VERSION "HNNBNNNYNNNNNNNNNNNNNNNNNNNNNNNNNNNNNNNNNN/4/%%%/4/'%**4NNN///"

NS_ :

BS_:

BU_: AEM BAP_Tester E_Sound FBK FLA Gateway Gateway_PAG ISE MRR_HL MRR_HR NightVision RDK SAK SAK2 SCR STH_MLBevo TopView

BO_ 1646 Klima_03: 8 Gateway
 SG_ KL_STL_aktiv : 0|1@1+ (1.0,0.0) [0.0|1] ""  STH_MLBevo
 SG_ KL_STH_aktiv : 1|1@1+ (1.0,0.0) [0.0|1] ""  STH_MLBevo
 SG_ KL_Solarluefter_aktiv : 2|1@1+ (1.0,0.0) [0.0|1] ""  Vector__XXX
 SG_ KL_Umluft_Taste : 3|1@1+ (1.0,0.0) [0.0|1] ""  Vector__XXX
 SG_ KL_Geblaese_Fond_Status : 4|4@1+ (1.0,0.0) [0.0|15] ""  Vector__XXX
 SG_ KL_STH_Ansteuerung : 8|2@1+ (1.0,0.0) [0.0|3] ""  STH_MLBevo
 SG_ KL_STH_Betriebsdauer : 10|6@1+ (1,0) [0|60] "Unit_Minut"  STH_MLBevo
 SG_ KL_Magnetventil : 16|1@1+ (1.0,0.0) [0.0|1] ""  Vector__XXX
 SG_ KL_WaPu : 17|1@1+ (1.0,0.0) [0.0|1] ""  Vector__XXX
 SG_ KL_Geblaese_Status : 18|4@1+ (1.0,0.0) [0.0|15] ""  Vector__XXX
 SG_ KL_Restwaerme_aktiv : 22|1@1+ (1.0,0.0) [0.0|1] ""  STH_MLBevo
 SG_ KL_Kompressorkupplung : 23|1@1+ (1.0,0.0) [0.0|1] ""  Vector__XXX
 SG_ KL_BCmE_Livetip_Freigabe : 24|1@1+ (1.0,0.0) [0.0|1] ""  Vector__XXX
 SG_ KL_HYB_ASV_hinten_schliessen_Anf : 25|1@1+ (1.0,0.0) [0.0|1] ""  Vector__XXX
 SG_ KL_HYB_ASV_vorne_schliessen_Anf : 26|1@1+ (1.0,0.0) [0.0|1] ""  Vector__XXX
 SG_ KL_ErwVK_Zusatzrelais : 27|1@1+ (1.0,0.0) [0.0|1] ""  Vector__XXX
 SG_ KL_Status_Beduftung : 28|1@1+ (1.0,0.0) [0.0|1] ""  Vector__XXX
 SG_ KL_Status_Ionisator_Front : 29|1@1+ (1.0,0.0) [0.0|1] ""  Vector__XXX
 SG_ KL_STH_Timer_Status : 30|1@1+ (1.0,0.0) [0.0|1] ""  Vector__XXX
 SG_ KL_ErwVK_Anf : 31|1@1+ (1.0,0.0) [0.0|1] ""  Vector__XXX
 SG_ KL_Innen_Temp : 32|8@1+ (0.5,-50) [-50.0|76.0] "Unit_DegreCelsi"  Vector__XXX
 SG_ KL_I_Geblaese_Fond : 40|8@1+ (0.25,0) [0.00|63.50] "Unit_Amper"  Vector__XXX
 SG_ KL_Anf_AussenspiegelHzg : 48|1@1+ (1.0,0.0) [0.0|1] ""  Vector__XXX
 SG_ KL_Heizkreisventilstellung : 49|2@1+ (1.0,0.0) [0.0|3] ""  Vector__XXX
 SG_ KL_FSH_Automatikbetrieb : 51|1@1+ (1.0,0.0) [0.0|1] ""  Vector__XXX
 SG_ KL_SIH_LEH_Verteilung_VL : 52|3@1+ (1.0,0.0) [0.0|7] ""  Vector__XXX
 SG_ KL_SIH_LEL_Verteilung_VL : 55|3@1+ (1.0,0.0) [0.0|7] ""  Vector__XXX
 SG_ KL_SIH_LEH_Verteilung_VR : 58|3@1+ (1.0,0.0) [0.0|7] ""  Vector__XXX
 SG_ KL_SIH_LEL_Verteilung_VR : 61|3@1+ (1.0,0.0) [0.0|7] ""  Vector__XXX

BO_ 1649 Klima_06: 8 Gateway
 SG_ KL_ZZ_Minute : 0|6@1+ (1,0) [0|59] "Unit_Minut"  STH_MLBevo
 SG_ KL_ZZ_Status_Timer : 6|2@1+ (1.0,0.0) [0.0|3] ""  STH_MLBevo
 SG_ KL_ZZ_Monat : 8|4@1+ (1,0) [1|12] "Unit_Month"  STH_MLBevo
 SG_ KL_ZZ_Stunde : 16|5@1+ (1,0) [0|23] "Unit_Hours"  STH_MLBevo
 SG_ KL_ZZ_Betriebsmodus : 21|3@1+ (1.0,0.0) [0.0|7] ""  STH_MLBevo
 SG_ KL_ZZ_Tag : 24|5@1+ (1,0) [1|31] "Unit_Day"  STH_MLBevo
 SG_ KL_Betriebsmodus_FH : 29|3@1+ (1.0,0.0) [0.0|7] ""  Vector__XXX
 SG_ KL_Stopp_Wiederstart_Anz_01 : 32|1@1+ (1.0,0.0) [0.0|1] ""  Vector__XXX
 SG_ KL_Stopp_Wiederstart_Anz_02 : 33|1@1+ (1.0,0.0) [0.0|1] ""  Vector__XXX
 SG_ KL_Stopp_Wiederstart_Anz_03 : 34|1@1+ (1.0,0.0) [0.0|1] ""  Vector__XXX
 SG_ KL_Stopp_Wiederstart_Anz_04 : 35|1@1+ (1.0,0.0) [0.0|1] ""  Vector__XXX
 SG_ KL_Stopp_Wiederstart_Anz_05 : 36|1@1+ (1.0,0.0) [0.0|1] ""  Vector__XXX
 SG_ KL_Stopp_Wiederstart_Anz_06 : 37|1@1+ (1.0,0.0) [0.0|1] ""  Vector__XXX
 SG_ KL_Stopp_Wiederstart_Anz_07 : 38|1@1+ (1.0,0.0) [0.0|1] ""  Vector__XXX
 SG_ KL_Stopp_Wiederstart_Anz_08 : 39|1@1+ (1.0,0.0) [0.0|1] ""  Vector__XXX
 SG_ KL_Stopp_Wiederstart_Anz_09 : 40|1@1+ (1.0,0.0) [0.0|1] ""  Vector__XXX
 SG_ KL_Stopp_Wiederstart_Anz_Std1 : 41|1@1+ (1.0,0.0) [0.0|1] ""  Vector__XXX
 SG_ KL_Stopp_Wiederstart_Anz_Std2 : 42|1@1+ (1.0,0.0) [0.0|1] ""  Vector__XXX

BO_ 949 Klima_11: 8 Gateway
 SG_ KL_Drehz_Anh : 0|1@1+ (1.0,0.0) [0.0|1] ""  Vector__XXX
 SG_ KL_Vorwarn_Komp_ein : 1|1@1+ (1.0,0.0) [0.0|1] ""  Vector__XXX
 SG_ KL_AC_Schalter : 2|1@1+ (1.0,0.0) [0.0|1] ""  Vector__XXX
 SG_ KL_Komp_Moment_alt : 3|1@1+ (1.0,0.0) [0.0|1] ""  Vector__XXX
 SG_ KL_Vorwarn_Zuheizer_ein : 6|1@1+ (1.0,0.0) [0.0|1] ""  Vector__XXX
 SG_ KL_Zustand : 7|1@1+ (1.0,0.0) [0.0|1] ""  Vector__XXX
 SG_ KL_Kompressorkupplung_linear : 8|8@1+ (20,0) [0|4000] "Unit_MilliAmper"  Vector__XXX
 SG_ KL_Charisma_FahrPr : 16|4@1+ (1.0,0.0) [0.0|15] ""  Vector__XXX
 SG_ KL_Charisma_Status : 20|2@1+ (1.0,0.0) [0.0|3] ""  Vector__XXX
 SG_ KL_nachtr_Stopp_Anf : 22|1@1+ (1.0,0.0) [0.0|1] ""  Vector__XXX
 SG_ KL_T_Charge : 23|1@1+ (1.0,0.0) [0.0|1] ""  Vector__XXX
 SG_ KL_Last_Kompr : 24|8@1+ (0.25,0) [0.00|63.50] "Unit_NewtoMeter"  Vector__XXX
 SG_ KL_Spannungs_Anf : 32|2@1+ (1.0,0.0) [0.0|3] ""  Vector__XXX
 SG_ KL_Thermomanagement : 34|2@1+ (1.0,0.0) [0.0|3] ""  STH_MLBevo
 SG_ KL_StartStopp_Info : 36|2@1+ (1.0,0.0) [0.0|3] ""  Vector__XXX
 SG_ KL_Freilauf_Info : 38|2@1+ (1.0,0.0) [0.0|3] ""  Vector__XXX
 SG_ KL_Anf_KL : 40|8@1+ (0.4,0) [0.0|101.6] "Unit_PerCent"  Vector__XXX
 SG_ KL_el_Zuheizer_Stufe : 48|3@1+ (1.0,0.0) [0.0|7] ""  Vector__XXX
 SG_ KL_Ausstattung_Klima : 51|3@1+ (1.0,0.0) [0.0|7] ""  Vector__XXX
 SG_ KL_Variante_Standheizung : 54|2@1+ (1.0,0.0) [0.0|3] ""  Vector__XXX

BO_ 1640 Klima_12: 8 Gateway
 SG_ KL_LRH_Taster : 0|1@1+ (1.0,0.0) [0.0|1] ""  Vector__XXX
 SG_ KL_LRH_Stufe : 1|2@1+ (1.0,0.0) [0.0|3] ""  Vector__XXX
 SG_ HSH_Taster : 3|2@1+ (1.0,0.0) [0.0|3] ""  Vector__XXX
 SG_ FSH_Taster : 5|1@1+ (1.0,0.0) [0.0|1] ""  Vector__XXX
 SG_ KL_Zuheizer_Freigabe : 6|1@1+ (1.0,0.0) [0.0|1] ""  STH_MLBevo
 SG_ KL_Beschlagsgefahr : 7|1@1+ (1.0,0.0) [0.0|1] ""  Vector__XXX
 SG_ KL_SIH_Soll_li : 8|3@1+ (1,0) [0|6] ""  Vector__XXX
 SG_ KL_SIH_Soll_re : 11|3@1+ (1,0) [0|6] ""  Vector__XXX
 SG_ KRH_Soll_li : 14|2@1+ (1.0,0.0) [0.0|3] ""  Vector__XXX
 SG_ KL_SIL_Soll_li : 16|3@1+ (1,0) [0|6] ""  Vector__XXX
 SG_ KL_SIL_Soll_re : 19|3@1+ (1,0) [0|6] ""  Vector__XXX
 SG_ KRH_Soll_re : 22|2@1+ (1.0,0.0) [0.0|3] ""  Vector__XXX
 SG_ KL_Geblspng_Soll : 24|8@1+ (0.05,1.45) [1.50|14.00] "Unit_Volt"  Vector__XXX
 SG_ KL_Geblspng_Fond_Soll : 32|8@1+ (0.05,1.45) [1.50|14.00] "Unit_Volt"  Vector__XXX
 SG_ KL_I_Geblaese : 40|8@1+ (0.25,0) [0.00|63.50] "Unit_Amper"  Vector__XXX
 SG_ KL_Kompressorstrom_soll : 48|10@1+ (1,0) [0|1021] ""  Vector__XXX
 SG_ KL_Umluftklappe_Status : 58|4@1+ (1.0,0.0) [0.0|15] ""  Vector__XXX
 SG_ KL_PTC_Verbauinfo : 62|2@1+ (1.0,0.0) [0.0|3] ""  Vector__XXX

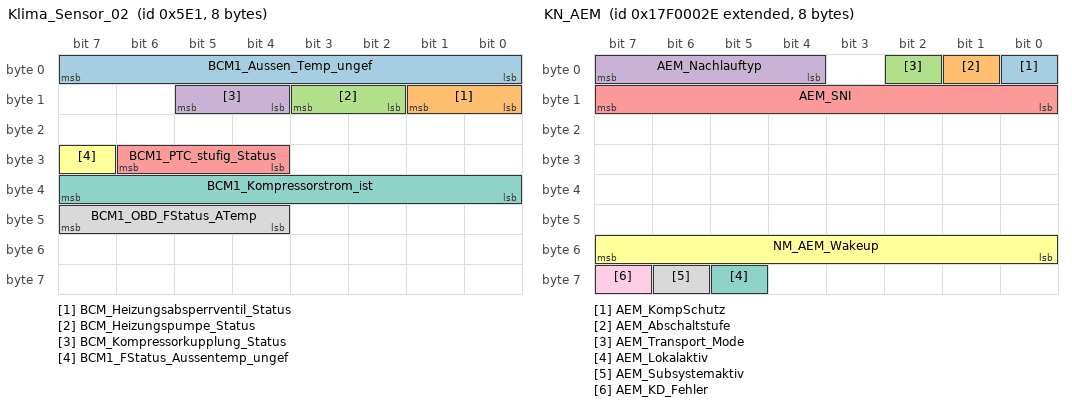
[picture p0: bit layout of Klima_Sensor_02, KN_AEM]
BO_ 1505 Klima_Sensor_02: 8 Gateway
 SG_ BCM1_Aussen_Temp_ungef : 0|8@1+ (0.5,-50) [-50.0|76.0] "Unit_DegreCelsi"  MRR_HL,STH_MLBevo,TopView
 SG_ BCM_Heizungsabsperrventil_Status : 8|2@1+ (1.0,0.0) [0.0|3] ""  Vector__XXX
 SG_ BCM_Heizungspumpe_Status : 10|2@1+ (1.0,0.0) [0.0|3] ""  Vector__XXX
 SG_ BCM_Kompressorkupplung_Status : 12|2@1+ (1.0,0.0) [0.0|3] ""  Vector__XXX
 SG_ BCM1_PTC_stufig_Status : 28|3@1+ (1.0,0.0) [0.0|7] ""  Vector__XXX
 SG_ BCM1_FStatus_Aussentemp_ungef : 31|1@1+ (1.0,0.0) [0.0|1] ""  Vector__XXX
 SG_ BCM1_Kompressorstrom_ist : 32|8@1+ (4,0) [0|1000] "Unit_MilliAmper"  Vector__XXX
 SG_ BCM1_OBD_FStatus_ATemp : 44|4@1+ (1.0,0.0) [0.0|15] ""  Vector__XXX

BO_ 2549088302 KN_AEM: 8 AEM
 SG_ AEM_KompSchutz : 0|1@1+ (1.0,0.0) [0.0|1] ""  Vector__XXX
 SG_ AEM_Abschaltstufe : 1|1@1+ (1.0,0.0) [0.0|1] ""  Vector__XXX
 SG_ AEM_Transport_Mode : 2|1@1+ (1.0,0.0) [0.0|1] ""  Vector__XXX
 SG_ AEM_Nachlauftyp : 4|4@1+ (1.0,0.0) [0.0|15] ""  Gateway,Gateway_PAG
 SG_ AEM_SNI : 8|8@1+ (1.0,0.0) [0.0|255] ""  Gateway,Gateway_PAG
 SG_ NM_AEM_Wakeup : 48|8@1+ (1.0,0.0) [0.0|255] ""  Vector__XXX
 SG_ AEM_Lokalaktiv : 61|1@1+ (1.0,0.0) [0.0|1] ""  Gateway,Gateway_PAG
 SG_ AEM_Subsystemaktiv : 62|1@1+ (1.0,0.0) [0.0|1] ""  Vector__XXX
 SG_ AEM_KD_Fehler : 63|1@1+ (1.0,0.0) [0.0|1] ""  Gateway,Gateway_PAG

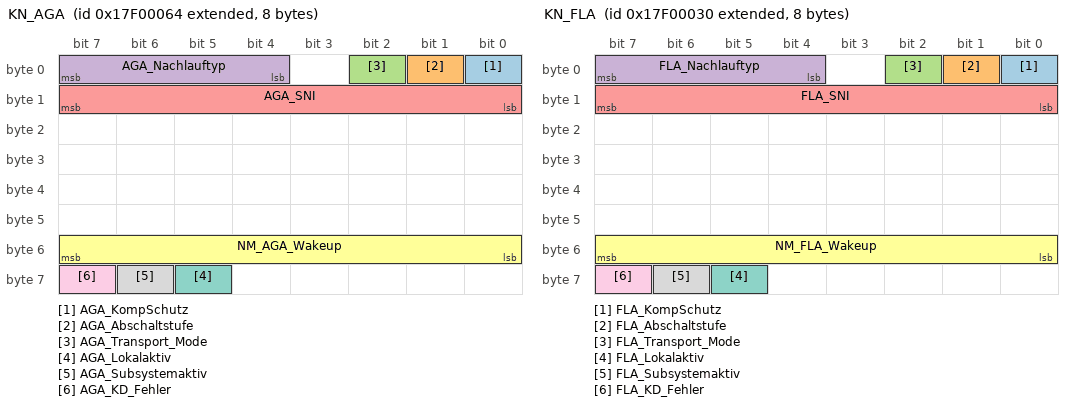
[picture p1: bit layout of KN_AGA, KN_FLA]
BO_ 2549088356 KN_AGA: 8 E_Sound
 SG_ AGA_KompSchutz : 0|1@1+ (1.0,0.0) [0.0|1] ""  Vector__XXX
 SG_ AGA_Abschaltstufe : 1|1@1+ (1.0,0.0) [0.0|1] ""  Vector__XXX
 SG_ AGA_Transport_Mode : 2|1@1+ (1.0,0.0) [0.0|1] ""  Vector__XXX
 SG_ AGA_Nachlauftyp : 4|4@1+ (1.0,0.0) [0.0|15] ""  Gateway,Gateway_PAG
 SG_ AGA_SNI : 8|8@1+ (1.0,0.0) [0.0|255] ""  Gateway,Gateway_PAG
 SG_ NM_AGA_Wakeup : 48|8@1+ (1.0,0.0) [0.0|255] ""  Vector__XXX
 SG_ AGA_Lokalaktiv : 61|1@1+ (1.0,0.0) [0.0|1] ""  Vector__XXX
 SG_ AGA_Subsystemaktiv : 62|1@1+ (1.0,0.0) [0.0|1] ""  Vector__XXX
 SG_ AGA_KD_Fehler : 63|1@1+ (1.0,0.0) [0.0|1] ""  Gateway,Gateway_PAG

BO_ 2549088304 KN_FLA: 8 FLA
 SG_ FLA_KompSchutz : 0|1@1+ (1.0,0.0) [0.0|1] ""  Vector__XXX
 SG_ FLA_Abschaltstufe : 1|1@1+ (1.0,0.0) [0.0|1] ""  Vector__XXX
 SG_ FLA_Transport_Mode : 2|1@1+ (1.0,0.0) [0.0|1] ""  Vector__XXX
 SG_ FLA_Nachlauftyp : 4|4@1+ (1.0,0.0) [0.0|15] ""  Gateway,Gateway_PAG
 SG_ FLA_SNI : 8|8@1+ (1.0,0.0) [0.0|255] ""  Gateway,Gateway_PAG
 SG_ NM_FLA_Wakeup : 48|8@1+ (1.0,0.0) [0.0|255] ""  Vector__XXX
 SG_ FLA_Lokalaktiv : 61|1@1+ (1.0,0.0) [0.0|1] ""  Vector__XXX
 SG_ FLA_Subsystemaktiv : 62|1@1+ (1.0,0.0) [0.0|1] ""  Vector__XXX
 SG_ FLA_KD_Fehler : 63|1@1+ (1.0,0.0) [0.0|1] ""  Gateway,Gateway_PAG

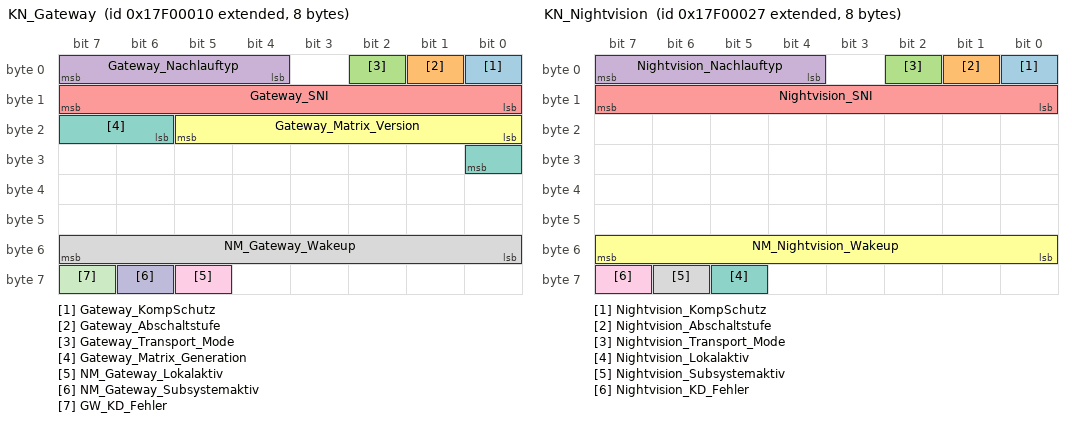
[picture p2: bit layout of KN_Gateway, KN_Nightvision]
BO_ 2549088272 KN_Gateway: 8 Gateway
 SG_ Gateway_KompSchutz : 0|1@1+ (1.0,0.0) [0.0|1] ""  Vector__XXX
 SG_ Gateway_Abschaltstufe : 1|1@1+ (1.0,0.0) [0.0|1] ""  Vector__XXX
 SG_ Gateway_Transport_Mode : 2|1@1+ (1.0,0.0) [0.0|1] ""  Vector__XXX
 SG_ Gateway_Nachlauftyp : 4|4@1+ (1.0,0.0) [0.0|15] ""  Vector__XXX
 SG_ Gateway_SNI : 8|8@1+ (1.0,0.0) [0.0|255] ""  Vector__XXX
 SG_ Gateway_Matrix_Version : 16|6@1+ (1,0) [0|63] "Unit_None"  Vector__XXX
 SG_ Gateway_Matrix_Generation : 22|3@1+ (1,0) [0|7] "Unit_None"  Vector__XXX
 SG_ NM_Gateway_Wakeup : 48|8@1+ (1.0,0.0) [0.0|255] ""  Vector__XXX
 SG_ NM_Gateway_Lokalaktiv : 61|1@1+ (1.0,0.0) [0.0|1] ""  Vector__XXX
 SG_ NM_Gateway_Subsystemaktiv : 62|1@1+ (1.0,0.0) [0.0|1] ""  Vector__XXX
 SG_ GW_KD_Fehler : 63|1@1+ (1.0,0.0) [0.0|1] ""  Vector__XXX

BO_ 2549088295 KN_Nightvision: 8 NightVision
 SG_ Nightvision_KompSchutz : 0|1@1+ (1.0,0.0) [0.0|1] ""  Vector__XXX
 SG_ Nightvision_Abschaltstufe : 1|1@1+ (1.0,0.0) [0.0|1] ""  Vector__XXX
 SG_ Nightvision_Transport_Mode : 2|1@1+ (1.0,0.0) [0.0|1] ""  Vector__XXX
 SG_ Nightvision_Nachlauftyp : 4|4@1+ (1.0,0.0) [0.0|15] ""  Gateway,Gateway_PAG
 SG_ Nightvision_SNI : 8|8@1+ (1.0,0.0) [0.0|255] ""  Gateway,Gateway_PAG
 SG_ NM_Nightvision_Wakeup : 48|8@1+ (1.0,0.0) [0.0|255] ""  Vector__XXX
 SG_ Nightvision_Lokalaktiv : 61|1@1+ (1.0,0.0) [0.0|1] ""  Vector__XXX
 SG_ Nightvision_Subsystemaktiv : 62|1@1+ (1.0,0.0) [0.0|1] ""  Vector__XXX
 SG_ Nightvision_KD_Fehler : 63|1@1+ (1.0,0.0) [0.0|1] ""  Gateway,Gateway_PAG

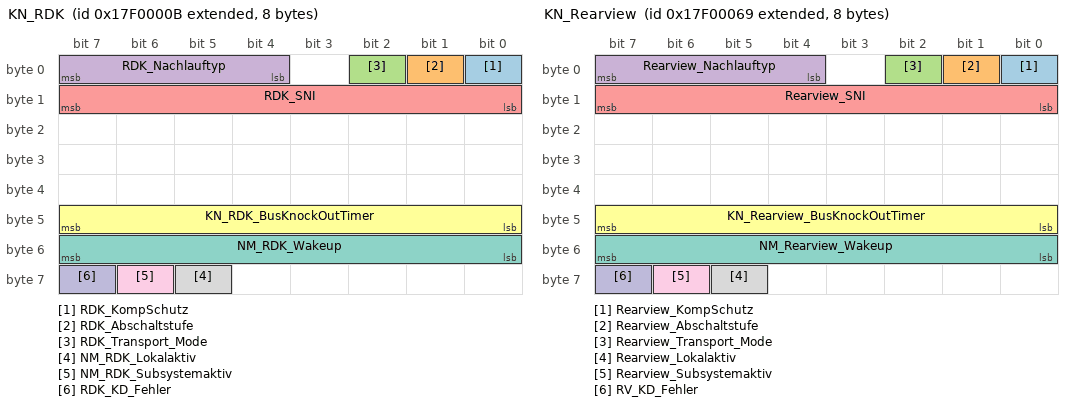
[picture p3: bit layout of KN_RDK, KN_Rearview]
BO_ 2549088267 KN_RDK: 8 RDK
 SG_ RDK_KompSchutz : 0|1@1+ (1.0,0.0) [0.0|1] ""  Vector__XXX
 SG_ RDK_Abschaltstufe : 1|1@1+ (1.0,0.0) [0.0|1] ""  Vector__XXX
 SG_ RDK_Transport_Mode : 2|1@1+ (1.0,0.0) [0.0|1] ""  Vector__XXX
 SG_ RDK_Nachlauftyp : 4|4@1+ (1.0,0.0) [0.0|15] ""  Gateway,Gateway_PAG
 SG_ RDK_SNI : 8|8@1+ (1.0,0.0) [0.0|255] ""  Gateway,Gateway_PAG
 SG_ KN_RDK_BusKnockOutTimer : 40|8@1+ (1,0) [0|254] ""  Gateway,Gateway_PAG
 SG_ NM_RDK_Wakeup : 48|8@1+ (1.0,0.0) [0.0|255] ""  Vector__XXX
 SG_ NM_RDK_Lokalaktiv : 61|1@1+ (1.0,0.0) [0.0|1] ""  Gateway,Gateway_PAG
 SG_ NM_RDK_Subsystemaktiv : 62|1@1+ (1.0,0.0) [0.0|1] ""  Vector__XXX
 SG_ RDK_KD_Fehler : 63|1@1+ (1.0,0.0) [0.0|1] ""  Gateway,Gateway_PAG

BO_ 2549088361 KN_Rearview: 8 TopView
 SG_ Rearview_KompSchutz : 0|1@1+ (1.0,0.0) [0.0|1] ""  Vector__XXX
 SG_ Rearview_Abschaltstufe : 1|1@1+ (1.0,0.0) [0.0|1] ""  Vector__XXX
 SG_ Rearview_Transport_Mode : 2|1@1+ (1.0,0.0) [0.0|1] ""  Vector__XXX
 SG_ Rearview_Nachlauftyp : 4|4@1+ (1.0,0.0) [0.0|15] ""  Gateway,Gateway_PAG
 SG_ Rearview_SNI : 8|8@1+ (1.0,0.0) [0.0|255] ""  Gateway,Gateway_PAG
 SG_ KN_Rearview_BusKnockOutTimer : 40|8@1+ (1,0) [0|254] ""  Gateway,Gateway_PAG
 SG_ NM_Rearview_Wakeup : 48|8@1+ (1.0,0.0) [0.0|255] ""  Vector__XXX
 SG_ Rearview_Lokalaktiv : 61|1@1+ (1.0,0.0) [0.0|1] ""  Gateway,Gateway_PAG
 SG_ Rearview_Subsystemaktiv : 62|1@1+ (1.0,0.0) [0.0|1] ""  Vector__XXX
 SG_ RV_KD_Fehler : 63|1@1+ (1.0,0.0) [0.0|1] ""  Gateway,Gateway_PAG

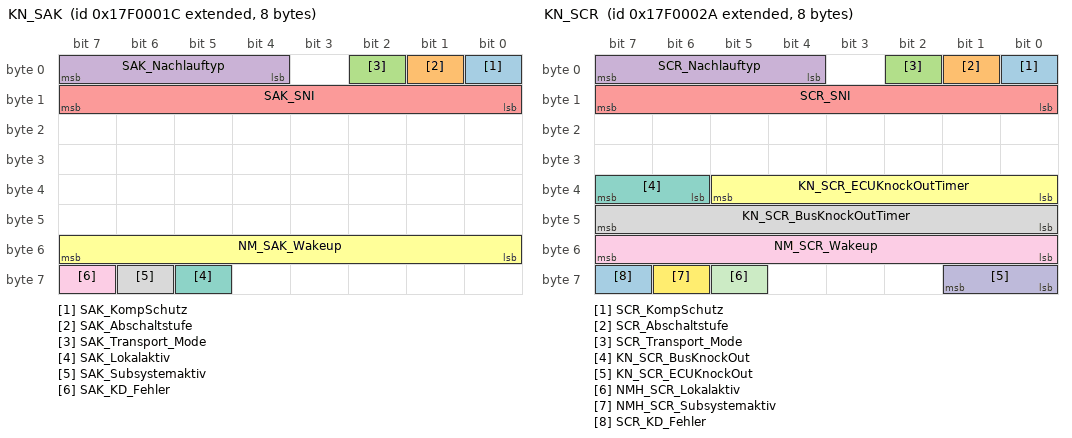
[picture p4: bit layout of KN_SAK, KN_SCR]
BO_ 2549088284 KN_SAK: 8 ISE
 SG_ SAK_KompSchutz : 0|1@1+ (1.0,0.0) [0.0|1] ""  Vector__XXX
 SG_ SAK_Abschaltstufe : 1|1@1+ (1.0,0.0) [0.0|1] ""  Vector__XXX
 SG_ SAK_Transport_Mode : 2|1@1+ (1.0,0.0) [0.0|1] ""  Vector__XXX
 SG_ SAK_Nachlauftyp : 4|4@1+ (1.0,0.0) [0.0|15] ""  Gateway,Gateway_PAG
 SG_ SAK_SNI : 8|8@1+ (1.0,0.0) [0.0|255] ""  Gateway,Gateway_PAG
 SG_ NM_SAK_Wakeup : 48|8@1+ (1.0,0.0) [0.0|255] ""  Vector__XXX
 SG_ SAK_Lokalaktiv : 61|1@1+ (1.0,0.0) [0.0|1] ""  Vector__XXX
 SG_ SAK_Subsystemaktiv : 62|1@1+ (1.0,0.0) [0.0|1] ""  Vector__XXX
 SG_ SAK_KD_Fehler : 63|1@1+ (1.0,0.0) [0.0|1] ""  Gateway,Gateway_PAG

BO_ 2549088298 KN_SCR: 8 SCR
 SG_ SCR_KompSchutz : 0|1@1+ (1.0,0.0) [0.0|1] ""  Vector__XXX
 SG_ SCR_Abschaltstufe : 1|1@1+ (1.0,0.0) [0.0|1] ""  Vector__XXX
 SG_ SCR_Transport_Mode : 2|1@1+ (1.0,0.0) [0.0|1] ""  Vector__XXX
 SG_ SCR_Nachlauftyp : 4|4@1+ (1.0,0.0) [0.0|15] ""  Gateway,Gateway_PAG
 SG_ SCR_SNI : 8|8@1+ (1.0,0.0) [0.0|255] ""  Gateway,Gateway_PAG
 SG_ KN_SCR_ECUKnockOutTimer : 32|6@1+ (1,0) [0|62] ""  Vector__XXX
 SG_ KN_SCR_BusKnockOut : 38|2@1+ (1.0,0.0) [0.0|3] ""  Vector__XXX
 SG_ KN_SCR_BusKnockOutTimer : 40|8@1+ (1,0) [0|254] ""  Gateway,Gateway_PAG
 SG_ NM_SCR_Wakeup : 48|8@1+ (1.0,0.0) [0.0|255] ""  Vector__XXX
 SG_ KN_SCR_ECUKnockOut : 56|2@1+ (1.0,0.0) [0.0|3] ""  Vector__XXX
 SG_ NMH_SCR_Lokalaktiv : 61|1@1+ (1.0,0.0) [0.0|1] ""  Gateway,Gateway_PAG
 SG_ NMH_SCR_Subsystemaktiv : 62|1@1+ (1.0,0.0) [0.0|1] ""  Vector__XXX
 SG_ SCR_KD_Fehler : 63|1@1+ (1.0,0.0) [0.0|1] ""  Gateway,Gateway_PAG

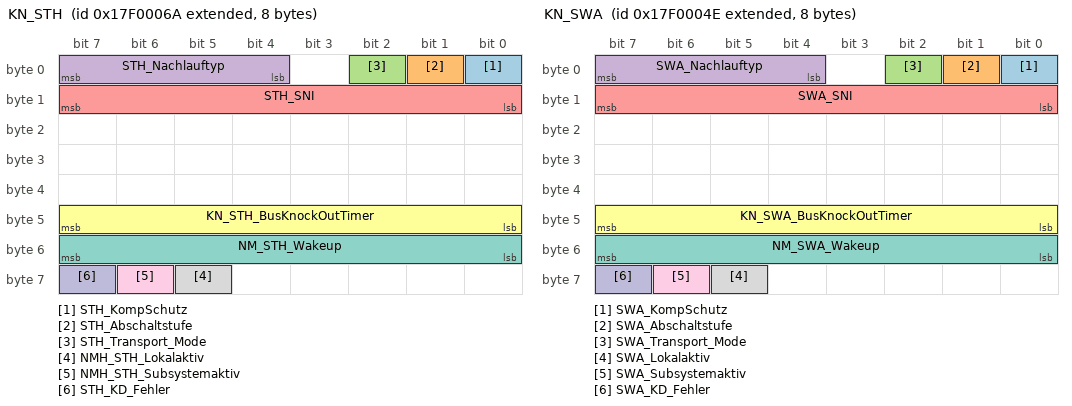
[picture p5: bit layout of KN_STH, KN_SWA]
BO_ 2549088362 KN_STH: 8 STH_MLBevo
 SG_ STH_KompSchutz : 0|1@1+ (1.0,0.0) [0.0|1] ""  Vector__XXX
 SG_ STH_Abschaltstufe : 1|1@1+ (1.0,0.0) [0.0|1] ""  Vector__XXX
 SG_ STH_Transport_Mode : 2|1@1+ (1.0,0.0) [0.0|1] ""  Vector__XXX
 SG_ STH_Nachlauftyp : 4|4@1+ (1.0,0.0) [0.0|15] ""  Gateway,Gateway_PAG
 SG_ STH_SNI : 8|8@1+ (1.0,0.0) [0.0|255] ""  Gateway,Gateway_PAG
 SG_ KN_STH_BusKnockOutTimer : 40|8@1+ (1,0) [0|254] ""  Gateway,Gateway_PAG
 SG_ NM_STH_Wakeup : 48|8@1+ (1.0,0.0) [0.0|255] ""  Vector__XXX
 SG_ NMH_STH_Lokalaktiv : 61|1@1+ (1.0,0.0) [0.0|1] ""  Gateway,Gateway_PAG
 SG_ NMH_STH_Subsystemaktiv : 62|1@1+ (1.0,0.0) [0.0|1] ""  Gateway,Gateway_PAG
 SG_ STH_KD_Fehler : 63|1@1+ (1.0,0.0) [0.0|1] ""  Gateway,Gateway_PAG

BO_ 2549088334 KN_SWA: 8 MRR_HR
 SG_ SWA_KompSchutz : 0|1@1+ (1.0,0.0) [0.0|1] ""  Vector__XXX
 SG_ SWA_Abschaltstufe : 1|1@1+ (1.0,0.0) [0.0|1] ""  Vector__XXX
 SG_ SWA_Transport_Mode : 2|1@1+ (1.0,0.0) [0.0|1] ""  Vector__XXX
 SG_ SWA_Nachlauftyp : 4|4@1+ (1.0,0.0) [0.0|15] ""  Gateway,Gateway_PAG
 SG_ SWA_SNI : 8|8@1+ (1.0,0.0) [0.0|255] ""  Gateway,Gateway_PAG
 SG_ KN_SWA_BusKnockOutTimer : 40|8@1+ (1,0) [0|254] ""  Gateway,Gateway_PAG
 SG_ NM_SWA_Wakeup : 48|8@1+ (1.0,0.0) [0.0|255] ""  Vector__XXX
 SG_ SWA_Lokalaktiv : 61|1@1+ (1.0,0.0) [0.0|1] ""  Gateway,Gateway_PAG
 SG_ SWA_Subsystemaktiv : 62|1@1+ (1.0,0.0) [0.0|1] ""  Vector__XXX
 SG_ SWA_KD_Fehler : 63|1@1+ (1.0,0.0) [0.0|1] ""  Gateway,Gateway_PAG

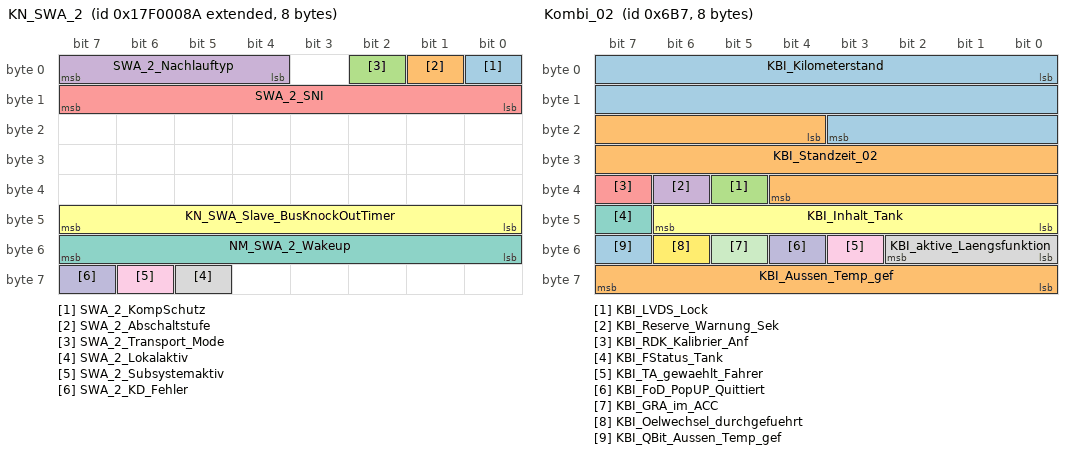
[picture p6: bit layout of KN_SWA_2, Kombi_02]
BO_ 2549088394 KN_SWA_2: 8 MRR_HL
 SG_ SWA_2_KompSchutz : 0|1@1+ (1.0,0.0) [0.0|1] ""  Vector__XXX
 SG_ SWA_2_Abschaltstufe : 1|1@1+ (1.0,0.0) [0.0|1] ""  Vector__XXX
 SG_ SWA_2_Transport_Mode : 2|1@1+ (1.0,0.0) [0.0|1] ""  Vector__XXX
 SG_ SWA_2_Nachlauftyp : 4|4@1+ (1.0,0.0) [0.0|15] ""  Gateway,Gateway_PAG
 SG_ SWA_2_SNI : 8|8@1+ (1.0,0.0) [0.0|255] ""  Gateway,Gateway_PAG
 SG_ KN_SWA_Slave_BusKnockOutTimer : 40|8@1+ (1,0) [0|254] ""  Gateway,Gateway_PAG
 SG_ NM_SWA_2_Wakeup : 48|8@1+ (1.0,0.0) [0.0|255] ""  Vector__XXX
 SG_ SWA_2_Lokalaktiv : 61|1@1+ (1.0,0.0) [0.0|1] ""  Gateway,Gateway_PAG
 SG_ SWA_2_Subsystemaktiv : 62|1@1+ (1.0,0.0) [0.0|1] ""  Vector__XXX
 SG_ SWA_2_KD_Fehler : 63|1@1+ (1.0,0.0) [0.0|1] ""  Gateway,Gateway_PAG

BO_ 779 Kombi_01: 8 Gateway
 SG_ KBI_ABS_Lampe : 0|1@1+ (1.0,0.0) [0.0|1] ""  Vector__XXX
 SG_ KBI_ESP_Lampe : 1|1@1+ (1.0,0.0) [0.0|1] ""  TopView
 SG_ KBI_BKL_Lampe : 2|1@1+ (1.0,0.0) [0.0|1] ""  Vector__XXX
 SG_ KBI_Airbag_Lampe : 3|1@1+ (1.0,0.0) [0.0|1] ""  Vector__XXX
 SG_ KBI_SILA_gueltig : 4|1@1+ (1.0,0.0) [0.0|1] ""  Vector__XXX
 SG_ KBI_Lenkung_Lampe : 5|1@1+ (1,0) [0|1] ""  Vector__XXX
 SG_ KBI_Vorglueh_System_Lampe : 6|1@1+ (1.0,0.0) [0.0|1] ""  Vector__XXX
 SG_ KBI_NV_in_Anzeige : 7|1@1+ (1.0,0.0) [0.0|1] ""  NightVision
 SG_ Kombi_01_BZ : 8|4@1+ (1,0) [0|15] ""  Vector__XXX
 SG_ KBI_Anzeigestatus_ACC : 12|1@1+ (1.0,0.0) [0.0|1] ""  Vector__XXX
 SG_ KBI_Anzeigestatus_GRA : 13|2@1+ (1.0,0.0) [0.0|3] ""  Vector__XXX
 SG_ KBI_Tankwarnung : 16|1@1+ (1.0,0.0) [0.0|1] ""  STH_MLBevo
 SG_ KBI_MFA_v_Einheit_01 : 17|1@1+ (1.0,0.0) [0.0|1] ""  RDK
 SG_ KBI_im_Stellgliedtest : 18|1@1+ (1.0,0.0) [0.0|1] ""  Vector__XXX
 SG_ KBI_Anzeigefehler_LDW : 19|2@1+ (1.0,0.0) [0.0|3] ""  Vector__XXX
 SG_ KBI_Tankwarnung_ungueltig : 21|1@1+ (1.0,0.0) [0.0|1] ""  Vector__XXX
 SG_ KBI_Handbremse : 23|1@1+ (1.0,0.0) [0.0|1] ""  Vector__XXX
 SG_ KBI_V_Digital : 24|9@1+ (1,0) [0|511] ""  MRR_HL,MRR_HR,RDK
 SG_ KBI_PLA_in_Anzeige : 33|1@1+ (1.0,0.0) [0.0|1] ""  Vector__XXX
 SG_ KBI_Anzeigefehler_NV : 34|1@1+ (1.0,0.0) [0.0|1] ""  NightVision
 SG_ KBI_Anzeigestatus_LIM : 35|2@1+ (1.0,0.0) [0.0|3] ""  Vector__XXX
 SG_ KBI_ARA_in_Anzeige : 37|1@1+ (1.0,0.0) [0.0|1] ""  Vector__XXX
 SG_ KBI_Taster_Lift : 38|1@1+ (1.0,0.0) [0.0|1] ""  Vector__XXX
 SG_ KBI_Taster_Fahrwerk : 39|1@1+ (1.0,0.0) [0.0|1] ""  Vector__XXX
 SG_ KBI_GRA_Hauptschalter : 40|2@1+ (1.0,0.0) [0.0|3] ""  Vector__XXX
 SG_ KBI_Bestaetigung_ESP_Off : 42|2@1+ (1.0,0.0) [0.0|3] ""  Vector__XXX
 SG_ KBI_angez_Geschw : 48|10@1+ (0.32,0) [0.00|325.12] "Unit_KiloMeterPerHour"  MRR_HL,MRR_HR
 SG_ KBI_Einheit_Tacho : 58|1@1+ (1.0,0.0) [0.0|1] ""  Vector__XXX
 SG_ KBI_Konsistenz_ACC : 59|1@1+ (1.0,0.0) [0.0|1] ""  Vector__XXX
 SG_ KBI_Fehler_Anzeige_ACC : 60|1@1+ (1.0,0.0) [0.0|1] ""  Vector__XXX
 SG_ KBI_Anzeigefehler_SWA : 61|2@1+ (1.0,0.0) [0.0|3] ""  MRR_HR
 SG_ KBI_Systemstatus : 63|1@1+ (1.0,0.0) [0.0|1] ""  Vector__XXX

BO_ 1719 Kombi_02: 8 Gateway
 SG_ KBI_Kilometerstand : 0|20@1+ (1,0) [0|1048573] "Unit_KiloMeter"  Vector__XXX
 SG_ KBI_Standzeit_02 : 20|17@1+ (1,0) [0|131068] "Unit_Secon"  STH_MLBevo
 SG_ KBI_LVDS_Lock : 37|1@1+ (1.0,0.0) [0.0|1] ""  Vector__XXX
 SG_ KBI_Reserve_Warnung_Sek : 38|1@1+ (1.0,0.0) [0.0|1] ""  Vector__XXX
 SG_ KBI_RDK_Kalibrier_Anf : 39|1@1+ (1.0,0.0) [0.0|1] ""  RDK
 SG_ KBI_Inhalt_Tank : 40|7@1+ (1,0) [0|125] "Unit_Liter"  STH_MLBevo
 SG_ KBI_FStatus_Tank : 47|1@1+ (1.0,0.0) [0.0|1] ""  STH_MLBevo
 SG_ KBI_aktive_Laengsfunktion : 48|3@1+ (1.0,0.0) [0.0|7] ""  Vector__XXX
 SG_ KBI_TA_gewaehlt_Fahrer : 51|1@1+ (1.0,0.0) [0.0|1] ""  Vector__XXX
 SG_ KBI_FoD_PopUP_Quittiert : 52|1@1+ (1.0,0.0) [0.0|1] ""  Vector__XXX
 SG_ KBI_GRA_im_ACC : 53|1@1+ (1.0,0.0) [0.0|1] ""  Vector__XXX
 SG_ KBI_Oelwechsel_durchgefuehrt : 54|1@1+ (1.0,0.0) [0.0|1] ""  Vector__XXX
 SG_ KBI_QBit_Aussen_Temp_gef : 55|1@1+ (1.0,0.0) [0.0|1] ""  NightVision,RDK,STH_MLBevo
 SG_ KBI_Aussen_Temp_gef : 56|8@1+ (0.5,-50) [-50.0|75.0] "Unit_DegreCelsi"  AEM,NightVision,RDK,SAK2,SCR,STH_MLBevo

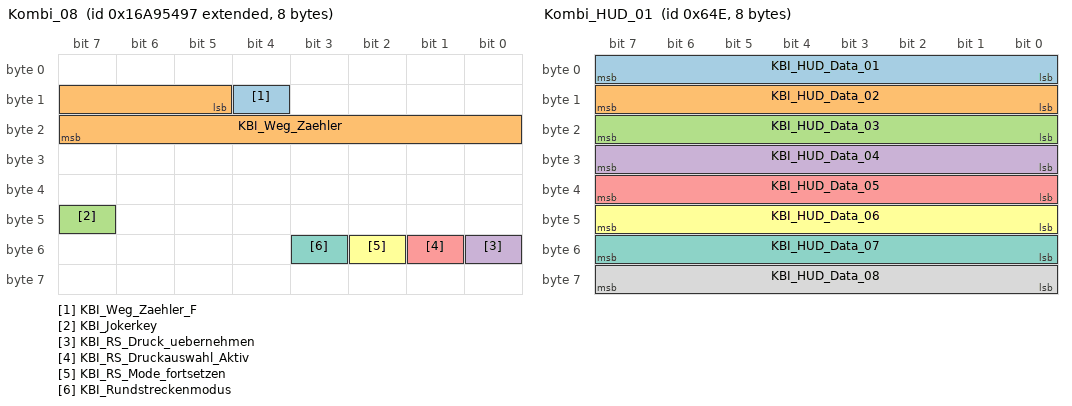
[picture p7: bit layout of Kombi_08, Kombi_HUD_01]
BO_ 2527679639 Kombi_08: 8 Gateway
 SG_ KBI_Weg_Zaehler_F : 12|1@1+ (1.0,0.0) [0.0|1] ""  Vector__XXX
 SG_ KBI_Weg_Zaehler : 13|11@1+ (1,0) [0|2047] "Unit_Meter"  Vector__XXX
 SG_ KBI_Jokerkey : 47|1@1+ (1.0,0.0) [0.0|1] ""  Vector__XXX
 SG_ KBI_RS_Druck_uebernehmen : 48|1@1+ (1.0,0.0) [0.0|1] ""  RDK
 SG_ KBI_RS_Druckauswahl_Aktiv : 49|1@1+ (1.0,0.0) [0.0|1] ""  RDK
 SG_ KBI_RS_Mode_fortsetzen : 50|1@1+ (1.0,0.0) [0.0|1] ""  RDK
 SG_ KBI_Rundstreckenmodus : 51|1@1+ (1.0,0.0) [0.0|1] ""  RDK

BO_ 1614 Kombi_HUD_01: 8 Gateway
 SG_ KBI_HUD_Data_01 : 0|8@1+ (1.0,0.0) [0.0|255] ""  NightVision
 SG_ KBI_HUD_Data_02 : 8|8@1+ (1.0,0.0) [0.0|255] ""  NightVision
 SG_ KBI_HUD_Data_03 : 16|8@1+ (1.0,0.0) [0.0|255] ""  NightVision
 SG_ KBI_HUD_Data_04 : 24|8@1+ (1.0,0.0) [0.0|255] ""  NightVision
 SG_ KBI_HUD_Data_05 : 32|8@1+ (1.0,0.0) [0.0|255] ""  NightVision
 SG_ KBI_HUD_Data_06 : 40|8@1+ (1.0,0.0) [0.0|255] ""  NightVision
 SG_ KBI_HUD_Data_07 : 48|8@1+ (1.0,0.0) [0.0|255] ""  NightVision
 SG_ KBI_HUD_Data_08 : 56|8@1+ (1.0,0.0) [0.0|255] ""  NightVision

BO_ 2549874983 KS_Nightvision_Req: 8 Gateway
 SG_ KS_Nightvision_Req_Data : 0|64@1+ (1.0,0.0) [0.0|18446744073709551615] ""  NightVision

BO_ 2550006055 KS_Nightvision_Resp: 8 NightVision
 SG_ KS_Nightvision_Resp_Data : 0|64@1+ (1.0,0.0) [0.0|18446744073709551615] ""  Gateway,Gateway_PAG

BO_ 2549875082 KS_SWA_2_Req: 8 Gateway
 SG_ KS_SWA_2_Req_Data : 0|64@1+ (1.0,0.0) [0.0|18446744073709551615] ""  MRR_HL

BO_ 2550006154 KS_SWA_2_Resp: 8 MRR_HL
 SG_ KS_SWA_2_Resp_Data : 0|64@1+ (1.0,0.0) [0.0|18446744073709551615] ""  Gateway,Gateway_PAG

BO_ 2549875022 KS_SWA_Req: 8 Gateway
 SG_ KS_SWA_Req_Data : 0|64@1+ (1.0,0.0) [0.0|18446744073709551615] ""  MRR_HR

BO_ 2550006094 KS_SWA_Resp: 8 MRR_HR
 SG_ KS_SWA_Resp_Data : 0|64@1+ (1.0,0.0) [0.0|18446744073709551615] ""  Gateway,Gateway_PAG

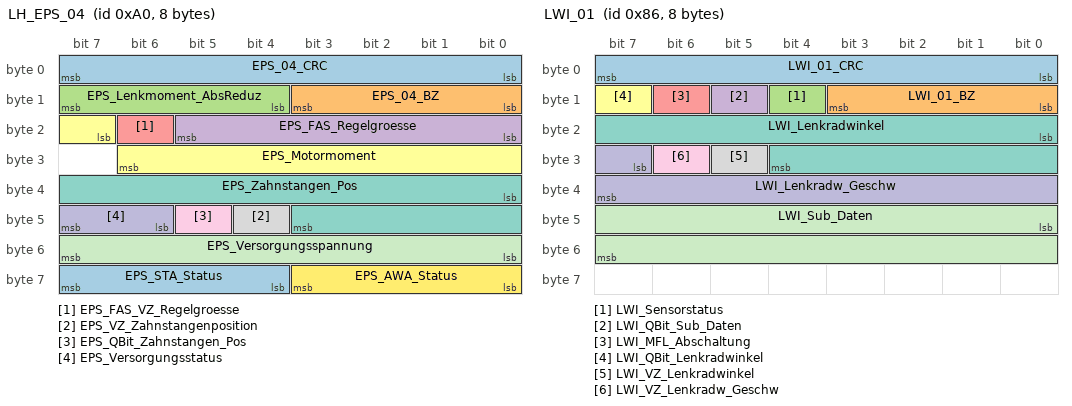
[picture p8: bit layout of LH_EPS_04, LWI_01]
BO_ 160 LH_EPS_04: 8 Gateway
 SG_ EPS_04_CRC : 0|8@1+ (1,0) [0|255] ""  Vector__XXX
 SG_ EPS_04_BZ : 8|4@1+ (1,0) [0|15] ""  Vector__XXX
 SG_ EPS_Lenkmoment_AbsReduz : 12|4@1+ (0.62,0.61) [0.61|8.05] "Unit_NewtoMeter"  TopView
 SG_ EPS_FAS_Regelgroesse : 16|6@1+ (2,0) [0|100] "Unit_PerCent"  Vector__XXX
 SG_ EPS_FAS_VZ_Regelgroesse : 22|1@1+ (1.0,0.0) [0.0|1] ""  Vector__XXX
 SG_ EPS_Motormoment : 23|8@1+ (0.2,-16.2) [-16.0|16.0] "Unit_NewtoMeter"  Vector__XXX
 SG_ EPS_Zahnstangen_Pos : 32|12@1+ (0.02,0) [0.00|81.86] "Unit_MilliMeter"  TopView
 SG_ EPS_VZ_Zahnstangenposition : 44|1@1+ (1.0,0.0) [0.0|1] ""  TopView
 SG_ EPS_QBit_Zahnstangen_Pos : 45|1@1+ (1.0,0.0) [0.0|1] ""  TopView
 SG_ EPS_Versorgungsstatus : 46|2@1+ (1.0,0.0) [0.0|3] ""  Vector__XXX
 SG_ EPS_Versorgungsspannung : 48|8@1+ (0.05,5.05) [5.05|17.70] "Unit_Volt"  Vector__XXX
 SG_ EPS_AWA_Status : 56|4@1+ (1.0,0.0) [0.0|15] ""  Vector__XXX
 SG_ EPS_STA_Status : 60|4@1+ (1.0,0.0) [0.0|15] ""  Vector__XXX

BO_ 981 Licht_Anf_01: 8 Gateway
 SG_ Licht_Anf_01_CRC : 0|8@1+ (1,0) [0|255] ""  Vector__XXX
 SG_ Licht_Anf_01_BZ : 8|4@1+ (1,0) [0|15] ""  Vector__XXX
 SG_ BCM1_Kurvenlicht_links_Anf : 12|1@1+ (1.0,0.0) [0.0|1] ""  Vector__XXX
 SG_ BCM1_Kurvenlicht_rechts_Anf : 13|1@1+ (1.0,0.0) [0.0|1] ""  Vector__XXX
 SG_ BCM1_Standlicht_Anf : 14|1@1+ (1.0,0.0) [0.0|1] ""  Vector__XXX
 SG_ BCM1_Abblendlicht_Anf : 15|1@1+ (1.0,0.0) [0.0|1] ""  Vector__XXX
 SG_ BCM1_Fernlicht_Anf : 16|1@1+ (1.0,0.0) [0.0|1] ""  Vector__XXX
 SG_ BCM1_Nebellicht_Anf : 17|1@1+ (1.0,0.0) [0.0|1] ""  Vector__XXX
 SG_ BCM1_Parklicht_li_Anf : 18|1@1+ (1.0,0.0) [0.0|1] ""  Vector__XXX
 SG_ BCM1_Parklicht_re_Anf : 19|1@1+ (1.0,0.0) [0.0|1] ""  Vector__XXX
 SG_ BCM1_Nebelschluss_Ahg_Anf : 20|1@1+ (1.0,0.0) [0.0|1] ""  Vector__XXX
 SG_ BCM1_Nebelschluss_Fzg_Anf : 21|1@1+ (1.0,0.0) [0.0|1] ""  Vector__XXX
 SG_ BCM1_Schlusslicht_Anf : 22|1@1+ (1.0,0.0) [0.0|1] ""  Vector__XXX
 SG_ BCM_Rueckfahrlicht_Anf : 23|1@1+ (1.0,0.0) [0.0|1] ""  TopView
 SG_ BCM1_Signaturlicht_Anf : 24|1@1+ (1.0,0.0) [0.0|1] ""  Vector__XXX
 SG_ BCM1_Umfeldleuchten_Anf : 25|1@1+ (1.0,0.0) [0.0|1] ""  Vector__XXX
 SG_ BCM1_Tagfahrlicht_Anf : 26|1@1+ (1.0,0.0) [0.0|1] ""  Vector__XXX
 SG_ BCM1_Regenlicht_Anf : 27|1@1+ (1.0,0.0) [0.0|1] ""  Vector__XXX
 SG_ BCM1_Autobahnlicht_Anf : 28|1@1+ (1.0,0.0) [0.0|1] ""  Vector__XXX
 SG_ BCM1_Touristen_Licht_Anf : 29|1@1+ (1.0,0.0) [0.0|1] ""  Vector__XXX
 SG_ BCM1_CH_aktiv : 30|1@1+ (1.0,0.0) [0.0|1] ""  Vector__XXX
 SG_ BCM1_LH_aktiv : 31|1@1+ (1.0,0.0) [0.0|1] ""  Vector__XXX
 SG_ BCM1_Gleitende_Leuchtw_Anf : 32|1@1+ (1.0,0.0) [0.0|1] ""  Vector__XXX
 SG_ BCM1_GLW_Fernlicht_Anf : 33|1@1+ (1.0,0.0) [0.0|1] ""  Vector__XXX
 SG_ BCM1_Adaptive_Lichtvert_Anf : 34|1@1+ (1.0,0.0) [0.0|1] ""  Vector__XXX
 SG_ BCM1_FoD_Sperrung_WiBli : 35|2@1+ (1.0,0.0) [0.0|3] ""  Vector__XXX
 SG_ BCM1_FOD_Sperrung_Animationen_HL : 37|2@1+ (1.0,0.0) [0.0|3] ""  Vector__XXX
 SG_ BCM1_Animationssperrung : 39|1@1+ (1.0,0.0) [0.0|1] ""  Vector__XXX
 SG_ BCM1_CH_LH_aktiv : 40|1@1+ (1.0,0.0) [0.0|1] ""  Vector__XXX
 SG_ BCM1_Allwetterlicht_Anf : 41|1@1+ (1.0,0.0) [0.0|1] ""  Vector__XXX
 SG_ BCM1_Schlusslicht_Signatur : 60|4@1+ (1.0,0.0) [0.0|15] ""  Vector__XXX

BO_ 1624 Licht_vorne_01: 8 Gateway
 SG_ Licht_Vorne_01_CRC : 0|8@1+ (1,0) [0|255] ""  Vector__XXX
 SG_ Licht_Vorne_01_BZ : 8|4@1+ (1,0) [0|15] ""  Vector__XXX
 SG_ LV_Standlicht_Anzeige : 12|1@1+ (1.0,0.0) [0.0|1] ""  Vector__XXX
 SG_ LV_Abblendlicht_Anzeige : 13|1@1+ (1.0,0.0) [0.0|1] ""  FLA,NightVision
 SG_ LV_Fernlicht_Anzeige : 14|1@1+ (1.0,0.0) [0.0|1] ""  FLA
 SG_ LV_Nebellicht_Anzeige : 15|1@1+ (1.0,0.0) [0.0|1] ""  FLA
 SG_ LV_Nebelschlusslicht_Anzeige : 16|1@1+ (1.0,0.0) [0.0|1] ""  Vector__XXX
 SG_ LV_Tagfahrlicht_Anzeige : 17|1@1+ (1.0,0.0) [0.0|1] ""  Vector__XXX
 SG_ LV_AFL_aktiv_Anzeige : 18|1@1+ (1.0,0.0) [0.0|1] ""  Vector__XXX
 SG_ LV_AFL_defekt : 19|1@1+ (1.0,0.0) [0.0|1] ""  Vector__XXX
 SG_ LV_Blinker_li_def : 20|1@1+ (1.0,0.0) [0.0|1] ""  Vector__XXX
 SG_ LV_Standlicht_li_def : 21|1@1+ (1.0,0.0) [0.0|1] ""  Vector__XXX
 SG_ LV_Abblendlicht_li_def : 22|1@1+ (1.0,0.0) [0.0|1] ""  NightVision
 SG_ LV_Fernlicht_li_def : 23|1@1+ (1.0,0.0) [0.0|1] ""  Vector__XXX
 SG_ LV_Nebellicht_li_def : 24|1@1+ (1.0,0.0) [0.0|1] ""  Vector__XXX
 SG_ LV_Blk_li_Seite_def : 25|1@1+ (1.0,0.0) [0.0|1] ""  Vector__XXX
 SG_ LV_Tagfahrlicht_li_def : 26|1@1+ (1.0,0.0) [0.0|1] ""  Vector__XXX
 SG_ LV_FLA_aktiv_Anzeige : 27|1@1+ (1.0,0.0) [0.0|1] ""  Vector__XXX
 SG_ LV_FLA_defekt : 28|1@1+ (1.0,0.0) [0.0|1] ""  Vector__XXX
 SG_ LV_FLA_Sensor_blockiert : 29|1@1+ (1.0,0.0) [0.0|1] ""  Vector__XXX
 SG_ LV_Blinker_re_def : 30|1@1+ (1.0,0.0) [0.0|1] ""  Vector__XXX
 SG_ LV_Standlicht_re_def : 31|1@1+ (1.0,0.0) [0.0|1] ""  Vector__XXX
 SG_ LV_Abblendlicht_re_def : 32|1@1+ (1.0,0.0) [0.0|1] ""  NightVision
 SG_ LV_Fernlicht_re_def : 33|1@1+ (1.0,0.0) [0.0|1] ""  Vector__XXX
 SG_ LV_Nebellicht_re_def : 34|1@1+ (1.0,0.0) [0.0|1] ""  Vector__XXX
 SG_ LV_Blk_re_Seite_def : 35|1@1+ (1.0,0.0) [0.0|1] ""  Vector__XXX
 SG_ LV_Tagfahrlicht_re_def : 36|1@1+ (1.0,0.0) [0.0|1] ""  Vector__XXX
 SG_ LV_Aussenlicht_def : 37|1@1+ (1.0,0.0) [0.0|1] ""  Vector__XXX
 SG_ LV_Abblendlicht_TFL_li_def : 38|1@1+ (1.0,0.0) [0.0|1] ""  Vector__XXX
 SG_ LV_Nebellicht_TFL_li_def : 39|1@1+ (1.0,0.0) [0.0|1] ""  Vector__XXX
 SG_ LV_Standlicht_TFL_li_def : 40|1@1+ (1.0,0.0) [0.0|1] ""  Vector__XXX
 SG_ LV_Abblend_Fernlicht_li_def : 41|1@1+ (1.0,0.0) [0.0|1] ""  Vector__XXX
 SG_ LV_Abblendlicht_TFL_re_def : 42|1@1+ (1.0,0.0) [0.0|1] ""  Vector__XXX
 SG_ LV_Nebellicht_TFL_re_def : 43|1@1+ (1.0,0.0) [0.0|1] ""  Vector__XXX
 SG_ LV_Standlicht_TFL_re_def : 44|1@1+ (1.0,0.0) [0.0|1] ""  Vector__XXX
 SG_ LV_Abblend_Fernlicht_re_def : 45|1@1+ (1.0,0.0) [0.0|1] ""  Vector__XXX
 SG_ LV_Abbiegelicht_li_def : 46|1@1+ (1.0,0.0) [0.0|1] ""  Vector__XXX
 SG_ LV_Abbiegelicht_re_def : 47|1@1+ (1.0,0.0) [0.0|1] ""  Vector__XXX
 SG_ BCM1_Linksverkehr : 48|1@1+ (1.0,0.0) [0.0|1] ""  Vector__XXX
 SG_ BCM1_Licht_Dunkelheit_aktiv : 49|1@1+ (1.0,0.0) [0.0|1] ""  NightVision
 SG_ LV_LED_Scheinwerfer_li_def : 50|1@1+ (1.0,0.0) [0.0|1] ""  Vector__XXX
 SG_ LV_LED_Scheinwerfer_re_def : 51|1@1+ (1.0,0.0) [0.0|1] ""  Vector__XXX
 SG_ LV_Blinker_VL_aktiv : 52|1@1+ (1.0,0.0) [0.0|1] ""  Vector__XXX
 SG_ LV_Blinker_VR_aktiv : 53|1@1+ (1.0,0.0) [0.0|1] ""  Vector__XXX
 SG_ LV_MXB_Status_Anzeige : 54|2@1+ (1.0,0.0) [0.0|3] ""  Vector__XXX

BO_ 134 LWI_01: 8 Gateway
 SG_ LWI_01_CRC : 0|8@1+ (1,0) [0|255] ""  Vector__XXX
 SG_ LWI_01_BZ : 8|4@1+ (1,0) [0|15] ""  Vector__XXX
 SG_ LWI_Sensorstatus : 12|1@1+ (1.0,0.0) [0.0|1] ""  Vector__XXX
 SG_ LWI_QBit_Sub_Daten : 13|1@1+ (1.0,0.0) [0.0|1] ""  Vector__XXX
 SG_ LWI_MFL_Abschaltung : 14|1@1+ (1.0,0.0) [0.0|1] ""  Vector__XXX
 SG_ LWI_QBit_Lenkradwinkel : 15|1@1+ (1.0,0.0) [0.0|1] ""  FBK
 SG_ LWI_Lenkradwinkel : 16|13@1+ (0.1,0) [0.0|800.0] "Unit_DegreOfArc"  FBK
 SG_ LWI_VZ_Lenkradwinkel : 29|1@1+ (1.0,0.0) [0.0|1] ""  FBK
 SG_ LWI_VZ_Lenkradw_Geschw : 30|1@1+ (1.0,0.0) [0.0|1] ""  Vector__XXX
 SG_ LWI_Lenkradw_Geschw : 31|9@1+ (5,0) [0|2500] "Unit_DegreOfArcPerSecon"  Vector__XXX
 SG_ LWI_Sub_Daten : 40|16@1+ (1,0) [0|65535] ""  Vector__XXX

BO_TX_BU_ 1646 :Gateway,Gateway_PAG;
BO_TX_BU_ 1649 :Gateway,Gateway_PAG;
BO_TX_BU_ 949 :Gateway,Gateway_PAG;
BO_TX_BU_ 1640 :Gateway,Gateway_PAG;
BO_TX_BU_ 1505 :Gateway,Gateway_PAG;
BO_TX_BU_ 2549088356 :E_Sound,SAK2;
BO_TX_BU_ 2549088272 :Gateway,Gateway_PAG;
BO_TX_BU_ 2549088284 :ISE,SAK;
BO_TX_BU_ 779 :Gateway,Gateway_PAG;
BO_TX_BU_ 1719 :Gateway,Gateway_PAG;
BO_TX_BU_ 2527679639 :Gateway,Gateway_PAG;
BO_TX_BU_ 1614 :Gateway,Gateway_PAG;
BO_TX_BU_ 2549874983 :Gateway,Gateway_PAG;
BO_TX_BU_ 2549875082 :Gateway,Gateway_PAG;
BO_TX_BU_ 2549875022 :Gateway,Gateway_PAG;
BO_TX_BU_ 160 :Gateway,Gateway_PAG;
BO_TX_BU_ 981 :Gateway,Gateway_PAG;
BO_TX_BU_ 1624 :Gateway,Gateway_PAG;
BO_TX_BU_ 134 :Gateway,Gateway_PAG;
CM_ BO_ 1646 "ab MQB 7.3";
CM_ BO_ 949 "ab MQB 7.4";
CM_ BO_ 1640 "ab MQB IS-4";
CM_ BO_ 1505 "ab MQB 7.3";
CM_ BO_ 779 "MQB";
CM_ BO_ 134 "ab MQB mit CRC in Byte 1";

CM_ SG_ 1646 KL_Anf_AussenspiegelHzg "Anforderung Außenspiegelheizung seitens Klimafunktion (z.B. bei Erweiterter VoKo)";
CM_ SG_ 1646 KL_BCmE_Livetip_Freigabe "Status der Klimaanlage. 
Zeigt an, ob der Livetip 'Fenster schließen wegen Ineffizienz Klimaanlage' sinvollerweise angezeigt werden soll";
CM_ SG_ 1646 KL_ErwVK_Anf "Erweiterte Voko angefordertert / aktiv";
CM_ SG_ 1646 KL_ErwVK_Zusatzrelais "Steuerung Zusatzrelais für Erweiterte Voko";
CM_ SG_ 1646 KL_FSH_Automatikbetrieb "Ermöglicht eine Unterscheidung von Anforderung FSH durch Kundenwunsch und Anforderung FSH durch Regelung des Klimasteuergeräts.
Das Signal liegt als Pegel an.";
CM_ SG_ 1646 KL_Geblaese_Fond_Status "Status Geblaese









";
CM_ SG_ 1646 KL_Geblaese_Status "Status Geblaese









";
CM_ SG_ 1646 KL_Heizkreisventilstellung "Bei MQB PHEV: Stellung Heizkreisventil Motor";
CM_ SG_ 1646 KL_HYB_ASV_hinten_schliessen_Anf "Anforderung der Klima an das BMS, das Absperrventil des Kältemittelkreislaufs zur Batteriekühlung zu schliessen";
CM_ SG_ 1646 KL_HYB_ASV_vorne_schliessen_Anf "Anforderung der Klima an das BMS, das Absperrventil des Kältemittelkreislaufs der Klimaanlage zu schliessen";
CM_ SG_ 1646 KL_I_Geblaese_Fond "Stromaufnahme Gebläse Heck";
CM_ SG_ 1646 KL_Innen_Temp "Innentemperatur

";
CM_ SG_ 1646 KL_Kompressorkupplung "Signal zur Aktivierung/Deaktivierung der Kompressorkupplung";
CM_ SG_ 1646 KL_Magnetventil "Anforderung des Bypassventils.";
CM_ SG_ 1646 KL_Restwaerme_aktiv "Signal zur Aktivierung/Deaktivierung der Wasserpumpe bei Restwärme; 
reduzierte IRÜ Empfindlichkeit";
CM_ SG_ 1646 KL_SIH_LEH_Verteilung_VL "Vom Kunden eingestellte Aufteilung der Heizleistung auf Sitzfläche und Lehnefläche für Sitz vorne links";
CM_ SG_ 1646 KL_SIH_LEH_Verteilung_VR "Vom Kunden eingestellte Aufteilung der Heizleistung auf Sitzfläche und Lehnefläche für Sitz vorne rechts";
CM_ SG_ 1646 KL_SIH_LEL_Verteilung_VL "Vom Kunden eingestellte Aufteilung der Lüftungsleistung auf Sitzfläche und Lehnenfläche für Sitz vorne links";
CM_ SG_ 1646 KL_SIH_LEL_Verteilung_VR "Vom Kunden eingestellte Aufteilung der Lüftungsleistung auf Sitzfläche und Lehnenfläche für Sitz vorne rechts";
CM_ SG_ 1646 KL_Solarluefter_aktiv "Betriebsstatus Solarluefter
";
CM_ SG_ 1646 KL_Status_Beduftung "Status der Beduftung";
CM_ SG_ 1646 KL_Status_Ionisator_Front "Status des Ionisator Front";
CM_ SG_ 1646 KL_STH_aktiv "Betriebsstatus Standheizung
";
CM_ SG_ 1646 KL_STH_Ansteuerung "Ansteuerung STH

";
CM_ SG_ 1646 KL_STH_Betriebsdauer "Betriebsdauer STH";
CM_ SG_ 1646 KL_STH_Timer_Status "Status des Standheizungstimers (für VW621 initial zur Übermittelung der Information von KlimaMSB zu Kombi)
Zur Anzeige im Kombi für 10 Sekunden nach Kl.15 aus;";
CM_ SG_ 1646 KL_STL_aktiv "Betriebsstatus Standlueftung
";
CM_ SG_ 1646 KL_Umluft_Taste "Betaetigung Umlufttaste
";
CM_ SG_ 1646 KL_WaPu "Ansteuerung der Standheizungswasserpumpe";

CM_ SG_ 1649 KL_Betriebsmodus_FH "Synchronisation des Betriebsmodus zwischen Front und Fond";
CM_ SG_ 1649 KL_Stopp_Wiederstart_Anz_01 "Dieses Signal gibt die detaillierte Begründung für eine Stoppverbot-/Wiederstartanfrage der Klima-SG an.";
CM_ SG_ 1649 KL_Stopp_Wiederstart_Anz_02 "Dieses Signal gibt die detaillierte Begründung für eine Stoppverbot-/Wiederstartanfrage der Klima-SG an.";
CM_ SG_ 1649 KL_Stopp_Wiederstart_Anz_03 "Dieses Signal gibt die detaillierte Begründung für eine Stoppverbot-/Wiederstartanfrage der Klima-SG an.";
CM_ SG_ 1649 KL_Stopp_Wiederstart_Anz_04 "Dieses Signal gibt die detaillierte Begründung für eine Stoppverbot-/Wiederstartanfrage der Klima-SG an.";
CM_ SG_ 1649 KL_Stopp_Wiederstart_Anz_05 "Dieses Signal gibt die detaillierte Begründung für eine Stoppverbot-/Wiederstartanfrage der Klima-SG an.";
CM_ SG_ 1649 KL_Stopp_Wiederstart_Anz_06 "Dieses Signal gibt die detaillierte Begründung für eine Stoppverbot-/Wiederstartanfrage der Klima-SG an.";
CM_ SG_ 1649 KL_Stopp_Wiederstart_Anz_07 "Dieses Signal gibt die detaillierte Begründung für eine Stoppverbot-/Wiederstartanfrage der Klima-SG an.";
CM_ SG_ 1649 KL_Stopp_Wiederstart_Anz_08 "Dieses Signal gibt die detaillierte Begründung für eine Stoppverbot-/Wiederstartanfrage der Klima-SG an.";
CM_ SG_ 1649 KL_Stopp_Wiederstart_Anz_09 "Dieses Signal gibt die detaillierte Begründung für eine Stoppverbot-/Wiederstartanfrage der Klima-SG an.";
CM_ SG_ 1649 KL_Stopp_Wiederstart_Anz_Std1 "Dieses Signal gibt die detaillierte Begründung für eine Stoppverbot-/Wiederstartanfrage der Klima-SG an.";
CM_ SG_ 1649 KL_Stopp_Wiederstart_Anz_Std2 "Dieses Signal gibt die detaillierte Begründung für eine Stoppverbot-/Wiederstartanfrage der Klima-SG an.";
CM_ SG_ 1649 KL_ZZ_Betriebsmodus "Betriebsdauerberechnung anhand Aussentemperaturauswertung mit Faktor 'ZZ_Betriebsmodus'";
CM_ SG_ 1649 KL_ZZ_Minute "Zielzeittimeranzeige im Display der Funkfernbedienung (Minute); Initwert ist der zuletzt gültige Wert";
CM_ SG_ 1649 KL_ZZ_Monat "Zielzeittimeranzeige im Display der Funkfernbedienung (Datum, Monat); Initwert ist der zuletzt gültige Wert";
CM_ SG_ 1649 KL_ZZ_Status_Timer "Timerstatusanzeige im Display der Funkfernbedienung (Timer aktiv/n.aktiv)";
CM_ SG_ 1649 KL_ZZ_Stunde "Zielzeittimeranzeige im Display der Funkfernbedienung (Stunde); Initwert ist der zuletzt gültige Wert";
CM_ SG_ 1649 KL_ZZ_Tag "Zielzeittimeranzeige im Display der Funkfernbedienung (Datum, Tag); Initwert ist der zuletzt gültige Wert";

CM_ SG_ 949 KL_AC_Schalter "AC Schalter
";
CM_ SG_ 949 KL_Anf_KL "Anforderung Kühlerlüfter der Klimaanlage in Prozent

";
CM_ SG_ 949 KL_Ausstattung_Klima "Austtattungsart der Klimabedienung";
CM_ SG_ 949 KL_Charisma_FahrPr "MLBevo: Aktuelles Fahrprogramm des Charisma-Teilnehmers (siehe Systemlastenheft Drive Select)
MQB: Istwert der Kennlinie (siehe Systemlastenheft MQB FPA)";
CM_ SG_ 949 KL_Charisma_Status "Charisma Systemstatus des Charisma-Teilnehmers

Wert 0x3 ist nur für Fahrzeuge ab MQB relevant";
CM_ SG_ 949 KL_Drehz_Anh "Drehzahlanhebung vom Motor angefordert

";
CM_ SG_ 949 KL_el_Zuheizer_Stufe "Vorgabe für Motorsteuergeraet PTC-Stufe; im MLB-B8 und MQB nur Stufe 0...3

";
CM_ SG_ 949 KL_Freilauf_Info "Freilauf Informationssignal von Klima zum Freilaufkoordinator. Klima kann über dieses Signal den Freilauf freigeben, verhindern bzw. explizit anfordern.";
CM_ SG_ 949 KL_Kompressorkupplung_linear "Sollwert zur Ansteuerung der Kompressorkupplung";
CM_ SG_ 949 KL_Last_Kompr "Aktuelles Verlustmoment der Klimaanlage bezogen auf die Kurbelwelle. Wird der Klimakompressor nicht angesteuert, ist das Schleppmoment bezogen auf die Kurbelwelle zu senden.";
CM_ SG_ 949 KL_nachtr_Stopp_Anf "Dieses Signal dient dem Motor als Trigger, dass ein nachträglicher Motorstopp eingeleitet werden kann, wenn es die Bedingungen des StSt Koordinators dies zulassen. ";
CM_ SG_ 949 KL_Spannungs_Anf "Forderung des Klima-SG's zur Spannungsanhebung.";
CM_ SG_ 949 KL_StartStopp_Info "Stopp-Freigabe und Start-Anforderung an den Start-Stopp-Koordinator";
CM_ SG_ 949 KL_T_Charge "Signal für Tastenbetätigung Charge-Taste (SOC Increasing)";
CM_ SG_ 949 KL_Thermomanagement "Stufen des Thermomanagements;
Bei Klemme 15 AUS und erkannten Timeout zum Klimabedienteil (z.B. Klimabedienteil während des Motorsteuergeräte-Kommunikations-Nachlaufs bereits im NM-Zustand ¿Bus Sleep¿)
erfolgt keine Ansteuerung der Wasserpumpe durch die";
CM_ SG_ 949 KL_Variante_Standheizung "Identifikation der Variante der Standheizungen zur Berechnung der energetischen Zielzeit";
CM_ SG_ 949 KL_Vorwarn_Komp_ein "Vorwarnung Kompressor ein; 140ms vorher; Information für Motor zum Aufbau Momentenreserve";
CM_ SG_ 949 KL_Vorwarn_Zuheizer_ein "Vorwarnung Zuheizerbetrieb
";
CM_ SG_ 949 KL_Zustand "Beschreibt den Zustand des Klima-/Heizungsbedienteils. (OFF-Mode Bedienteil)

PAG (MLB): Beschreibt den Zustand des Kompressors";

CM_ SG_ 1640 FSH_Taster "Tasterbetätigung Frontscheibenheizung
";
CM_ SG_ 1640 HSH_Taster "An-/Abforderung Heckscheibenheizung über spezielles Tastersignal
";
CM_ SG_ 1640 KL_Beschlagsgefahr "Beschlagsgefahr auf der Frontscheibe im Bereich des Spiegelfusses. Dient zur präventiven Ansteuerung der  Kamera-Scheibenheizung, um Kamera-Blindheit zu vermeiden
PHEV: volle Leistungsfreigabe 
HV Heizer und HV EKK bei Scheibenbeschlag ";
CM_ SG_ 1640 KL_Geblspng_Fond_Soll "Ausgabe des Sollwertes für die Spannung des Klimagebläsemotores hinten.






";
CM_ SG_ 1640 KL_Geblspng_Soll "Ausgabe des Sollwertes für die Spannung des Klimagebläsemotores vorne.







";
CM_ SG_ 1640 KL_I_Geblaese "Stromaufnahme Gebläse";
CM_ SG_ 1640 KL_Kompressorstrom_soll "Sollvorgabe Klima-Kompressorstrom";
CM_ SG_ 1640 KL_LRH_Stufe "Eingestellte Temperaturstufe der Lenkradheizung";
CM_ SG_ 1640 KL_LRH_Taster "Tasterbetätigung Lenkradheizung";
CM_ SG_ 1640 KL_PTC_Verbauinfo "Im Klima- bzw. Heizungsbedienteil wird der Verbau eines PTCs und dessen elektr. Leistungsklasse codiert";
CM_ SG_ 1640 KL_SIH_Soll_li "Einstellung Sitzheizung Fahrer (0...6)";
CM_ SG_ 1640 KL_SIH_Soll_re "Einstellung Sitzheizung Beifahrer (0...6)";
CM_ SG_ 1640 KL_SIL_Soll_li "Einstellung Sitzlüftung Fahrer (0...6)";
CM_ SG_ 1640 KL_SIL_Soll_re "Einstellung Sitzlüftung Beifahrer (0...6)";
CM_ SG_ 1640 KL_Umluftklappe_Status "Status Umluftklappe";
CM_ SG_ 1640 KL_Zuheizer_Freigabe "Freigabe Zuheizer
";
CM_ SG_ 1640 KRH_Soll_li "Ausgabe des Sollwertes für die Kopfraumheizung links.";
CM_ SG_ 1640 KRH_Soll_re "Ausgabe des Sollwertes für die Kopfraumheizung rechts.";

CM_ SG_ 1505 BCM1_Aussen_Temp_ungef "ungefilterter Wert des Aussentemperatursensors
";
CM_ SG_ 1505 BCM1_FStatus_Aussentemp_ungef "Fehlerstatus für Aussentemperatur (Kombianzeige)";
CM_ SG_ 1505 BCM1_Kompressorstrom_ist "IST-Strom vom Klima-Kompressor";
CM_ SG_ 1505 BCM1_OBD_FStatus_ATemp "Fehlerstatus Umgebungstemperatursensor (OBD relevanter Sensor)
";
CM_ SG_ 1505 BCM1_PTC_stufig_Status "Status des BCM1-Heizverbrauchers PTC (stufig)";
CM_ SG_ 1505 BCM_Heizungsabsperrventil_Status "Das Signal beschreibt den Zustand des Heizungsabsperrventils, welches als Portexpander vom BCM1 elektrisch angesteuert wird.";
CM_ SG_ 1505 BCM_Heizungspumpe_Status "Das Signal beschreibt den Zustand der Heizungspumpe, welche als Portexpander vom BCM1 elektrisch angesteuert wird.";
CM_ SG_ 1505 BCM_Kompressorkupplung_Status "Das Signal beschreibt den Zustand der Klimakompressorkupplung, welche als Portexpander vom BCM1 elektrisch angesteuert wird.";

CM_ SG_ 2549088302 AEM_Abschaltstufe "Funktionseinschränkung aufgrund aktiver Abschaltstufe";
CM_ SG_ 2549088302 AEM_KD_Fehler "Bei gesetztem Bit ist mindestens ein Kundendienstfehler eingetragen";
CM_ SG_ 2549088302 AEM_KompSchutz "Funktionseinschränkung aufgrund Komponentenschutz aktiv";
CM_ SG_ 2549088302 AEM_Lokalaktiv "Zeigt an ob das SG nach Klemme15 AUS und nach entsprechender MAX Aktivzeit noch aktiv war";
CM_ SG_ 2549088302 AEM_Nachlauftyp "Abgebildet wird die von der Hardware vorgegebene Möglichkeit, die Kommunikation nach Klemme 15 = AUS aufrecht zu erhalten. Es wird ein Init-Wert gesendet.";
CM_ SG_ 2549088302 AEM_SNI "Das Signal beinhaltet den Source Node Identifier (Knotenadresse, die auch in der Abbildungsvorschrift zur CAN-ID für die NM-High Botschaft verwendet wird).";
CM_ SG_ 2549088302 AEM_Subsystemaktiv "Zeigt an ob ein Subsystem des SGs nach Klemme15 AUS und nach entsprechender MAX Aktivzeit noch aktiv war";
CM_ SG_ 2549088302 AEM_Transport_Mode "Funktionseinschränkung aufgrund aktivem Transport Mode und/oder Transport Schutz";
CM_ SG_ 2549088302 NM_AEM_Wakeup "enthält die Weckursache; stehen mehrere Weckursachen parallel an, dann muss der kleinste Wert übertragen werden";

CM_ SG_ 2549088356 AGA_Abschaltstufe "Funktionseinschränkung aufgrund aktiver Abschaltstufe";
CM_ SG_ 2549088356 AGA_KD_Fehler "Bei gesetztem Bit ist mindestens ein Kundendienstfehler eingetragen";
CM_ SG_ 2549088356 AGA_KompSchutz "Funktionseinschränkung aufgrund Komponentenschutz aktiv";
CM_ SG_ 2549088356 AGA_Lokalaktiv "Zeigt an ob das SG nach Klemme15 AUS und nach entsprechender MAX Aktivzeit noch aktiv war";
CM_ SG_ 2549088356 AGA_Nachlauftyp "Abgebildet wird die von der Hardware vorgegebene Möglichkeit, die Kommunikation nach Klemme 15 = AUS aufrecht zu erhalten. Es wird ein Init-Wert gesendet.
0 = Kommunikation nur bei KL15=EIN (kein Nachlauf, nicht weckfähig)
1 = Kommunikation nach KL15=AU";
CM_ SG_ 2549088356 AGA_SNI "Das Signal beinhaltet den Source Node Identifier (Knotenadresse, die auch in der Abbildungsvorschrift zur CAN-ID für die NM-High Botschaft verwendet wird).";
CM_ SG_ 2549088356 AGA_Subsystemaktiv "Zeigt an ob ein Subsystem des SGs nach Klemme15 AUS und nach entsprechender MAX Aktivzeit noch aktiv war";
CM_ SG_ 2549088356 AGA_Transport_Mode "Funktionseinschränkung aufgrund aktivem Transport Mode und/oder Transport Schutz";
CM_ SG_ 2549088356 NM_AGA_Wakeup "enthält die Weckursache; stehen mehrere Weckursachen parallel an, dann muss der kleinste Wert übertragen werden";

CM_ SG_ 2549088304 FLA_Abschaltstufe "Funktionseinschränkung aufgrund aktiver Abschaltstufe";
CM_ SG_ 2549088304 FLA_KD_Fehler "Kundendienstfehlerbit FLA";
CM_ SG_ 2549088304 FLA_KompSchutz "Funktionseinschränkung aufgrund Komponentenschutz aktiv";
CM_ SG_ 2549088304 FLA_Lokalaktiv "Zeigt an ob das SG nach Klemme15 AUS und nach entsprechender MAX Aktivzeit noch aktiv war";
CM_ SG_ 2549088304 FLA_Nachlauftyp "Abgebildet wird die von der Hardware vorgegebene Möglichkeit, die Kommunikation nach Klemme 15 = AUS aufrecht zu erhalten. Es wird ein Init-Wert gesendet.
0 = Kommunikation nur bei KL15=EIN (kein Nachlauf, nicht weckfähig)
1 = Kommunikation nach KL15=AU";
CM_ SG_ 2549088304 FLA_SNI "Das Signal beinhaltet den Source Node Identifier (Knotenadresse, die auch in der Abbildungsvorschrift zur CAN-ID für die NM-High Botschaft verwendet wird).";
CM_ SG_ 2549088304 FLA_Subsystemaktiv "Zeigt an ob ein Subsystem des SGs nach Klemme15 AUS und nach entsprechender MAX Aktivzeit noch aktiv war";
CM_ SG_ 2549088304 FLA_Transport_Mode "Funktionseinschränkung aufgrund aktivem Transport Mode und/oder Transport Schutz";
CM_ SG_ 2549088304 NM_FLA_Wakeup "enthält die Weckursache; stehen mehrere Weckursachen parallel an, dann muss der kleinste Wert übertragen werden";

CM_ SG_ 2549088272 Gateway_Abschaltstufe "Funktionseinschränkung aufgrund aktiver Abschaltstufe";
CM_ SG_ 2549088272 Gateway_KompSchutz "Funktionseinschränkung aufgrund Komponentenschutz aktiv";
CM_ SG_ 2549088272 Gateway_Matrix_Generation "Signal gibt an welche Matrix-Generation umgesetzt ist";
CM_ SG_ 2549088272 Gateway_Matrix_Version "Signal gibt an welche Matrix-Version des Baukasten umgesetzt ist.
z.B. V.08.xx, das Signal gibt den Wert für xx an";
CM_ SG_ 2549088272 Gateway_Nachlauftyp "Abgebildet wird die von der Hardware vorgegebene Möglichkeit, die Kommunikation nach Klemme 15 = AUS aufrecht zu erhalten. Es wird ein Init-Wert gesendet.";
CM_ SG_ 2549088272 Gateway_SNI "Das Signal beinhaltet den Source Node Identifier (Knotenadresse, die auch in der Abbildungsvorschrift zur CAN-ID für die NM-High Botschaft verwendet wird).";
CM_ SG_ 2549088272 Gateway_Transport_Mode "Funktionseinschränkung aufgrund aktivem Transport Mode und/oder Transport Schutz";
CM_ SG_ 2549088272 GW_KD_Fehler "Kundendienstfehlerbit Gateway zur Anzeige eines im Gateway abgelegten Fehlerspeichereintrages.";
CM_ SG_ 2549088272 NM_Gateway_Lokalaktiv "Zeigt an ob das SG nach Klemme15 AUS und nach entsprechender MAX Aktivzeit noch aktiv war.";
CM_ SG_ 2549088272 NM_Gateway_Subsystemaktiv "Zeigt an ob ein Subsystem des SGs nach Klemme15 AUS und nach entsprechender MAX Aktivzeit noch aktiv war";
CM_ SG_ 2549088272 NM_Gateway_Wakeup "enthält die Weckursache; stehen mehrere Weckursachen parallel an, dann muss der kleinste Wert übertragen werden";

CM_ SG_ 2549088295 Nightvision_Abschaltstufe "Funktionseinschränkung aufgrund aktiver Abschaltstufe";
CM_ SG_ 2549088295 Nightvision_KD_Fehler "Bei gesetztem Bit ist mindestens ein Kundendienstfehler eingetragen";
CM_ SG_ 2549088295 Nightvision_KompSchutz "Funktionseinschränkung aufgrund Komponentenschutz aktiv";
CM_ SG_ 2549088295 Nightvision_Lokalaktiv "Zeigt an ob das SG nach Klemme15 AUS und nach entsprechender MAX Aktivzeit noch aktiv war";
CM_ SG_ 2549088295 Nightvision_Nachlauftyp "Abgebildet wird die von der Hardware vorgegebene Möglichkeit, die Kommunikation nach Klemme 15 = AUS aufrecht zu erhalten. Es wird ein Init-Wert gesendet.
0 = Kommunikation nur bei KL15=EIN (kein Nachlauf, nicht weckfähig)
1 = Kommunikation nach KL15=AU";
CM_ SG_ 2549088295 Nightvision_SNI "Das Signal beinhaltet den Source Node Identifier (Knotenadresse, die auch in der Abbildungsvorschrift zur CAN-ID für die NM-High Botschaft verwendet wird).";
CM_ SG_ 2549088295 Nightvision_Subsystemaktiv "Zeigt an ob ein Subsystem des SGs nach Klemme15 AUS und nach entsprechender MAX Aktivzeit noch aktiv war";
CM_ SG_ 2549088295 Nightvision_Transport_Mode "Funktionseinschränkung aufgrund aktivem Transport Mode und/oder Transport Schutz";
CM_ SG_ 2549088295 NM_Nightvision_Wakeup "enthält die Weckursache; stehen mehrere Weckursachen parallel an, dann muss der kleinste Wert übertragen werden";

CM_ SG_ 2549088267 KN_RDK_BusKnockOutTimer "Ausgabe des BusKnockOut-Timer";
CM_ SG_ 2549088267 NM_RDK_Lokalaktiv "Zeigt an ob das SG nach Klemme15 AUS und nach entsprechender MAX Aktivzeit noch aktiv war.";
CM_ SG_ 2549088267 NM_RDK_Subsystemaktiv "Zeigt an ob ein Subsystem des SGs nach Klemme15 AUS und nach entsprechender MAX Aktivzeit noch aktiv war";
CM_ SG_ 2549088267 NM_RDK_Wakeup "enthält die Weckursache; stehen mehrere Weckursachen parallel an, dann muss der kleinste Wert übertragen werden";
CM_ SG_ 2549088267 RDK_Abschaltstufe "Funktionseinschränkung aufgrund aktiver Abschaltstufe";
CM_ SG_ 2549088267 RDK_KD_Fehler "Bei gesetztem Bit ist mindestens ein Kundendienstfehler eingetragen";
CM_ SG_ 2549088267 RDK_KompSchutz "Funktionseinschränkung aufgrund Komponentenschutz aktiv";
CM_ SG_ 2549088267 RDK_Nachlauftyp "Abgebildet wird die von der Hardware vorgegebene Möglichkeit, die Kommunikation nach Klemme 15 = AUS aufrecht zu erhalten. Es wird ein Init-Wert gesendet.";
CM_ SG_ 2549088267 RDK_SNI "Das Signal beinhaltet den Source Node Identifier (Knotenadresse, die auch in der Abbildungsvorschrift zur CAN-ID für die NM-High Botschaft verwendet wird).";
CM_ SG_ 2549088267 RDK_Transport_Mode "Funktionseinschränkung aufgrund aktivem Transport Mode und/oder Transport Schutz";

CM_ SG_ 2549088361 KN_Rearview_BusKnockOutTimer "Ausgabe des BusKnockOut-Timer";
CM_ SG_ 2549088361 NM_Rearview_Wakeup "enthält die Weckursache; stehen mehrere Weckursachen parallel an, dann muss der kleinste Wert übertragen werden";
CM_ SG_ 2549088361 Rearview_Abschaltstufe "Funktionseinschränkung aufgrund aktiver Abschaltstufe";
CM_ SG_ 2549088361 Rearview_KompSchutz "Funktionseinschränkung aufgrund Komponentenschutz aktiv";
CM_ SG_ 2549088361 Rearview_Lokalaktiv "Zeigt an ob das SG nach Klemme15 AUS und nach entsprechender MAX Aktivzeit noch aktiv war";
CM_ SG_ 2549088361 Rearview_Nachlauftyp "Abgebildet wird die von der Hardware vorgegebene Möglichkeit, die Kommunikation nach Klemme 15 = AUS aufrecht zu erhalten. Es wird ein Init-Wert gesendet.";
CM_ SG_ 2549088361 Rearview_SNI "Das Signal beinhaltet den Source Node Identifier (Knotenadresse, die auch in der Abbildungsvorschrift zur CAN-ID für die NM-High Botschaft verwendet wird).";
CM_ SG_ 2549088361 Rearview_Subsystemaktiv "Zeigt an ob ein Subsystem des SGs nach Klemme15 AUS und nach entsprechender MAX Aktivzeit noch aktiv war";
CM_ SG_ 2549088361 Rearview_Transport_Mode "Funktionseinschränkung aufgrund aktivem Transport Mode und/oder Transport Schutz";
CM_ SG_ 2549088361 RV_KD_Fehler "Status Kundendienstfehlerspeichereinträge";

CM_ SG_ 2549088284 NM_SAK_Wakeup "enthält die Weckursache; stehen mehrere Weckursachen parallel an, dann muss der kleinste Wert übertragen werden";
CM_ SG_ 2549088284 SAK_Abschaltstufe "Funktionseinschränkung aufgrund aktiver Abschaltstufe";
CM_ SG_ 2549088284 SAK_KD_Fehler "Bei gesetztem Bit ist mindestens ein Kundendienstfehler eingetragen";
CM_ SG_ 2549088284 SAK_KompSchutz "Funktionseinschränkung aufgrund Komponentenschutz aktiv";
CM_ SG_ 2549088284 SAK_Lokalaktiv "Zeigt an ob das SG nach Klemme15 AUS und nach entsprechender MAX Aktivzeit noch aktiv war";
CM_ SG_ 2549088284 SAK_Nachlauftyp "Abgebildet wird die von der Hardware vorgegebene Möglichkeit, die Kommunikation nach Klemme 15 = AUS aufrecht zu erhalten. Es wird ein Init-Wert gesendet.
0 = Kommunikation nur bei KL15=EIN (kein Nachlauf, nicht weckfähig)
1 = Kommunikation nach KL15=AU";
CM_ SG_ 2549088284 SAK_SNI "Das Signal beinhaltet den Source Node Identifier (Knotenadresse, die auch in der Abbildungsvorschrift zur CAN-ID für die NM-High Botschaft verwendet wird).";
CM_ SG_ 2549088284 SAK_Subsystemaktiv "Zeigt an ob ein Subsystem des SGs nach Klemme15 AUS und nach entsprechender MAX Aktivzeit noch aktiv war";
CM_ SG_ 2549088284 SAK_Transport_Mode "Funktionseinschränkung aufgrund aktivem Transport Mode und/oder Transport Schutz";

CM_ SG_ 2549088298 KN_SCR_BusKnockOut "Ausgabe des BusKnockout-Status";
CM_ SG_ 2549088298 KN_SCR_BusKnockOutTimer "Ausgabe des BusKnockOut-Timer";
CM_ SG_ 2549088298 KN_SCR_ECUKnockOut "Ausgabe des ECUKnockout-Status";
CM_ SG_ 2549088298 KN_SCR_ECUKnockOutTimer "Ausgabe des ECUKnockOut-Timer";
CM_ SG_ 2549088298 NM_SCR_Wakeup "enthält die Weckursache; stehen mehrere Weckursachen parallel an, dann muss der kleinste Wert übertragen werden";
CM_ SG_ 2549088298 NMH_SCR_Lokalaktiv "Zeigt an ob Steuergerät lokal aktiv war";
CM_ SG_ 2549088298 NMH_SCR_Subsystemaktiv "Zeigt an ob ein Subsystem des SGs nach Klemme15 AUS und nach entsprechender MAX Aktivzeit noch aktiv war";
CM_ SG_ 2549088298 SCR_Abschaltstufe "Funktionseinschränkung aufgrund aktiver Abschaltstufe";
CM_ SG_ 2549088298 SCR_KD_Fehler "Bei gesetztem Bit ist mindestens ein Kundendienstfehler eingetragen";
CM_ SG_ 2549088298 SCR_KompSchutz "Funktionseinschränkung aufgrund Komponentenschutz aktiv";
CM_ SG_ 2549088298 SCR_Nachlauftyp "Abgebildet wird die von der Hardware vorgegebene Möglichkeit, die Kommunikation nach Klemme 15 = AUS aufrecht zu erhalten. Es wird ein Init-Wert gesendet.";
CM_ SG_ 2549088298 SCR_SNI "Das Signal beinhaltet den Source Node Identifier (Knotenadresse, die auch in der Abbildungsvorschrift zur CAN-ID für die NM-High Botschaft verwendet wird).";
CM_ SG_ 2549088298 SCR_Transport_Mode "Funktionseinschränkung aufgrund aktivem Transport Mode und/oder Transport Schutz";

CM_ SG_ 2549088362 KN_STH_BusKnockOutTimer "Ausgabe des BusKnockOut-Timer";
CM_ SG_ 2549088362 NM_STH_Wakeup "enthält die Weckursache; stehen mehrere Weckursachen parallel an, dann muss der kleinste Wert übertragen werden";
CM_ SG_ 2549088362 NMH_STH_Lokalaktiv "Zeigt an ob das SG nach Klemme15 AUS und nach entsprechender MAX Aktivzeit noch aktiv war";
CM_ SG_ 2549088362 NMH_STH_Subsystemaktiv "Zeigt an ob ein Subsystem des SGs nach Klemme15 AUS und nach entsprechender MAX Aktivzeit noch aktiv war";
CM_ SG_ 2549088362 STH_Abschaltstufe "Funktionseinschränkung aufgrund aktiver Abschaltstufe";
CM_ SG_ 2549088362 STH_KD_Fehler "Bei gesetztem Bit ist mindestens ein Kundendienstfehler eingetragen";
CM_ SG_ 2549088362 STH_KompSchutz "Funktionseinschränkung aufgrund Komponentenschutz aktiv";
CM_ SG_ 2549088362 STH_Nachlauftyp "Abgebildet wird die von der Hardware vorgegebene Möglichkeit, die Kommunikation nach Klemme 15 = AUS aufrecht zu erhalten. Es wird ein Init-Wert gesendet.";
CM_ SG_ 2549088362 STH_SNI "Das Signal beinhaltet den Source Node Identifier (Knotenadresse, die auch in der Abbildungsvorschrift zur CAN-ID für die NM-High Botschaft verwendet wird).";
CM_ SG_ 2549088362 STH_Transport_Mode "Funktionseinschränkung aufgrund aktivem Transport Mode und/oder Transport Schutz";

CM_ SG_ 2549088334 KN_SWA_BusKnockOutTimer "Ausgabe des BusKnockOut-Timer in der Knotenbotschaft";
CM_ SG_ 2549088334 NM_SWA_Wakeup "enthält die Weckursache; stehen mehrere Weckursachen parallel an, dann muss der kleinste Wert übertragen werden";
CM_ SG_ 2549088334 SWA_Abschaltstufe "Funktionseinschränkung aufgrund aktiver Abschaltstufe";
CM_ SG_ 2549088334 SWA_KD_Fehler "Bei gesetztem Bit ist mindestens ein Kundendienstfehler eingetragen";
CM_ SG_ 2549088334 SWA_KompSchutz "Funktionseinschränkung aufgrund Komponentenschutz aktiv";
CM_ SG_ 2549088334 SWA_Lokalaktiv "Zeigt an ob das SG nach Klemme15 AUS und nach entsprechender MAX Aktivzeit noch aktiv war";
CM_ SG_ 2549088334 SWA_Nachlauftyp "Abgebildet wird die von der Hardware vorgegebene Möglichkeit, die Kommunikation nach Klemme 15 = AUS aufrecht zu erhalten. Es wird ein Init-Wert gesendet.
0 = Kommunikation nur bei KL15=EIN (kein Nachlauf, nicht weckfähig)
1 = Kommunikation nach KL15=AU";
CM_ SG_ 2549088334 SWA_SNI "Das Signal beinhaltet den Source Node Identifier (Knotenadresse, die auch in der Abbildungsvorschrift zur CAN-ID für die NM-High Botschaft verwendet wird).";
CM_ SG_ 2549088334 SWA_Subsystemaktiv "Zeigt an ob ein Subsystem des SGs nach Klemme15 AUS und nach entsprechender MAX Aktivzeit noch aktiv war";
CM_ SG_ 2549088334 SWA_Transport_Mode "Funktionseinschränkung aufgrund aktivem Transport Mode und/oder Transport Schutz";

CM_ SG_ 2549088394 KN_SWA_Slave_BusKnockOutTimer "Ausgabe des BusKnockOut-Timer in der Knotenbotschaft";
CM_ SG_ 2549088394 NM_SWA_2_Wakeup "enthält die Weckursache; stehen mehrere Weckursachen parallel an, dann muss der kleinste Wert übertragen werden";
CM_ SG_ 2549088394 SWA_2_Abschaltstufe "Funktionseinschränkung aufgrund aktiver Abschaltstufe";
CM_ SG_ 2549088394 SWA_2_KD_Fehler "Bei gesetztem Bit ist mindestens ein Kundendienstfehler eingetragen";
CM_ SG_ 2549088394 SWA_2_KompSchutz "Funktionseinschränkung aufgrund Komponentenschutz aktiv";
CM_ SG_ 2549088394 SWA_2_Lokalaktiv "Zeigt an ob das SG nach Klemme15 AUS und nach entsprechender MAX Aktivzeit noch aktiv war";
CM_ SG_ 2549088394 SWA_2_Nachlauftyp "Abgebildet wird die von der Hardware vorgegebene Möglichkeit, die Kommunikation nach Klemme 15 = AUS aufrecht zu erhalten. Es wird ein Init-Wert gesendet.
0 = Kommunikation nur bei KL15=EIN (kein Nachlauf, nicht weckfähig)
1 = Kommunikation nach KL15=AU";
CM_ SG_ 2549088394 SWA_2_SNI "Das Signal beinhaltet den Source Node Identifier (Knotenadresse, die auch in der Abbildungsvorschrift zur CAN-ID für die NM-High Botschaft verwendet wird).";
CM_ SG_ 2549088394 SWA_2_Subsystemaktiv "Zeigt an ob ein Subsystem des SGs nach Klemme15 AUS und nach entsprechender MAX Aktivzeit noch aktiv war";
CM_ SG_ 2549088394 SWA_2_Transport_Mode "Funktionseinschränkung aufgrund aktivem Transport Mode und/oder Transport Schutz";

CM_ SG_ 779 KBI_ABS_Lampe "ABS-Sicherheits-Lampe wurde eingeschaltet.";
CM_ SG_ 779 KBI_Airbag_Lampe "Airbag Sicherheits-Lampe wurde eingeschaltet ";
CM_ SG_ 779 KBI_angez_Geschw "Im Tacho angezeigte Geschwindigkeit inklusive der Voreilung

";
CM_ SG_ 779 KBI_Anzeigefehler_NV "Über dieses Signal teilt das Kombiinstrument dem Nightvision-Steuergerät mit, dass ein Fehler vom Kombiinstrument diagnostiziert wurde, der zur Abschaltung der Nightvision-Funktion führen muss.";
CM_ SG_ 779 KBI_Anzeigefehler_SWA "Signal bezieht sich nur auf die SWA-Lampe, Vorhalt für Kombis mit SWA-Lampe. ";
CM_ SG_ 779 KBI_Anzeigestatus_ACC "Status der ACC-Anzeige im nicht permanenten Displaybereich";
CM_ SG_ 779 KBI_Anzeigestatus_GRA "Anzeigestatus der GRA High Wunschgeschwindigkeitsanzeige im Kombiinstrument.
Bei VW bedeutet 'nicht vorhanden' GRA-low fähig (LED immer verbaut).
0 = nicht vorhanden
1 = Wunschgeschwindigkeits-Anzeigemöglichkeit vorhanden
2 = reserviert
3 = Fehler (B";
CM_ SG_ 779 KBI_Anzeigestatus_LIM "Anzeigestatus der Speedlimiter Wunschgeschwindigkeitsanzeige im Kombiinstrument (permanenter Anzeigebereich)
0 = nicht vorhanden
1 = Wunschgeschwindigkeits-Anzeigemöglichkeit vorhanden
2 = reserviert
3 = Fehler (Botschaftsüberwachung, Timeout, Akustik";
CM_ SG_ 779 KBI_ARA_in_Anzeige "Anzeige von ARA im Kombi aktiv";
CM_ SG_ 779 KBI_Bestaetigung_ESP_Off "ESP Off Bestätigung vom Kombi ans ESC";
CM_ SG_ 779 KBI_BKL_Lampe "Sicherheits-Lampe Bremskontrolle wurde eingeschaltet;
";
CM_ SG_ 779 KBI_Einheit_Tacho "Information, ob es sich um Meilen- oder Kmh-Kombi handelt, Einheit des Tachos entspricht dem Zifferblatt, Grösse ist nicht veränderlich";
CM_ SG_ 779 KBI_ESP_Lampe "ESP-Sicherheits-Lampe wurde eingeschaltet ";
CM_ SG_ 779 KBI_Fehler_Anzeige_ACC "Rückmeldung an ACC, dass mindestens eine der ACC-relevanten Anzeigen -rote Fahrerübernahme, Mitteldisplay, Gong - fehlerhaft sind.";
CM_ SG_ 779 KBI_GRA_Hauptschalter "Hauptschalter der Fahrerassistenzsysteme basierend auf dem FAS-Menu im Kombi.";
CM_ SG_ 779 KBI_Handbremse "Handbremsen-Information vom Kombi.
Das Signal bezieht sich ausschließlich auf den Zustand der konventionellen Handbremse.";
CM_ SG_ 779 KBI_im_Stellgliedtest "Kombi im Stellgliedtest, Signal muss eingelesen werden, um Fehlfunktion aufgrund der Bewegung der Stellglieder (Drehzahlmesser, Tacho) des Kombis zu verhindern";
CM_ SG_ 779 KBI_Konsistenz_ACC "Rückmeldung an ACC, dass die Botschaften zur Ansteuerung von Anzeigen nicht bzw. nicht konsistent empfangen wurden (Timeout-, BZ-, CHK- und DLC-Fehler)                                                                                                        ";
CM_ SG_ 779 KBI_Lenkung_Lampe "Sicherheits-Lampe der Lenkung (Lenkhilfe EPS, Audi-Dynamic-Steering ...) wurde eingeschaltet.

0x0 = Lenkungs-Lampe aus
0x1 = Lenkungs-Lampe ein";
CM_ SG_ 779 KBI_MFA_v_Einheit_01 "Einheit der Geschwindigkeit, die vom Fahrer im Car-Menü gewählt wurde. Veränderliche Grösse, im Gegensatz zur Einheit des Tachokranzes.";
CM_ SG_ 779 KBI_NV_in_Anzeige "Das Bit gibt dem NV die Information, ob NV-Bild im Kombi in der Anzeige ist. (Information ist notwendig um Kontrasverstellungen nur dann zuzulassen, wenn der Fahrer das Feedback über das  Kombidisplay bekommt.)";
CM_ SG_ 779 KBI_PLA_in_Anzeige "Das Signal wird als aktive Rückmeldung genutzt, ob die Info des PLA im Kombi angezeigt wird. Wenn nach Anforderung des Displays das Signal zweimal auf 0 ist, wird der Parkvorgang abgebrochen.
Ein Kombi, dass PLA Anzeige nicht unterstützt, schickt dauerha";
CM_ SG_ 779 KBI_SILA_gueltig "Rückmeldeinformation (Bit 1-6) ist gültig";
CM_ SG_ 779 KBI_Systemstatus "Signalisiert erkannte FuSi-relevante Fehler im Kombi
(keinen Ausfall der Akustik oder des Displays)";
CM_ SG_ 779 KBI_Tankwarnung "Fahrer wird gewarnt, dass er den Reservebereich erreicht hat. Fzg.spezifische Warnschwelle";
CM_ SG_ 779 KBI_Tankwarnung_ungueltig "Validiert den Inhalt des Signales KBI_Tankwarnung";
CM_ SG_ 779 KBI_Taster_Fahrwerk "Betätigung Taster 'Fahrwerk' im Kombi";
CM_ SG_ 779 KBI_Taster_Lift "Betätigung Taster 'Lift' im Kombi J1 zur Verarbeitung im Porsche EFP Steuergerät";
CM_ SG_ 779 KBI_V_Digital "Ausgabe der im Kombi angezeigten digitalen Geschwindigkeit.

Einheit ist im KBI_MFA_v_Einheit_01 definiert";
CM_ SG_ 779 KBI_Vorglueh_System_Lampe "Rückmeldung der Vorglühlampe bzw. Motor Systemlampe (MO_Systemlampe) an den Motor (bei Diesel und Otto!). Hardwaremässig gleiche LED im Kombi (EPC- oder Glühwendel), Unterscheidung nur über Ziffernblatt.";

CM_ SG_ 1719 KBI_aktive_Laengsfunktion "Auswahl, der vom Fahrer gewünschten Laengsregelfunktion";
CM_ SG_ 1719 KBI_FoD_PopUP_Quittiert "Angezeigte FoD-Warnung im Kombi wurde vom Fahrer quittiert; 
Signal wird für die Dauer von 2 Sekunden gesendet";
CM_ SG_ 1719 KBI_FStatus_Tank "Signal wird gesetzt:

a) Während der Fehlerentprellzeit (20 s Entprellung)

b) Bei erkanntem Fehler wird der Tankinhalt während der laufenden KL15-Phase über den 
    Verbrauch zurückgerechnet. In dieser Zeit ist das Bit ebenfalls gesetzt. Nach einem";
CM_ SG_ 1719 KBI_GRA_im_ACC "Gibt den vom Fahrer ausgewählten Modus (ACC oder GRA_im_ACC) an.";
CM_ SG_ 1719 KBI_Inhalt_Tank "Restmenge 2 bzw. 2,5l nicht auflösbar

";
CM_ SG_ 1719 KBI_Kilometerstand "Fehler wird ausgegeben, falls Kilometerstand nicht restaurierbar
";
CM_ SG_ 1719 KBI_LVDS_Lock "Dient zur Synchronisation der Anzeige zwischen Kombi und ZR";
CM_ SG_ 1719 KBI_Oelwechsel_durchgefuehrt "Nach einen Ölwechsel (Service) ist die Ethanol Warmfahrwarnung zu unterdrücken.";
CM_ SG_ 1719 KBI_QBit_Aussen_Temp_gef "0x0 = gültiger Wert
0x1 = Ersatz-, Init- oder Fehlerwert";
CM_ SG_ 1719 KBI_RDK_Kalibrier_Anf "Bei gesetztem Bit soll die RDK die aktuellen Istdrücke zu Solldrücken übernehmen (nur bei Nichtverbau einer Headunit erforderlich).";
CM_ SG_ 1719 KBI_Reserve_Warnung_Sek "Signalisiert die Reservewarnung für die Energiespeicher CNG, LPG, HV-Batterie.
Fahrer wird gewarnt, dass er den Reservebereich erreicht hat. Fzg.spezifische Warnschwelle.";
CM_ SG_ 1719 KBI_Standzeit_02 "Zähler welcher die Standzeit des Motors wiedergibt.
Das Signal beschreibt den Anteil der Motor-Standzeit zwischen Zündung aus und nächstem Motorstart.";
CM_ SG_ 1719 KBI_TA_gewaehlt_Fahrer "Rueckmeldung, dass der TA vom Fahrer gewaehlt wurde";

CM_ SG_ 2527679639 KBI_Jokerkey "Betaetigung KBI Jokertaste";
CM_ SG_ 2527679639 KBI_RS_Druck_uebernehmen "Druck für Rundstreckenmodus übernehmen";
CM_ SG_ 2527679639 KBI_RS_Druckauswahl_Aktiv "Menue Druckauswahl aktiv";
CM_ SG_ 2527679639 KBI_RS_Mode_fortsetzen "Kombi fordert Fortsetzung des Rundstreckenmodus";
CM_ SG_ 2527679639 KBI_Rundstreckenmodus "Rundstreckenmodus Anforderung";
CM_ SG_ 2527679639 KBI_Weg_Zaehler "Inkrementaler Zähler des Kombis

PAG-Plattform:
Sendeart: Cyclic
Zykluszeit: 100ms

MLBevo_Konzern:
Sendeart: OnChange
Zykluszeit: 1000ms
Inhibitzeit: 100ms
";
CM_ SG_ 2527679639 KBI_Weg_Zaehler_F "Fehlerbit für den Inkrementalzähler Weg

PAG-Plattform:
Sendeart: Cyclic
Zykluszeit: 100ms

MLBevo_Konzern:
Sendeart: OnChange
Zykluszeit: 1000ms
Inhibitzeit: 100ms";

CM_ SG_ 1614 KBI_HUD_Data_01 "Kommunikation Kombi zu HUD. Prio.texte zur gleichzeitigen Anzeige im Kombi und HUD.";
CM_ SG_ 1614 KBI_HUD_Data_02 "Kommunikation Kombi zu HUD. Prio.texte zur gleichzeitigen Anzeige im Kombi und HUD.";
CM_ SG_ 1614 KBI_HUD_Data_03 "Kommunikation Kombi zu HUD. Prio.texte zur gleichzeitigen Anzeige im Kombi und HUD.";
CM_ SG_ 1614 KBI_HUD_Data_04 "Kommunikation Kombi zu HUD. Prio.texte zur gleichzeitigen Anzeige im Kombi und HUD.";
CM_ SG_ 1614 KBI_HUD_Data_05 "Kommunikation Kombi zu HUD. Prio.texte zur gleichzeitigen Anzeige im Kombi und HUD.";
CM_ SG_ 1614 KBI_HUD_Data_06 "Kommunikation Kombi zu HUD. Prio.texte zur gleichzeitigen Anzeige im Kombi und HUD.";
CM_ SG_ 1614 KBI_HUD_Data_07 "Kommunikation Kombi zu HUD. Prio.texte zur gleichzeitigen Anzeige im Kombi und HUD.";
CM_ SG_ 1614 KBI_HUD_Data_08 "Kommunikation Kombi zu HUD. Prio.texte zur gleichzeitigen Anzeige im Kombi und HUD.";

CM_ SG_ 2549874983 KS_Nightvision_Req_Data "Komponentenschutz (Funktion 01h). Request mit NA des Slaves.";

CM_ SG_ 2550006055 KS_Nightvision_Resp_Data "Komponentenschutz (Funktion 01h). Response mit eigener NA.";

CM_ SG_ 2549875082 KS_SWA_2_Req_Data "Komponentenschutz (Funktion 01h). Request mit NA des Slaves.";

CM_ SG_ 2550006154 KS_SWA_2_Resp_Data "Komponentenschutz (Funktion 01h). Response mit eigener NA.";

CM_ SG_ 2549875022 KS_SWA_Req_Data "Komponentenschutz (Funktion 01h). Request mit NA des Slaves.";

CM_ SG_ 2550006094 KS_SWA_Resp_Data "Komponentenschutz (Funktion 01h). Response mit eigener NA.";

CM_ SG_ 160 EPS_04_BZ "Botschaftszähler";
CM_ SG_ 160 EPS_04_CRC "Für MLB:
'Berechnung siehe Lastenheft 'Kommunikationsabsicherung für FlexRay und CAN''

Ab MQB und MLBevo:
'Berechnung siehe Lastenheft 'End-to-End Kommunikationsabsicherung''

Endwerte siehe Begleitdokument 'S-PDU Kennungsfolgen'";
CM_ SG_ 160 EPS_AWA_Status "beschreibt den Status der AWA-Funktion im EPS-Steuergerät. (Ausweich-Assistent)";
CM_ SG_ 160 EPS_FAS_Regelgroesse "Aktuelle Regelauslastung der STA/STP-Funktionsschnittstelle";
CM_ SG_ 160 EPS_FAS_VZ_Regelgroesse "Richtung der FAS Regelgröße";
CM_ SG_ 160 EPS_Lenkmoment_AbsReduz "Gibt den Absolutwert des aktuelle Handlenkmoment mit einer Auflösung von 0 ,62 Nm aus";
CM_ SG_ 160 EPS_Motormoment "Motornahes Motor-Sollmoment";
CM_ SG_ 160 EPS_QBit_Zahnstangen_Pos "beschreibt die Qualität/Vertrauenswürdigkeit der Zahnstangenposition";
CM_ SG_ 160 EPS_STA_Status "beschreibt den Status der STA-Funktion im EPS-Steuergerät. (Stauassistent)";
CM_ SG_ 160 EPS_Versorgungsspannung "Gibt die am Steuergerät anliegende Spannung aus.
";
CM_ SG_ 160 EPS_Versorgungsstatus "Erkennung Störung im Versorgungspfad
";
CM_ SG_ 160 EPS_VZ_Zahnstangenposition "Vorzeichen der Position/Verschiebung der Zahnstange bzgl. Lenkungsmitte
Vorzeichen:
(Fahreransicht: positiv = links von der Nullstellung des Lenkrades)
Nullstellung = +0mm";
CM_ SG_ 160 EPS_Zahnstangen_Pos "Position/Verschiebung der Zahnstange bzgl. Lenkungsmitte";

CM_ SG_ 981 BCM1_Abblendlicht_Anf "Anforderung Abblendlicht
";
CM_ SG_ 981 BCM1_Adaptive_Lichtvert_Anf "Funktion 'Adaptive Lichtverteilung' im AFS-SG  Ein- und Ausschalten";
CM_ SG_ 981 BCM1_Allwetterlicht_Anf "Anforderung eines Allwetterlichts (über AFS-SG realisiert): Licht für schlechte Sichtverhältnisse";
CM_ SG_ 981 BCM1_Animationssperrung "Sperrung der Scheinwerfer- und Heckleuchten-Animationen. Grund für Sperrung sind allgemeine Rahmenbedingungen, wie beispielseweise eine LDS-Stellung ungleich 'Auto'";
CM_ SG_ 981 BCM1_Autobahnlicht_Anf "Anforderung Autobahnlicht
";
CM_ SG_ 981 BCM1_CH_aktiv "Coming Home (zusätzlich zum Signal 'BCM1_CH_LH_aktiv' in der Botschaft BCM1_01)";
CM_ SG_ 981 BCM1_CH_LH_aktiv "Status Comming / Leaving Home
";
CM_ SG_ 981 BCM1_Fernlicht_Anf "Anforderung Fernlicht
";
CM_ SG_ 981 BCM1_FOD_Sperrung_Animationen_HL "Sperrung Heckleuchten-Animationen durch FoD.";
CM_ SG_ 981 BCM1_FoD_Sperrung_WiBli "Sperrung Wischeffekt des dynamischen Blinkers (Front & Heck) durch FoD";
CM_ SG_ 981 BCM1_Gleitende_Leuchtw_Anf "Funktion 'Gleitende Leuchtweite' im AFS-SG  freischalten";
CM_ SG_ 981 BCM1_GLW_Fernlicht_Anf "Harte Fernlichtanforderung von BCM1 an die Funktion 'gleitende Leuchtweite' im AFS-SG";
CM_ SG_ 981 BCM1_Kurvenlicht_links_Anf "Ansteuerung linkes Kurvenlicht/Abbiegelicht duch BCM1";
CM_ SG_ 981 BCM1_Kurvenlicht_rechts_Anf "Ansteuerung rechtes Kurvenlicht/Abbiegelicht duch BCM1";
CM_ SG_ 981 BCM1_LH_aktiv "Leaving Home (zusätzlich zum Signal 'BCM1_CH_LH_aktiv' in der Botschaft BCM1_01)";
CM_ SG_ 981 BCM1_Nebellicht_Anf "Anforderung Nebellicht
";
CM_ SG_ 981 BCM1_Nebelschluss_Ahg_Anf "Anforderung: Nebelschlusslicht Anhänger (Sollzustand)
";
CM_ SG_ 981 BCM1_Nebelschluss_Fzg_Anf "Anforderung: Nebelschlusslicht Fahrzeug (Sollzustand)";
CM_ SG_ 981 BCM1_Parklicht_li_Anf "Anforderung: Parklicht links (Sollzustand)
";
CM_ SG_ 981 BCM1_Parklicht_re_Anf "Anforderung: Parklicht rechts (Sollzustand)
";
CM_ SG_ 981 BCM1_Regenlicht_Anf "Anforderung: Regenlicht (Sollzustand)
";
CM_ SG_ 981 BCM1_Schlusslicht_Anf "Anforderung: Schlusslicht Fahrzeug (Sollzustand)
";
CM_ SG_ 981 BCM1_Schlusslicht_Signatur "Anforderung der Umschaltung der Schlusslicht-Signatur";
CM_ SG_ 981 BCM1_Signaturlicht_Anf "Signal zur Anforderung des Signaturlichts";
CM_ SG_ 981 BCM1_Standlicht_Anf "Anforderung: Schlusslicht (Sollzustand)";
CM_ SG_ 981 BCM1_Tagfahrlicht_Anf "Anforderung: Tagfahrlicht (Sollzustand)";
CM_ SG_ 981 BCM1_Touristen_Licht_Anf "Anforderung: Touristenlicht (Sollzustand)";
CM_ SG_ 981 BCM1_Umfeldleuchten_Anf "Anforderung für Umfeldleuchten";
CM_ SG_ 981 BCM_Rueckfahrlicht_Anf "Anforderung Rückfahrlicht (Sollzustand). 
Das Signal wird entprellt (typisch 400ms) und bei KL15EIN gesendet. Das Signal ist unabhängig von der Position des Heckdeckels (kein Überhitzungsschutz).";
CM_ SG_ 981 Licht_Anf_01_BZ "4bit Botschaftszaehler, wird mit jeder Sendebotschaft inkrementiert";
CM_ SG_ 981 Licht_Anf_01_CRC "Für MLB:
'Berechnung siehe Lastenheft 'Kommunikationsabsicherung für FlexRay und CAN''

Ab MQB und MLBevo:
'Berechnung siehe Lastenheft 'End-to-End Kommunikationsabsicherung''

Endwerte siehe Begleitdokument 'S-PDU Kennungsfolgen'";

CM_ SG_ 1624 BCM1_Licht_Dunkelheit_aktiv "Licht aktiv aufgrund von Dunkelheit (nicht bei Autobahn-, Tagfahr- oder Regenlicht)";
CM_ SG_ 1624 BCM1_Linksverkehr "Information über Aufbauzustand des Fzg:
0 = Scheinwerfer für Rechtsverkehr
1 = Scheinwerfer für Linksverkehr";
CM_ SG_ 1624 Licht_Vorne_01_CRC "Für MLB:
'Berechnung siehe Lastenheft 'Kommunikationsabsicherung für FlexRay und CAN''

Ab MQB und MLBevo:
'Berechnung siehe Lastenheft 'End-to-End Kommunikationsabsicherung''

Endwerte siehe Begleitdokument 'S-PDU Kennungsfolgen'";
CM_ SG_ 1624 LV_Abbiegelicht_li_def "Fehlerstatus Abbiegelicht vorne links
";
CM_ SG_ 1624 LV_Abbiegelicht_re_def "Fehlerstatus Abbiegelicht vorne rechts
";
CM_ SG_ 1624 LV_Abblend_Fernlicht_li_def "Fehlerstatus Abblendlicht und Fernlicht links ";
CM_ SG_ 1624 LV_Abblend_Fernlicht_re_def "Fehlerstatus Abblendlicht und Fernlicht rechts";
CM_ SG_ 1624 LV_Abblendlicht_Anzeige "Abblendlicht aktiv";
CM_ SG_ 1624 LV_Abblendlicht_li_def "Fehlerstatus Abblendlicht vorne links 
";
CM_ SG_ 1624 LV_Abblendlicht_re_def "Fehlerstatus Abblendlicht vorne rechts
";
CM_ SG_ 1624 LV_Abblendlicht_TFL_li_def "Fehlerstatus Abblendlicht und Tagfahrlicht links
";
CM_ SG_ 1624 LV_Abblendlicht_TFL_re_def "Fehlerstatus Abblendlicht und Tagfahrlicht rechts ";
CM_ SG_ 1624 LV_AFL_aktiv_Anzeige "Anzeige AFL-Funktion";
CM_ SG_ 1624 LV_AFL_defekt "Fehlerstatus AFL
";
CM_ SG_ 1624 LV_Aussenlicht_def "Aussenlicht kann nicht mehr korrekt angesteuert werden (EEPROM Codierung kann nicht mehr ausgelesen werden)
";
CM_ SG_ 1624 LV_Blinker_li_def "Fehlerstatus Blinker vorne links
";
CM_ SG_ 1624 LV_Blinker_re_def "Fehlerstatus Blinker vorne rechts
";
CM_ SG_ 1624 LV_Blinker_VL_aktiv "Blinker vorne links
";
CM_ SG_ 1624 LV_Blinker_VR_aktiv "Blinker vorne links
";
CM_ SG_ 1624 LV_Blk_li_Seite_def "Fehlerstatus Seitenblinker links
";
CM_ SG_ 1624 LV_Blk_re_Seite_def "Fehlerstatus Blinker Seite rechts
";
CM_ SG_ 1624 LV_Fernlicht_Anzeige "Fernlicht_aktiv";
CM_ SG_ 1624 LV_Fernlicht_li_def "Fehlerstatus Fernlicht vorne links
";
CM_ SG_ 1624 LV_Fernlicht_re_def "Fehlerstatus Fernlicht vorne rechts
";
CM_ SG_ 1624 LV_FLA_aktiv_Anzeige "Ansteuerung FLA-Lampe im Kombi (BCM1 Bedienmaster)";
CM_ SG_ 1624 LV_FLA_defekt "Fehlerstatus FLA (Anzeige des entsprechenden Fehlertext im Kombi)";
CM_ SG_ 1624 LV_FLA_Sensor_blockiert "Status FLA-Sensor (Anzeige des entsprechenden Fehlertext im Kombi)";
CM_ SG_ 1624 LV_LED_Scheinwerfer_li_def "Fehlerstatus LED-Scheinwerfer links
";
CM_ SG_ 1624 LV_LED_Scheinwerfer_re_def "Fehlerstatus LED-Scheinwerfer rechts";
CM_ SG_ 1624 LV_MXB_Status_Anzeige "Aktueller Status des Fernlichts / MxB zur Signalisierung im Kombi.";
CM_ SG_ 1624 LV_Nebellicht_Anzeige "Nebellicht_aktiv
";
CM_ SG_ 1624 LV_Nebellicht_li_def "Fehlerstatus Nebelscheinwerfer vorne links
";
CM_ SG_ 1624 LV_Nebellicht_re_def "Fehlerstatus Nebelscheinwerfer vorne rechts
";
CM_ SG_ 1624 LV_Nebellicht_TFL_li_def "Fehlerstatus Nebellicht und Tagfahrlicht links ";
CM_ SG_ 1624 LV_Nebellicht_TFL_re_def "Fehlerstatus Nebellicht und Tagfahrlicht rechts";
CM_ SG_ 1624 LV_Nebelschlusslicht_Anzeige "Nebelschlusslicht_aktiv
";
CM_ SG_ 1624 LV_Standlicht_Anzeige "Anzeige Standlicht
";
CM_ SG_ 1624 LV_Standlicht_li_def "Fehlerstatus Standlicht vorne links
";
CM_ SG_ 1624 LV_Standlicht_re_def "Fehlerstatus Standlicht vorne rechts
";
CM_ SG_ 1624 LV_Standlicht_TFL_li_def "Fehlerstatus Standlicht und Tagfahrlicht links ";
CM_ SG_ 1624 LV_Standlicht_TFL_re_def "Fehlerstatus Standlicht und Tagfahrlicht rechts ";
CM_ SG_ 1624 LV_Tagfahrlicht_Anzeige "Anzeige Tagfahrlicht
";
CM_ SG_ 1624 LV_Tagfahrlicht_li_def "Fehlerstatus Tagfahrlicht links
";
CM_ SG_ 1624 LV_Tagfahrlicht_re_def "Fehlerstatus Tagfahrlicht rechts";

CM_ SG_ 134 LWI_01_BZ "Botschaft asynchron geroutet. Zählerwert kann springen.";
CM_ SG_ 134 LWI_01_CRC "Für MLB:
'Berechnung siehe Lastenheft 'Kommunikationsabsicherung für FlexRay und CAN''

Ab MQB und MLBevo:
'Berechnung siehe Lastenheft 'End-to-End Kommunikationsabsicherung'

Endwerte siehe Begleitdokument 'S-PDU Kennungsfolgen'";
CM_ SG_ 134 LWI_Lenkradw_Geschw "Wertebereich = +/- 2500 Grad/s
Auflösung = 5 Grad/s

Hinweis: Zusätzlich gestellte Winkel bei Dynamiklenkung beachten !";
CM_ SG_ 134 LWI_Lenkradwinkel "Wertebereich = +/- 800 Grad
Auflösung = 0,1 Grad
ACHTUNG: spezifizierte Interne Auflösung des Sensors beträgt aber nur Schrittweite 0,5 Grad!

Hinweis:
MLB: Zusätzlich gestellte Winkel bei Dynamiklenkung beachten !
MQB: Nicht konstante Lenkübersetzu";
CM_ SG_ 134 LWI_MFL_Abschaltung "Signal zur Anforderung der MFL Abschaltung bei Erkennung einer dynamischen Lenkbewegung.";
CM_ SG_ 134 LWI_QBit_Lenkradwinkel "Das QBit wird auch bei nicht abgeglichenem Lenkradwinkelsensor gesetzt";
CM_ SG_ 134 LWI_QBit_Sub_Daten "Es gilt die Signalspezifikation laut LAH";
CM_ SG_ 134 LWI_Sub_Daten "Verschlüsseltes Datenpaket vom Sub-Rechner des LWS, Verwendung nur durch SCU und ESP_ADS
Verwendung gemäß 'Sicherheitsanforderungen an Empfängersteuergeräte'

Im MLB gilt die Signalspezifikation: LAH 8K0953B
Im MLBevo gilt die Signalspezifikation LAH.";
CM_ SG_ 134 LWI_VZ_Lenkradw_Geschw "Vorzeichen Lenkradwinkelgeschwindigkeit gemäss DIN70000; 
Nullstellung = +0";
CM_ SG_ 134 LWI_VZ_Lenkradwinkel "Vorzeichen Lenkradwinkel gemäss DIN70000; 
Nullstellung = +0";
BA_DEF_REL_ BU_SG_REL_  "GenSigTimeoutTime" INT 0 65535;
BA_DEF_ BO_  "DiagRequest" ENUM "No", "Yes";
BA_DEF_ BO_  "DiagResponse" ENUM "No", "Yes";
BA_DEF_ BO_  "DiagState" ENUM "No", "Yes";
BA_DEF_ BO_  "GenMsgChkConstant" HEX 0 4095;
BA_DEF_ BO_  "GenMsgCycleTime" INT 0 65535;
BA_DEF_ BO_  "GenMsgCycleTimeFast" INT 0 65535;
BA_DEF_ BO_  "GenMsgDelayTime" INT 0 100000;
BA_DEF_ BO_  "GenMsgILSupport" ENUM "No", "Yes";
BA_DEF_ BO_  "GenMsgNrOfRepetition" INT 0 100;
BA_DEF_ BO_  "GenMsgPDUConstants" STRING;
BA_DEF_ BO_  "GenMsgSendType" ENUM "Cyclic", "not_used", "not_used", "not_used", "not_used", "not_used", "not_used", "IfActive", "NoMsgSendType";
BA_DEF_ BO_  "GenMsgStartDelayTime" INT 0 100000;
BA_DEF_ BO_  "NmMessage" ENUM "No", "Yes";
BA_DEF_ BO_  "NmhMessage" ENUM "No", "Yes";
BA_DEF_ BO_  "MsgType" ENUM "Application", "NM ", "NMH", "TP2.0", "ISO-TP ", "BAP", "EID", "KS", "XCP_PRE_CONFIGURED", "XCP_RUNTIME_CONFIGURED";
BA_DEF_ BO_  "VAGTP20_API" HEX 0 255;
BA_DEF_ BO_  "VAGTP20_DynConnection" ENUM "No", "Yes";
BA_DEF_ BO_  "VAGTP20_DynSetup" ENUM "No", "Yes";
BA_DEF_ BO_  "VAGTP20_StatConnection" ENUM "No", "Yes";
BA_DEF_ SG_  "GenSigActiveRepetitions" INT -2147483648 2147483647;
BA_DEF_ SG_  "GenSigInactiveValue" INT -2147483648 2147483647;
BA_DEF_ SG_  "GenSigSendType" ENUM "Cyclic", "OnWrite", "OnWriteWithRepetition", "OnChange", "OnChangeWithRepetition", "IfActive", "IfActiveWithRepetition", "NoSigSendType", "OnChangeAndIfActive", "OnChangeAndIfActiveWithRepetition";
BA_DEF_ SG_  "GenSigStartValue" INT -2147483648 2147483647;
BA_DEF_ SG_  "NWM-WakeupAllowed" ENUM "No", "Yes";
BA_DEF_ SG_  "GenSigFuncType" ENUM "NoFunction", "MsgCounter", "CRC-8", "XOR", "XOR-2", "DatedBit", "SW-Kl15", "CHK", "Constant", "Protocol", "CRC-8-SAE_J1850", "CRC-32", "DataLength", "DataID", "MsgCounter16", "SOK-Signatur", "Cluster";
BA_DEF_ SG_  "GenSigSwitchedByIgnition" ENUM "No", "Yes";
BA_DEF_ SG_  "Fehlerwert" HEX 0 2147483647;
BA_DEF_ SG_  "GenSigMissingSourceValue" HEX 0 2147483647;
BA_DEF_DEF_REL_  "GenSigTimeoutTime" 0;
BA_DEF_DEF_  "DiagRequest" "No";
BA_DEF_DEF_  "DiagResponse" "No";
BA_DEF_DEF_  "DiagState" "No";
BA_DEF_DEF_  "GenMsgChkConstant" 0;
BA_DEF_DEF_  "GenMsgCycleTime" 0;
BA_DEF_DEF_  "GenMsgCycleTimeFast" 0;
BA_DEF_DEF_  "GenMsgDelayTime" 0;
BA_DEF_DEF_  "GenMsgILSupport" "No";
BA_DEF_DEF_  "GenMsgNrOfRepetition" 0;
BA_DEF_DEF_  "GenMsgPDUConstants" "";
BA_DEF_DEF_  "GenMsgSendType" "NoMsgSendType";
BA_DEF_DEF_  "GenMsgStartDelayTime" 0;
BA_DEF_DEF_  "NmMessage" "No";
BA_DEF_DEF_  "NmhMessage" "No";
BA_DEF_DEF_  "MsgType" "Application";
BA_DEF_DEF_  "VAGTP20_API" 0;
BA_DEF_DEF_  "VAGTP20_DynConnection" "No";
BA_DEF_DEF_  "VAGTP20_DynSetup" "No";
BA_DEF_DEF_  "VAGTP20_StatConnection" "No";
BA_DEF_DEF_  "GenSigActiveRepetitions" 0;
BA_DEF_DEF_  "GenSigInactiveValue" 0;
BA_DEF_DEF_  "GenSigSendType" "NoSigSendType";
BA_DEF_DEF_  "GenSigStartValue" 0;
BA_DEF_DEF_  "NWM-WakeupAllowed" "No";
BA_DEF_DEF_  "GenSigFuncType" "NoFunction";
BA_DEF_DEF_  "GenSigSwitchedByIgnition" "Yes";
BA_DEF_DEF_  "Fehlerwert" 0;
BA_DEF_DEF_  "GenSigMissingSourceValue" 0;
BA_ "GenMsgCycleTime" BO_ 1646 2000;
BA_ "GenMsgDelayTime" BO_ 1646 200;
BA_ "GenMsgILSupport" BO_ 1646 1;
BA_ "GenMsgSendType" BO_ 1646 0;
BA_ "GenMsgCycleTime" BO_ 1649 2000;
BA_ "GenMsgDelayTime" BO_ 1649 200;
BA_ "GenMsgILSupport" BO_ 1649 1;
BA_ "GenMsgSendType" BO_ 1649 0;
BA_ "GenMsgCycleTime" BO_ 949 100;
BA_ "GenMsgILSupport" BO_ 949 1;
BA_ "GenMsgSendType" BO_ 949 0;
BA_ "GenMsgCycleTime" BO_ 1640 200;
BA_ "GenMsgCycleTimeFast" BO_ 1640 100;
BA_ "GenMsgDelayTime" BO_ 1640 25;
BA_ "GenMsgILSupport" BO_ 1640 1;
BA_ "GenMsgNrOfRepetition" BO_ 1640 5;
BA_ "GenMsgSendType" BO_ 1640 0;
BA_ "GenMsgCycleTime" BO_ 1505 200;
BA_ "GenMsgILSupport" BO_ 1505 1;
BA_ "GenMsgSendType" BO_ 1505 0;
BA_ "GenMsgCycleTime" BO_ 2549088302 500;
BA_ "GenMsgILSupport" BO_ 2549088302 1;
BA_ "GenMsgSendType" BO_ 2549088302 0;
BA_ "GenMsgCycleTime" BO_ 2549088356 500;
BA_ "GenMsgILSupport" BO_ 2549088356 1;
BA_ "GenMsgSendType" BO_ 2549088356 0;
BA_ "GenMsgCycleTime" BO_ 2549088304 500;
BA_ "GenMsgILSupport" BO_ 2549088304 1;
BA_ "GenMsgSendType" BO_ 2549088304 0;
BA_ "GenMsgCycleTime" BO_ 2549088272 500;
BA_ "GenMsgILSupport" BO_ 2549088272 1;
BA_ "GenMsgSendType" BO_ 2549088272 0;
BA_ "GenMsgStartDelayTime" BO_ 2549088272 75;
BA_ "GenMsgCycleTime" BO_ 2549088295 500;
BA_ "GenMsgILSupport" BO_ 2549088295 1;
BA_ "GenMsgSendType" BO_ 2549088295 0;
BA_ "GenMsgCycleTime" BO_ 2549088267 500;
BA_ "GenMsgILSupport" BO_ 2549088267 1;
BA_ "GenMsgSendType" BO_ 2549088267 0;
BA_ "GenMsgCycleTime" BO_ 2549088361 500;
BA_ "GenMsgILSupport" BO_ 2549088361 1;
BA_ "GenMsgSendType" BO_ 2549088361 0;
BA_ "GenMsgCycleTime" BO_ 2549088284 500;
BA_ "GenMsgILSupport" BO_ 2549088284 1;
BA_ "GenMsgSendType" BO_ 2549088284 0;
BA_ "GenMsgCycleTime" BO_ 2549088298 500;
BA_ "GenMsgILSupport" BO_ 2549088298 1;
BA_ "GenMsgSendType" BO_ 2549088298 0;
BA_ "GenMsgCycleTime" BO_ 2549088362 500;
BA_ "GenMsgILSupport" BO_ 2549088362 1;
BA_ "GenMsgSendType" BO_ 2549088362 0;
BA_ "GenMsgCycleTime" BO_ 2549088334 500;
BA_ "GenMsgILSupport" BO_ 2549088334 1;
BA_ "GenMsgSendType" BO_ 2549088334 0;
BA_ "GenMsgCycleTime" BO_ 2549088394 500;
BA_ "GenMsgILSupport" BO_ 2549088394 1;
BA_ "GenMsgSendType" BO_ 2549088394 0;
BA_ "GenMsgCycleTime" BO_ 779 50;
BA_ "GenMsgILSupport" BO_ 779 1;
BA_ "GenMsgSendType" BO_ 779 0;
BA_ "GenMsgCycleTime" BO_ 1719 1000;
BA_ "GenMsgDelayTime" BO_ 1719 100;
BA_ "GenMsgILSupport" BO_ 1719 1;
BA_ "GenMsgSendType" BO_ 1719 0;
BA_ "GenMsgCycleTime" BO_ 2527679639 1000;
BA_ "GenMsgCycleTimeFast" BO_ 2527679639 100;
BA_ "GenMsgDelayTime" BO_ 2527679639 100;
BA_ "GenMsgILSupport" BO_ 2527679639 1;
BA_ "GenMsgSendType" BO_ 2527679639 0;
BA_ "GenMsgCycleTime" BO_ 1614 1000;
BA_ "GenMsgDelayTime" BO_ 1614 20;
BA_ "GenMsgILSupport" BO_ 1614 1;
BA_ "GenMsgSendType" BO_ 1614 0;
BA_ "MsgType" BO_ 2549874983 4;
BA_ "MsgType" BO_ 2550006055 4;
BA_ "MsgType" BO_ 2549875082 4;
BA_ "MsgType" BO_ 2550006154 4;
BA_ "MsgType" BO_ 2549875022 4;
BA_ "MsgType" BO_ 2550006094 4;
BA_ "GenMsgCycleTime" BO_ 160 10;
BA_ "GenMsgILSupport" BO_ 160 1;
BA_ "GenMsgPDUConstants" BO_ 160 "0x4a,0xb4,0xe8,0x24,0x99,0x5a,0x59,0x8b,0x1e,0xaa,0x94,0xb6,0x09,0xd5,0xaf,0x97";
BA_ "GenMsgSendType" BO_ 160 0;
BA_ "GenMsgCycleTime" BO_ 981 100;
BA_ "GenMsgDelayTime" BO_ 981 50;
BA_ "GenMsgILSupport" BO_ 981 1;
BA_ "GenMsgPDUConstants" BO_ 981 "0xc5,0x39,0xc7,0xf9,0x92,0xd8,0x24,0xce,0xf1,0xb5,0x7a,0xc4,0xbc,0x60,0xe3,0xd1";
BA_ "GenMsgSendType" BO_ 981 0;
BA_ "GenMsgCycleTime" BO_ 1624 1000;
BA_ "GenMsgDelayTime" BO_ 1624 50;
BA_ "GenMsgILSupport" BO_ 1624 1;
BA_ "GenMsgPDUConstants" BO_ 1624 "0x46,0x0f,0xe0,0xcc,0xbe,0xb1,0xd7,0xf1,0x1f,0x31,0xc1,0x25,0xb4,0x3e,0xc8,0xa3";
BA_ "GenMsgSendType" BO_ 1624 0;
BA_ "GenMsgChkConstant" BO_ 134 134;
BA_ "GenMsgCycleTime" BO_ 134 10;
BA_ "GenMsgILSupport" BO_ 134 1;
BA_ "GenMsgPDUConstants" BO_ 134 "0x86,0x86,0x86,0x86,0x86,0x86,0x86,0x86,0x86,0x86,0x86,0x86,0x86,0x86,0x86,0x86";
BA_ "GenMsgSendType" BO_ 134 0;
BA_ "GenSigSendType" SG_ 1646 KL_Anf_AussenspiegelHzg 3;
BA_ "GenSigSwitchedByIgnition" SG_ 1646 KL_Anf_AussenspiegelHzg 0;
BA_ "GenSigSendType" SG_ 1646 KL_BCmE_Livetip_Freigabe 3;
BA_ "GenSigSwitchedByIgnition" SG_ 1646 KL_BCmE_Livetip_Freigabe 0;
BA_ "GenSigSendType" SG_ 1646 KL_ErwVK_Anf 3;
BA_ "GenSigSwitchedByIgnition" SG_ 1646 KL_ErwVK_Anf 0;
BA_ "GenSigSendType" SG_ 1646 KL_ErwVK_Zusatzrelais 3;
BA_ "GenSigSwitchedByIgnition" SG_ 1646 KL_ErwVK_Zusatzrelais 0;
BA_ "GenSigSendType" SG_ 1646 KL_FSH_Automatikbetrieb 3;
BA_ "GenSigSwitchedByIgnition" SG_ 1646 KL_FSH_Automatikbetrieb 0;
BA_ "GenSigSendType" SG_ 1646 KL_Geblaese_Fond_Status 0;
BA_ "GenSigStartValue" SG_ 1646 KL_Geblaese_Fond_Status 14;
BA_ "GenSigSwitchedByIgnition" SG_ 1646 KL_Geblaese_Fond_Status 0;
BA_ "Fehlerwert" SG_ 1646 KL_Geblaese_Fond_Status 15;
BA_ "GenSigSendType" SG_ 1646 KL_Geblaese_Status 0;
BA_ "GenSigStartValue" SG_ 1646 KL_Geblaese_Status 14;
BA_ "GenSigSwitchedByIgnition" SG_ 1646 KL_Geblaese_Status 0;
BA_ "Fehlerwert" SG_ 1646 KL_Geblaese_Status 15;
BA_ "GenSigSendType" SG_ 1646 KL_Heizkreisventilstellung 0;
BA_ "GenSigSwitchedByIgnition" SG_ 1646 KL_Heizkreisventilstellung 0;
BA_ "Fehlerwert" SG_ 1646 KL_Heizkreisventilstellung 3;
BA_ "GenSigSendType" SG_ 1646 KL_HYB_ASV_hinten_schliessen_Anf 3;
BA_ "GenSigSwitchedByIgnition" SG_ 1646 KL_HYB_ASV_hinten_schliessen_Anf 0;
BA_ "GenSigSendType" SG_ 1646 KL_HYB_ASV_vorne_schliessen_Anf 3;
BA_ "GenSigSwitchedByIgnition" SG_ 1646 KL_HYB_ASV_vorne_schliessen_Anf 0;
BA_ "GenSigSendType" SG_ 1646 KL_I_Geblaese_Fond 3;
BA_ "GenSigSwitchedByIgnition" SG_ 1646 KL_I_Geblaese_Fond 0;
BA_ "Fehlerwert" SG_ 1646 KL_I_Geblaese_Fond 255;
BA_ "GenSigSendType" SG_ 1646 KL_Innen_Temp 0;
BA_ "GenSigStartValue" SG_ 1646 KL_Innen_Temp 254;
BA_ "GenSigSwitchedByIgnition" SG_ 1646 KL_Innen_Temp 0;
BA_ "Fehlerwert" SG_ 1646 KL_Innen_Temp 255;
BA_ "GenSigSendType" SG_ 1646 KL_Kompressorkupplung 3;
BA_ "GenSigSwitchedByIgnition" SG_ 1646 KL_Kompressorkupplung 0;
BA_ "GenSigSendType" SG_ 1646 KL_Magnetventil 3;
BA_ "GenSigSwitchedByIgnition" SG_ 1646 KL_Magnetventil 0;
BA_ "GenSigSendType" SG_ 1646 KL_Restwaerme_aktiv 3;
BA_ "GenSigSwitchedByIgnition" SG_ 1646 KL_Restwaerme_aktiv 0;
BA_ "GenSigSendType" SG_ 1646 KL_SIH_LEH_Verteilung_VL 3;
BA_ "GenSigSwitchedByIgnition" SG_ 1646 KL_SIH_LEH_Verteilung_VL 0;
BA_ "GenSigSendType" SG_ 1646 KL_SIH_LEH_Verteilung_VR 3;
BA_ "GenSigSwitchedByIgnition" SG_ 1646 KL_SIH_LEH_Verteilung_VR 0;
BA_ "GenSigSendType" SG_ 1646 KL_SIH_LEL_Verteilung_VL 3;
BA_ "GenSigSwitchedByIgnition" SG_ 1646 KL_SIH_LEL_Verteilung_VL 0;
BA_ "GenSigSendType" SG_ 1646 KL_SIH_LEL_Verteilung_VR 3;
BA_ "GenSigSwitchedByIgnition" SG_ 1646 KL_SIH_LEL_Verteilung_VR 0;
BA_ "GenSigSendType" SG_ 1646 KL_Solarluefter_aktiv 3;
BA_ "GenSigSwitchedByIgnition" SG_ 1646 KL_Solarluefter_aktiv 0;
BA_ "GenSigSendType" SG_ 1646 KL_Status_Beduftung 3;
BA_ "GenSigSwitchedByIgnition" SG_ 1646 KL_Status_Beduftung 0;
BA_ "GenSigSendType" SG_ 1646 KL_Status_Ionisator_Front 3;
BA_ "GenSigSwitchedByIgnition" SG_ 1646 KL_Status_Ionisator_Front 0;
BA_ "GenSigSendType" SG_ 1646 KL_STH_aktiv 3;
BA_ "GenSigSwitchedByIgnition" SG_ 1646 KL_STH_aktiv 0;
BA_ "GenSigSendType" SG_ 1646 KL_STH_Ansteuerung 3;
BA_ "GenSigSwitchedByIgnition" SG_ 1646 KL_STH_Ansteuerung 0;
BA_ "GenSigSendType" SG_ 1646 KL_STH_Betriebsdauer 3;
BA_ "GenSigSwitchedByIgnition" SG_ 1646 KL_STH_Betriebsdauer 0;
BA_ "GenSigSendType" SG_ 1646 KL_STH_Timer_Status 3;
BA_ "GenSigSwitchedByIgnition" SG_ 1646 KL_STH_Timer_Status 0;
BA_ "GenSigSendType" SG_ 1646 KL_STL_aktiv 3;
BA_ "GenSigSwitchedByIgnition" SG_ 1646 KL_STL_aktiv 0;
BA_ "GenSigSendType" SG_ 1646 KL_Umluft_Taste 3;
BA_ "GenSigSwitchedByIgnition" SG_ 1646 KL_Umluft_Taste 0;
BA_ "GenSigSendType" SG_ 1646 KL_WaPu 3;
BA_ "GenSigSwitchedByIgnition" SG_ 1646 KL_WaPu 0;
BA_ "GenSigSendType" SG_ 1649 KL_Betriebsmodus_FH 3;
BA_ "GenSigSwitchedByIgnition" SG_ 1649 KL_Betriebsmodus_FH 0;
BA_ "GenSigSendType" SG_ 1649 KL_Stopp_Wiederstart_Anz_01 3;
BA_ "GenSigSwitchedByIgnition" SG_ 1649 KL_Stopp_Wiederstart_Anz_01 0;
BA_ "GenSigSendType" SG_ 1649 KL_Stopp_Wiederstart_Anz_02 3;
BA_ "GenSigSwitchedByIgnition" SG_ 1649 KL_Stopp_Wiederstart_Anz_02 0;
BA_ "GenSigSendType" SG_ 1649 KL_Stopp_Wiederstart_Anz_03 3;
BA_ "GenSigSwitchedByIgnition" SG_ 1649 KL_Stopp_Wiederstart_Anz_03 0;
BA_ "GenSigSendType" SG_ 1649 KL_Stopp_Wiederstart_Anz_04 3;
BA_ "GenSigSwitchedByIgnition" SG_ 1649 KL_Stopp_Wiederstart_Anz_04 0;
BA_ "GenSigSendType" SG_ 1649 KL_Stopp_Wiederstart_Anz_05 3;
BA_ "GenSigSwitchedByIgnition" SG_ 1649 KL_Stopp_Wiederstart_Anz_05 0;
BA_ "GenSigSendType" SG_ 1649 KL_Stopp_Wiederstart_Anz_06 3;
BA_ "GenSigSwitchedByIgnition" SG_ 1649 KL_Stopp_Wiederstart_Anz_06 0;
BA_ "GenSigSendType" SG_ 1649 KL_Stopp_Wiederstart_Anz_07 3;
BA_ "GenSigSwitchedByIgnition" SG_ 1649 KL_Stopp_Wiederstart_Anz_07 0;
BA_ "GenSigSendType" SG_ 1649 KL_Stopp_Wiederstart_Anz_08 3;
BA_ "GenSigSwitchedByIgnition" SG_ 1649 KL_Stopp_Wiederstart_Anz_08 0;
BA_ "GenSigSendType" SG_ 1649 KL_Stopp_Wiederstart_Anz_09 3;
BA_ "GenSigSwitchedByIgnition" SG_ 1649 KL_Stopp_Wiederstart_Anz_09 0;
BA_ "GenSigSendType" SG_ 1649 KL_Stopp_Wiederstart_Anz_Std1 3;
BA_ "GenSigSwitchedByIgnition" SG_ 1649 KL_Stopp_Wiederstart_Anz_Std1 0;
BA_ "GenSigSendType" SG_ 1649 KL_Stopp_Wiederstart_Anz_Std2 3;
BA_ "GenSigSwitchedByIgnition" SG_ 1649 KL_Stopp_Wiederstart_Anz_Std2 0;
BA_ "GenSigSendType" SG_ 1649 KL_ZZ_Betriebsmodus 3;
BA_ "GenSigSwitchedByIgnition" SG_ 1649 KL_ZZ_Betriebsmodus 0;
BA_ "GenSigSendType" SG_ 1649 KL_ZZ_Minute 3;
BA_ "GenSigSwitchedByIgnition" SG_ 1649 KL_ZZ_Minute 0;
BA_ "GenSigSendType" SG_ 1649 KL_ZZ_Monat 3;
BA_ "GenSigSwitchedByIgnition" SG_ 1649 KL_ZZ_Monat 0;
BA_ "GenSigSendType" SG_ 1649 KL_ZZ_Status_Timer 3;
BA_ "GenSigSwitchedByIgnition" SG_ 1649 KL_ZZ_Status_Timer 0;
BA_ "GenSigSendType" SG_ 1649 KL_ZZ_Stunde 3;
BA_ "GenSigSwitchedByIgnition" SG_ 1649 KL_ZZ_Stunde 0;
BA_ "GenSigSendType" SG_ 1649 KL_ZZ_Tag 3;
BA_ "GenSigSwitchedByIgnition" SG_ 1649 KL_ZZ_Tag 0;
BA_ "GenSigSendType" SG_ 949 KL_AC_Schalter 0;
BA_ "GenSigSwitchedByIgnition" SG_ 949 KL_AC_Schalter 0;
BA_ "GenSigSendType" SG_ 949 KL_Anf_KL 0;
BA_ "GenSigSwitchedByIgnition" SG_ 949 KL_Anf_KL 0;
BA_ "Fehlerwert" SG_ 949 KL_Anf_KL 255;
BA_ "GenSigSendType" SG_ 949 KL_Ausstattung_Klima 0;
BA_ "GenSigSwitchedByIgnition" SG_ 949 KL_Ausstattung_Klima 0;
BA_ "GenSigSendType" SG_ 949 KL_Charisma_FahrPr 0;
BA_ "GenSigSwitchedByIgnition" SG_ 949 KL_Charisma_FahrPr 0;
BA_ "GenSigSendType" SG_ 949 KL_Charisma_Status 0;
BA_ "GenSigSwitchedByIgnition" SG_ 949 KL_Charisma_Status 0;
BA_ "GenSigSendType" SG_ 949 KL_Drehz_Anh 0;
BA_ "GenSigSwitchedByIgnition" SG_ 949 KL_Drehz_Anh 0;
BA_ "GenSigSendType" SG_ 949 KL_el_Zuheizer_Stufe 0;
BA_ "GenSigSwitchedByIgnition" SG_ 949 KL_el_Zuheizer_Stufe 0;
BA_ "GenSigSendType" SG_ 949 KL_Freilauf_Info 0;
BA_ "GenSigSwitchedByIgnition" SG_ 949 KL_Freilauf_Info 0;
BA_ "GenSigSendType" SG_ 949 KL_Komp_Moment_alt 0;
BA_ "GenSigFuncType" SG_ 949 KL_Komp_Moment_alt 5;
BA_ "GenSigSwitchedByIgnition" SG_ 949 KL_Komp_Moment_alt 0;
BA_ "GenSigSendType" SG_ 949 KL_Kompressorkupplung_linear 0;
BA_ "GenSigStartValue" SG_ 949 KL_Kompressorkupplung_linear 254;
BA_ "GenSigSwitchedByIgnition" SG_ 949 KL_Kompressorkupplung_linear 0;
BA_ "GenSigSendType" SG_ 949 KL_Last_Kompr 0;
BA_ "GenSigSwitchedByIgnition" SG_ 949 KL_Last_Kompr 0;
BA_ "Fehlerwert" SG_ 949 KL_Last_Kompr 255;
BA_ "GenSigSendType" SG_ 949 KL_nachtr_Stopp_Anf 0;
BA_ "GenSigSwitchedByIgnition" SG_ 949 KL_nachtr_Stopp_Anf 0;
BA_ "GenSigSendType" SG_ 949 KL_Spannungs_Anf 0;
BA_ "GenSigSwitchedByIgnition" SG_ 949 KL_Spannungs_Anf 0;
BA_ "GenSigSendType" SG_ 949 KL_StartStopp_Info 0;
BA_ "GenSigSwitchedByIgnition" SG_ 949 KL_StartStopp_Info 0;
BA_ "GenSigSendType" SG_ 949 KL_T_Charge 0;
BA_ "GenSigSwitchedByIgnition" SG_ 949 KL_T_Charge 0;
BA_ "GenSigSendType" SG_ 949 KL_Thermomanagement 0;
BA_ "GenSigSwitchedByIgnition" SG_ 949 KL_Thermomanagement 0;
BA_ "GenSigSendType" SG_ 949 KL_Variante_Standheizung 0;
BA_ "GenSigSwitchedByIgnition" SG_ 949 KL_Variante_Standheizung 0;
BA_ "GenSigSendType" SG_ 949 KL_Vorwarn_Komp_ein 0;
BA_ "GenSigSwitchedByIgnition" SG_ 949 KL_Vorwarn_Komp_ein 0;
BA_ "GenSigSendType" SG_ 949 KL_Vorwarn_Zuheizer_ein 0;
BA_ "GenSigSwitchedByIgnition" SG_ 949 KL_Vorwarn_Zuheizer_ein 0;
BA_ "GenSigSendType" SG_ 949 KL_Zustand 0;
BA_ "GenSigSwitchedByIgnition" SG_ 949 KL_Zustand 0;
BA_ "GenSigActiveRepetitions" SG_ 1640 FSH_Taster 5;
BA_ "GenSigSendType" SG_ 1640 FSH_Taster 4;
BA_ "GenSigSwitchedByIgnition" SG_ 1640 FSH_Taster 0;
BA_ "GenSigActiveRepetitions" SG_ 1640 HSH_Taster 5;
BA_ "GenSigSendType" SG_ 1640 HSH_Taster 4;
BA_ "GenSigSwitchedByIgnition" SG_ 1640 HSH_Taster 0;
BA_ "GenSigSendType" SG_ 1640 KL_Beschlagsgefahr 3;
BA_ "GenSigSwitchedByIgnition" SG_ 1640 KL_Beschlagsgefahr 0;
BA_ "GenSigSendType" SG_ 1640 KL_Geblspng_Fond_Soll 0;
BA_ "GenSigSwitchedByIgnition" SG_ 1640 KL_Geblspng_Fond_Soll 0;
BA_ "Fehlerwert" SG_ 1640 KL_Geblspng_Fond_Soll 255;
BA_ "GenSigSendType" SG_ 1640 KL_Geblspng_Soll 0;
BA_ "GenSigSwitchedByIgnition" SG_ 1640 KL_Geblspng_Soll 0;
BA_ "Fehlerwert" SG_ 1640 KL_Geblspng_Soll 255;
BA_ "GenSigSendType" SG_ 1640 KL_I_Geblaese 0;
BA_ "GenSigSwitchedByIgnition" SG_ 1640 KL_I_Geblaese 0;
BA_ "Fehlerwert" SG_ 1640 KL_I_Geblaese 255;
BA_ "GenSigSendType" SG_ 1640 KL_Kompressorstrom_soll 0;
BA_ "GenSigStartValue" SG_ 1640 KL_Kompressorstrom_soll 1022;
BA_ "GenSigSwitchedByIgnition" SG_ 1640 KL_Kompressorstrom_soll 0;
BA_ "Fehlerwert" SG_ 1640 KL_Kompressorstrom_soll 1023;
BA_ "GenSigSendType" SG_ 1640 KL_LRH_Stufe 0;
BA_ "GenSigStartValue" SG_ 1640 KL_LRH_Stufe 1;
BA_ "GenSigSwitchedByIgnition" SG_ 1640 KL_LRH_Stufe 0;
BA_ "GenSigActiveRepetitions" SG_ 1640 KL_LRH_Taster 5;
BA_ "GenSigSendType" SG_ 1640 KL_LRH_Taster 4;
BA_ "GenSigSwitchedByIgnition" SG_ 1640 KL_LRH_Taster 0;
BA_ "GenSigSendType" SG_ 1640 KL_PTC_Verbauinfo 0;
BA_ "GenSigSwitchedByIgnition" SG_ 1640 KL_PTC_Verbauinfo 0;
BA_ "GenSigSendType" SG_ 1640 KL_SIH_Soll_li 3;
BA_ "GenSigSwitchedByIgnition" SG_ 1640 KL_SIH_Soll_li 0;
BA_ "GenSigSendType" SG_ 1640 KL_SIH_Soll_re 3;
BA_ "GenSigSwitchedByIgnition" SG_ 1640 KL_SIH_Soll_re 0;
BA_ "GenSigSendType" SG_ 1640 KL_SIL_Soll_li 3;
BA_ "GenSigSwitchedByIgnition" SG_ 1640 KL_SIL_Soll_li 0;
BA_ "GenSigSendType" SG_ 1640 KL_SIL_Soll_re 3;
BA_ "GenSigSwitchedByIgnition" SG_ 1640 KL_SIL_Soll_re 0;
BA_ "GenSigSendType" SG_ 1640 KL_Umluftklappe_Status 0;
BA_ "GenSigStartValue" SG_ 1640 KL_Umluftklappe_Status 14;
BA_ "GenSigSwitchedByIgnition" SG_ 1640 KL_Umluftklappe_Status 0;
BA_ "Fehlerwert" SG_ 1640 KL_Umluftklappe_Status 15;
BA_ "GenSigSendType" SG_ 1640 KL_Zuheizer_Freigabe 3;
BA_ "GenSigSwitchedByIgnition" SG_ 1640 KL_Zuheizer_Freigabe 0;
BA_ "GenSigSendType" SG_ 1640 KRH_Soll_li 3;
BA_ "GenSigSwitchedByIgnition" SG_ 1640 KRH_Soll_li 0;
BA_ "GenSigSendType" SG_ 1640 KRH_Soll_re 3;
BA_ "GenSigSwitchedByIgnition" SG_ 1640 KRH_Soll_re 0;
BA_ "GenSigSendType" SG_ 1505 BCM1_Aussen_Temp_ungef 0;
BA_ "GenSigStartValue" SG_ 1505 BCM1_Aussen_Temp_ungef 254;
BA_ "GenSigSwitchedByIgnition" SG_ 1505 BCM1_Aussen_Temp_ungef 0;
BA_ "Fehlerwert" SG_ 1505 BCM1_Aussen_Temp_ungef 255;
BA_ "GenSigSendType" SG_ 1505 BCM1_FStatus_Aussentemp_ungef 0;
BA_ "GenSigStartValue" SG_ 1505 BCM1_FStatus_Aussentemp_ungef 1;
BA_ "GenSigSwitchedByIgnition" SG_ 1505 BCM1_FStatus_Aussentemp_ungef 0;
BA_ "GenSigSendType" SG_ 1505 BCM1_Kompressorstrom_ist 0;
BA_ "GenSigStartValue" SG_ 1505 BCM1_Kompressorstrom_ist 254;
BA_ "GenSigSwitchedByIgnition" SG_ 1505 BCM1_Kompressorstrom_ist 0;
BA_ "Fehlerwert" SG_ 1505 BCM1_Kompressorstrom_ist 255;
BA_ "GenSigSendType" SG_ 1505 BCM1_OBD_FStatus_ATemp 0;
BA_ "GenSigSwitchedByIgnition" SG_ 1505 BCM1_OBD_FStatus_ATemp 0;
BA_ "GenSigSendType" SG_ 1505 BCM1_PTC_stufig_Status 0;
BA_ "GenSigStartValue" SG_ 1505 BCM1_PTC_stufig_Status 6;
BA_ "GenSigSwitchedByIgnition" SG_ 1505 BCM1_PTC_stufig_Status 0;
BA_ "Fehlerwert" SG_ 1505 BCM1_PTC_stufig_Status 7;
BA_ "GenSigSendType" SG_ 1505 BCM_Heizungsabsperrventil_Status 0;
BA_ "GenSigStartValue" SG_ 1505 BCM_Heizungsabsperrventil_Status 2;
BA_ "GenSigSwitchedByIgnition" SG_ 1505 BCM_Heizungsabsperrventil_Status 0;
BA_ "Fehlerwert" SG_ 1505 BCM_Heizungsabsperrventil_Status 3;
BA_ "GenSigSendType" SG_ 1505 BCM_Heizungspumpe_Status 0;
BA_ "GenSigStartValue" SG_ 1505 BCM_Heizungspumpe_Status 2;
BA_ "GenSigSwitchedByIgnition" SG_ 1505 BCM_Heizungspumpe_Status 0;
BA_ "Fehlerwert" SG_ 1505 BCM_Heizungspumpe_Status 3;
BA_ "GenSigSendType" SG_ 1505 BCM_Kompressorkupplung_Status 0;
BA_ "GenSigStartValue" SG_ 1505 BCM_Kompressorkupplung_Status 2;
BA_ "GenSigSwitchedByIgnition" SG_ 1505 BCM_Kompressorkupplung_Status 0;
BA_ "Fehlerwert" SG_ 1505 BCM_Kompressorkupplung_Status 3;
BA_ "GenSigSendType" SG_ 2549088302 AEM_Abschaltstufe 0;
BA_ "GenSigSendType" SG_ 2549088302 AEM_KD_Fehler 0;
BA_ "GenSigSendType" SG_ 2549088302 AEM_KompSchutz 0;
BA_ "GenSigSendType" SG_ 2549088302 AEM_Lokalaktiv 0;
BA_ "GenSigSendType" SG_ 2549088302 AEM_Nachlauftyp 0;
BA_ "GenSigSendType" SG_ 2549088302 AEM_SNI 0;
BA_ "GenSigStartValue" SG_ 2549088302 AEM_SNI 46;
BA_ "GenSigSendType" SG_ 2549088302 AEM_Subsystemaktiv 0;
BA_ "GenSigSendType" SG_ 2549088302 AEM_Transport_Mode 0;
BA_ "GenSigSendType" SG_ 2549088302 NM_AEM_Wakeup 0;
BA_ "NWM-WakeupAllowed" SG_ 2549088302 NM_AEM_Wakeup 1;
BA_ "GenSigSendType" SG_ 2549088356 AGA_Abschaltstufe 0;
BA_ "GenSigSendType" SG_ 2549088356 AGA_KD_Fehler 0;
BA_ "GenSigSendType" SG_ 2549088356 AGA_KompSchutz 0;
BA_ "GenSigSendType" SG_ 2549088356 AGA_Lokalaktiv 0;
BA_ "GenSigSendType" SG_ 2549088356 AGA_Nachlauftyp 0;
BA_ "GenSigSendType" SG_ 2549088356 AGA_SNI 0;
BA_ "GenSigStartValue" SG_ 2549088356 AGA_SNI 100;
BA_ "GenSigSendType" SG_ 2549088356 AGA_Subsystemaktiv 0;
BA_ "GenSigSendType" SG_ 2549088356 AGA_Transport_Mode 0;
BA_ "GenSigSendType" SG_ 2549088356 NM_AGA_Wakeup 0;
BA_ "NWM-WakeupAllowed" SG_ 2549088356 NM_AGA_Wakeup 1;
BA_ "GenSigSendType" SG_ 2549088304 FLA_Abschaltstufe 0;
BA_ "GenSigSendType" SG_ 2549088304 FLA_KD_Fehler 0;
BA_ "GenSigSendType" SG_ 2549088304 FLA_KompSchutz 0;
BA_ "GenSigSendType" SG_ 2549088304 FLA_Lokalaktiv 0;
BA_ "GenSigSendType" SG_ 2549088304 FLA_Nachlauftyp 0;
BA_ "GenSigSendType" SG_ 2549088304 FLA_SNI 0;
BA_ "GenSigStartValue" SG_ 2549088304 FLA_SNI 48;
BA_ "GenSigSendType" SG_ 2549088304 FLA_Subsystemaktiv 0;
BA_ "GenSigSendType" SG_ 2549088304 FLA_Transport_Mode 0;
BA_ "GenSigSendType" SG_ 2549088304 NM_FLA_Wakeup 0;
BA_ "NWM-WakeupAllowed" SG_ 2549088304 NM_FLA_Wakeup 1;
BA_ "GenSigSendType" SG_ 2549088272 Gateway_Abschaltstufe 0;
BA_ "GenSigSwitchedByIgnition" SG_ 2549088272 Gateway_Abschaltstufe 0;
BA_ "GenSigSendType" SG_ 2549088272 Gateway_KompSchutz 0;
BA_ "GenSigSwitchedByIgnition" SG_ 2549088272 Gateway_KompSchutz 0;
BA_ "GenSigSendType" SG_ 2549088272 Gateway_Matrix_Generation 0;
BA_ "GenSigSwitchedByIgnition" SG_ 2549088272 Gateway_Matrix_Generation 0;
BA_ "GenSigSendType" SG_ 2549088272 Gateway_Matrix_Version 0;
BA_ "GenSigSwitchedByIgnition" SG_ 2549088272 Gateway_Matrix_Version 0;
BA_ "GenSigSendType" SG_ 2549088272 Gateway_Nachlauftyp 0;
BA_ "GenSigStartValue" SG_ 2549088272 Gateway_Nachlauftyp 2;
BA_ "GenSigSwitchedByIgnition" SG_ 2549088272 Gateway_Nachlauftyp 0;
BA_ "GenSigSendType" SG_ 2549088272 Gateway_SNI 0;
BA_ "GenSigStartValue" SG_ 2549088272 Gateway_SNI 16;
BA_ "GenSigSwitchedByIgnition" SG_ 2549088272 Gateway_SNI 0;
BA_ "GenSigSendType" SG_ 2549088272 Gateway_Transport_Mode 0;
BA_ "GenSigSwitchedByIgnition" SG_ 2549088272 Gateway_Transport_Mode 0;
BA_ "GenSigSendType" SG_ 2549088272 GW_KD_Fehler 0;
BA_ "GenSigSendType" SG_ 2549088272 NM_Gateway_Lokalaktiv 0;
BA_ "GenSigSwitchedByIgnition" SG_ 2549088272 NM_Gateway_Lokalaktiv 0;
BA_ "GenSigSendType" SG_ 2549088272 NM_Gateway_Subsystemaktiv 0;
BA_ "GenSigSendType" SG_ 2549088272 NM_Gateway_Wakeup 0;
BA_ "NWM-WakeupAllowed" SG_ 2549088272 NM_Gateway_Wakeup 1;
BA_ "GenSigSwitchedByIgnition" SG_ 2549088272 NM_Gateway_Wakeup 0;
BA_ "GenSigSendType" SG_ 2549088295 Nightvision_Abschaltstufe 0;
BA_ "GenSigSendType" SG_ 2549088295 Nightvision_KD_Fehler 0;
BA_ "GenSigSendType" SG_ 2549088295 Nightvision_KompSchutz 0;
BA_ "GenSigSendType" SG_ 2549088295 Nightvision_Lokalaktiv 0;
BA_ "GenSigSendType" SG_ 2549088295 Nightvision_Nachlauftyp 0;
BA_ "GenSigSendType" SG_ 2549088295 Nightvision_SNI 0;
BA_ "GenSigStartValue" SG_ 2549088295 Nightvision_SNI 39;
BA_ "GenSigSendType" SG_ 2549088295 Nightvision_Subsystemaktiv 0;
BA_ "GenSigSendType" SG_ 2549088295 Nightvision_Transport_Mode 0;
BA_ "GenSigSendType" SG_ 2549088295 NM_Nightvision_Wakeup 0;
BA_ "NWM-WakeupAllowed" SG_ 2549088295 NM_Nightvision_Wakeup 1;
BA_ "GenSigSendType" SG_ 2549088267 KN_RDK_BusKnockOutTimer 0;
BA_ "GenSigSwitchedByIgnition" SG_ 2549088267 KN_RDK_BusKnockOutTimer 0;
BA_ "GenSigSendType" SG_ 2549088267 NM_RDK_Lokalaktiv 0;
BA_ "GenSigSwitchedByIgnition" SG_ 2549088267 NM_RDK_Lokalaktiv 0;
BA_ "GenSigSendType" SG_ 2549088267 NM_RDK_Subsystemaktiv 0;
BA_ "GenSigSwitchedByIgnition" SG_ 2549088267 NM_RDK_Subsystemaktiv 0;
BA_ "GenSigSendType" SG_ 2549088267 NM_RDK_Wakeup 0;
BA_ "NWM-WakeupAllowed" SG_ 2549088267 NM_RDK_Wakeup 1;
BA_ "GenSigSendType" SG_ 2549088267 RDK_Abschaltstufe 0;
BA_ "GenSigSwitchedByIgnition" SG_ 2549088267 RDK_Abschaltstufe 0;
BA_ "GenSigSendType" SG_ 2549088267 RDK_KD_Fehler 0;
BA_ "GenSigSwitchedByIgnition" SG_ 2549088267 RDK_KD_Fehler 0;
BA_ "GenSigSendType" SG_ 2549088267 RDK_KompSchutz 0;
BA_ "GenSigSwitchedByIgnition" SG_ 2549088267 RDK_KompSchutz 0;
BA_ "GenSigSendType" SG_ 2549088267 RDK_Nachlauftyp 0;
BA_ "GenSigSwitchedByIgnition" SG_ 2549088267 RDK_Nachlauftyp 0;
BA_ "GenSigSendType" SG_ 2549088267 RDK_SNI 0;
BA_ "GenSigStartValue" SG_ 2549088267 RDK_SNI 11;
BA_ "GenSigSwitchedByIgnition" SG_ 2549088267 RDK_SNI 0;
BA_ "GenSigSendType" SG_ 2549088267 RDK_Transport_Mode 0;
BA_ "GenSigSwitchedByIgnition" SG_ 2549088267 RDK_Transport_Mode 0;
BA_ "GenSigSendType" SG_ 2549088361 KN_Rearview_BusKnockOutTimer 0;
BA_ "GenSigSwitchedByIgnition" SG_ 2549088361 KN_Rearview_BusKnockOutTimer 0;
BA_ "GenSigSendType" SG_ 2549088361 NM_Rearview_Wakeup 0;
BA_ "NWM-WakeupAllowed" SG_ 2549088361 NM_Rearview_Wakeup 1;
BA_ "GenSigSwitchedByIgnition" SG_ 2549088361 NM_Rearview_Wakeup 0;
BA_ "GenSigSendType" SG_ 2549088361 Rearview_Abschaltstufe 0;
BA_ "GenSigSwitchedByIgnition" SG_ 2549088361 Rearview_Abschaltstufe 0;
BA_ "GenSigSendType" SG_ 2549088361 Rearview_KompSchutz 0;
BA_ "GenSigSwitchedByIgnition" SG_ 2549088361 Rearview_KompSchutz 0;
BA_ "GenSigSendType" SG_ 2549088361 Rearview_Lokalaktiv 0;
BA_ "GenSigSwitchedByIgnition" SG_ 2549088361 Rearview_Lokalaktiv 0;
BA_ "GenSigSendType" SG_ 2549088361 Rearview_Nachlauftyp 0;
BA_ "GenSigStartValue" SG_ 2549088361 Rearview_Nachlauftyp 2;
BA_ "GenSigSwitchedByIgnition" SG_ 2549088361 Rearview_Nachlauftyp 0;
BA_ "GenSigSendType" SG_ 2549088361 Rearview_SNI 0;
BA_ "GenSigStartValue" SG_ 2549088361 Rearview_SNI 105;
BA_ "GenSigSwitchedByIgnition" SG_ 2549088361 Rearview_SNI 0;
BA_ "GenSigSendType" SG_ 2549088361 Rearview_Subsystemaktiv 0;
BA_ "GenSigSwitchedByIgnition" SG_ 2549088361 Rearview_Subsystemaktiv 0;
BA_ "GenSigSendType" SG_ 2549088361 Rearview_Transport_Mode 0;
BA_ "GenSigSwitchedByIgnition" SG_ 2549088361 Rearview_Transport_Mode 0;
BA_ "GenSigSendType" SG_ 2549088361 RV_KD_Fehler 0;
BA_ "GenSigSwitchedByIgnition" SG_ 2549088361 RV_KD_Fehler 0;
BA_ "GenSigSendType" SG_ 2549088284 NM_SAK_Wakeup 0;
BA_ "NWM-WakeupAllowed" SG_ 2549088284 NM_SAK_Wakeup 1;
BA_ "GenSigSendType" SG_ 2549088284 SAK_Abschaltstufe 0;
BA_ "GenSigSendType" SG_ 2549088284 SAK_KD_Fehler 0;
BA_ "GenSigSendType" SG_ 2549088284 SAK_KompSchutz 0;
BA_ "GenSigSendType" SG_ 2549088284 SAK_Lokalaktiv 0;
BA_ "GenSigSendType" SG_ 2549088284 SAK_Nachlauftyp 0;
BA_ "GenSigSendType" SG_ 2549088284 SAK_SNI 0;
BA_ "GenSigStartValue" SG_ 2549088284 SAK_SNI 28;
BA_ "GenSigSendType" SG_ 2549088284 SAK_Subsystemaktiv 0;
BA_ "GenSigSendType" SG_ 2549088284 SAK_Transport_Mode 0;
BA_ "GenSigSendType" SG_ 2549088298 KN_SCR_BusKnockOut 0;
BA_ "GenSigSwitchedByIgnition" SG_ 2549088298 KN_SCR_BusKnockOut 0;
BA_ "GenSigSendType" SG_ 2549088298 KN_SCR_BusKnockOutTimer 0;
BA_ "GenSigSwitchedByIgnition" SG_ 2549088298 KN_SCR_BusKnockOutTimer 0;
BA_ "GenSigSendType" SG_ 2549088298 KN_SCR_ECUKnockOut 0;
BA_ "GenSigSwitchedByIgnition" SG_ 2549088298 KN_SCR_ECUKnockOut 0;
BA_ "GenSigSendType" SG_ 2549088298 KN_SCR_ECUKnockOutTimer 0;
BA_ "GenSigSwitchedByIgnition" SG_ 2549088298 KN_SCR_ECUKnockOutTimer 0;
BA_ "GenSigSendType" SG_ 2549088298 NM_SCR_Wakeup 0;
BA_ "NWM-WakeupAllowed" SG_ 2549088298 NM_SCR_Wakeup 1;
BA_ "GenSigSwitchedByIgnition" SG_ 2549088298 NM_SCR_Wakeup 0;
BA_ "GenSigSendType" SG_ 2549088298 NMH_SCR_Lokalaktiv 0;
BA_ "GenSigSwitchedByIgnition" SG_ 2549088298 NMH_SCR_Lokalaktiv 0;
BA_ "GenSigSendType" SG_ 2549088298 NMH_SCR_Subsystemaktiv 0;
BA_ "GenSigSwitchedByIgnition" SG_ 2549088298 NMH_SCR_Subsystemaktiv 0;
BA_ "GenSigSendType" SG_ 2549088298 SCR_Abschaltstufe 0;
BA_ "GenSigSwitchedByIgnition" SG_ 2549088298 SCR_Abschaltstufe 0;
BA_ "GenSigSendType" SG_ 2549088298 SCR_KD_Fehler 0;
BA_ "GenSigSwitchedByIgnition" SG_ 2549088298 SCR_KD_Fehler 0;
BA_ "GenSigSendType" SG_ 2549088298 SCR_KompSchutz 0;
BA_ "GenSigSwitchedByIgnition" SG_ 2549088298 SCR_KompSchutz 0;
BA_ "GenSigSendType" SG_ 2549088298 SCR_Nachlauftyp 0;
BA_ "GenSigStartValue" SG_ 2549088298 SCR_Nachlauftyp 2;
BA_ "GenSigSwitchedByIgnition" SG_ 2549088298 SCR_Nachlauftyp 0;
BA_ "GenSigSendType" SG_ 2549088298 SCR_SNI 0;
BA_ "GenSigStartValue" SG_ 2549088298 SCR_SNI 42;
BA_ "GenSigSwitchedByIgnition" SG_ 2549088298 SCR_SNI 0;
BA_ "GenSigSendType" SG_ 2549088298 SCR_Transport_Mode 0;
BA_ "GenSigSwitchedByIgnition" SG_ 2549088298 SCR_Transport_Mode 0;
BA_ "GenSigSendType" SG_ 2549088362 KN_STH_BusKnockOutTimer 0;
BA_ "GenSigSwitchedByIgnition" SG_ 2549088362 KN_STH_BusKnockOutTimer 0;
BA_ "GenSigSendType" SG_ 2549088362 NM_STH_Wakeup 0;
BA_ "NWM-WakeupAllowed" SG_ 2549088362 NM_STH_Wakeup 1;
BA_ "GenSigSwitchedByIgnition" SG_ 2549088362 NM_STH_Wakeup 0;
BA_ "GenSigSendType" SG_ 2549088362 NMH_STH_Lokalaktiv 0;
BA_ "GenSigSwitchedByIgnition" SG_ 2549088362 NMH_STH_Lokalaktiv 0;
BA_ "GenSigSendType" SG_ 2549088362 NMH_STH_Subsystemaktiv 0;
BA_ "GenSigSwitchedByIgnition" SG_ 2549088362 NMH_STH_Subsystemaktiv 0;
BA_ "GenSigSendType" SG_ 2549088362 STH_Abschaltstufe 0;
BA_ "GenSigSwitchedByIgnition" SG_ 2549088362 STH_Abschaltstufe 0;
BA_ "GenSigSendType" SG_ 2549088362 STH_KD_Fehler 0;
BA_ "GenSigSwitchedByIgnition" SG_ 2549088362 STH_KD_Fehler 0;
BA_ "GenSigSendType" SG_ 2549088362 STH_KompSchutz 0;
BA_ "GenSigSwitchedByIgnition" SG_ 2549088362 STH_KompSchutz 0;
BA_ "GenSigSendType" SG_ 2549088362 STH_Nachlauftyp 0;
BA_ "GenSigStartValue" SG_ 2549088362 STH_Nachlauftyp 2;
BA_ "GenSigSwitchedByIgnition" SG_ 2549088362 STH_Nachlauftyp 0;
BA_ "GenSigSendType" SG_ 2549088362 STH_SNI 0;
BA_ "GenSigStartValue" SG_ 2549088362 STH_SNI 106;
BA_ "GenSigSwitchedByIgnition" SG_ 2549088362 STH_SNI 0;
BA_ "GenSigSendType" SG_ 2549088362 STH_Transport_Mode 0;
BA_ "GenSigSwitchedByIgnition" SG_ 2549088362 STH_Transport_Mode 0;
BA_ "GenSigSendType" SG_ 2549088334 KN_SWA_BusKnockOutTimer 0;
BA_ "GenSigSwitchedByIgnition" SG_ 2549088334 KN_SWA_BusKnockOutTimer 0;
BA_ "GenSigSendType" SG_ 2549088334 NM_SWA_Wakeup 0;
BA_ "NWM-WakeupAllowed" SG_ 2549088334 NM_SWA_Wakeup 1;
BA_ "GenSigSwitchedByIgnition" SG_ 2549088334 NM_SWA_Wakeup 0;
BA_ "GenSigSendType" SG_ 2549088334 SWA_Abschaltstufe 0;
BA_ "GenSigSwitchedByIgnition" SG_ 2549088334 SWA_Abschaltstufe 0;
BA_ "GenSigSendType" SG_ 2549088334 SWA_KD_Fehler 0;
BA_ "GenSigSendType" SG_ 2549088334 SWA_KompSchutz 0;
BA_ "GenSigSwitchedByIgnition" SG_ 2549088334 SWA_KompSchutz 0;
BA_ "GenSigSendType" SG_ 2549088334 SWA_Lokalaktiv 0;
BA_ "GenSigSwitchedByIgnition" SG_ 2549088334 SWA_Lokalaktiv 0;
BA_ "GenSigSendType" SG_ 2549088334 SWA_Nachlauftyp 0;
BA_ "GenSigSendType" SG_ 2549088334 SWA_SNI 0;
BA_ "GenSigStartValue" SG_ 2549088334 SWA_SNI 78;
BA_ "GenSigSendType" SG_ 2549088334 SWA_Subsystemaktiv 0;
BA_ "GenSigSwitchedByIgnition" SG_ 2549088334 SWA_Subsystemaktiv 0;
BA_ "GenSigSendType" SG_ 2549088334 SWA_Transport_Mode 0;
BA_ "GenSigSwitchedByIgnition" SG_ 2549088334 SWA_Transport_Mode 0;
BA_ "GenSigSendType" SG_ 2549088394 KN_SWA_Slave_BusKnockOutTimer 0;
BA_ "GenSigSwitchedByIgnition" SG_ 2549088394 KN_SWA_Slave_BusKnockOutTimer 0;
BA_ "GenSigSendType" SG_ 2549088394 NM_SWA_2_Wakeup 0;
BA_ "NWM-WakeupAllowed" SG_ 2549088394 NM_SWA_2_Wakeup 1;
BA_ "GenSigSwitchedByIgnition" SG_ 2549088394 NM_SWA_2_Wakeup 0;
BA_ "GenSigSendType" SG_ 2549088394 SWA_2_Abschaltstufe 0;
BA_ "GenSigSendType" SG_ 2549088394 SWA_2_KD_Fehler 0;
BA_ "GenSigSendType" SG_ 2549088394 SWA_2_KompSchutz 0;
BA_ "GenSigSendType" SG_ 2549088394 SWA_2_Lokalaktiv 0;
BA_ "GenSigSwitchedByIgnition" SG_ 2549088394 SWA_2_Lokalaktiv 0;
BA_ "GenSigSendType" SG_ 2549088394 SWA_2_Nachlauftyp 0;
BA_ "GenSigSendType" SG_ 2549088394 SWA_2_SNI 0;
BA_ "GenSigStartValue" SG_ 2549088394 SWA_2_SNI 138;
BA_ "GenSigSendType" SG_ 2549088394 SWA_2_Subsystemaktiv 0;
BA_ "GenSigSwitchedByIgnition" SG_ 2549088394 SWA_2_Subsystemaktiv 0;
BA_ "GenSigSendType" SG_ 2549088394 SWA_2_Transport_Mode 0;
BA_ "GenSigSendType" SG_ 779 KBI_ABS_Lampe 0;
BA_ "GenSigSwitchedByIgnition" SG_ 779 KBI_ABS_Lampe 0;
BA_ "GenSigSendType" SG_ 779 KBI_Airbag_Lampe 0;
BA_ "GenSigSwitchedByIgnition" SG_ 779 KBI_Airbag_Lampe 0;
BA_ "GenSigSendType" SG_ 779 KBI_angez_Geschw 0;
BA_ "GenSigSwitchedByIgnition" SG_ 779 KBI_angez_Geschw 0;
BA_ "GenSigSendType" SG_ 779 KBI_Anzeigefehler_LDW 0;
BA_ "GenSigSwitchedByIgnition" SG_ 779 KBI_Anzeigefehler_LDW 0;
BA_ "GenSigSendType" SG_ 779 KBI_Anzeigefehler_NV 0;
BA_ "GenSigSwitchedByIgnition" SG_ 779 KBI_Anzeigefehler_NV 0;
BA_ "GenSigSendType" SG_ 779 KBI_Anzeigefehler_SWA 0;
BA_ "GenSigSwitchedByIgnition" SG_ 779 KBI_Anzeigefehler_SWA 0;
BA_ "GenSigSendType" SG_ 779 KBI_Anzeigestatus_ACC 0;
BA_ "GenSigSwitchedByIgnition" SG_ 779 KBI_Anzeigestatus_ACC 0;
BA_ "GenSigSendType" SG_ 779 KBI_Anzeigestatus_GRA 0;
BA_ "GenSigSwitchedByIgnition" SG_ 779 KBI_Anzeigestatus_GRA 0;
BA_ "Fehlerwert" SG_ 779 KBI_Anzeigestatus_GRA 3;
BA_ "GenSigSendType" SG_ 779 KBI_Anzeigestatus_LIM 0;
BA_ "GenSigSwitchedByIgnition" SG_ 779 KBI_Anzeigestatus_LIM 0;
BA_ "Fehlerwert" SG_ 779 KBI_Anzeigestatus_LIM 3;
BA_ "GenSigSendType" SG_ 779 KBI_ARA_in_Anzeige 0;
BA_ "GenSigSwitchedByIgnition" SG_ 779 KBI_ARA_in_Anzeige 0;
BA_ "GenSigSendType" SG_ 779 KBI_Bestaetigung_ESP_Off 3;
BA_ "GenSigSwitchedByIgnition" SG_ 779 KBI_Bestaetigung_ESP_Off 0;
BA_ "GenSigSendType" SG_ 779 KBI_BKL_Lampe 0;
BA_ "GenSigSwitchedByIgnition" SG_ 779 KBI_BKL_Lampe 0;
BA_ "GenSigSendType" SG_ 779 KBI_Einheit_Tacho 0;
BA_ "GenSigSwitchedByIgnition" SG_ 779 KBI_Einheit_Tacho 0;
BA_ "GenSigSendType" SG_ 779 KBI_ESP_Lampe 0;
BA_ "GenSigSwitchedByIgnition" SG_ 779 KBI_ESP_Lampe 0;
BA_ "GenSigSendType" SG_ 779 KBI_Fehler_Anzeige_ACC 0;
BA_ "GenSigSwitchedByIgnition" SG_ 779 KBI_Fehler_Anzeige_ACC 0;
BA_ "GenSigSendType" SG_ 779 KBI_GRA_Hauptschalter 0;
BA_ "GenSigSwitchedByIgnition" SG_ 779 KBI_GRA_Hauptschalter 0;
BA_ "Fehlerwert" SG_ 779 KBI_GRA_Hauptschalter 3;
BA_ "GenSigSendType" SG_ 779 KBI_Handbremse 0;
BA_ "GenSigSwitchedByIgnition" SG_ 779 KBI_Handbremse 0;
BA_ "GenSigSendType" SG_ 779 KBI_im_Stellgliedtest 0;
BA_ "GenSigSwitchedByIgnition" SG_ 779 KBI_im_Stellgliedtest 0;
BA_ "GenSigSendType" SG_ 779 KBI_Konsistenz_ACC 0;
BA_ "GenSigSwitchedByIgnition" SG_ 779 KBI_Konsistenz_ACC 0;
BA_ "GenSigSendType" SG_ 779 KBI_Lenkung_Lampe 0;
BA_ "GenSigSwitchedByIgnition" SG_ 779 KBI_Lenkung_Lampe 0;
BA_ "GenSigSendType" SG_ 779 KBI_MFA_v_Einheit_01 0;
BA_ "GenSigSwitchedByIgnition" SG_ 779 KBI_MFA_v_Einheit_01 0;
BA_ "GenSigSendType" SG_ 779 KBI_NV_in_Anzeige 0;
BA_ "GenSigSwitchedByIgnition" SG_ 779 KBI_NV_in_Anzeige 0;
BA_ "GenSigSendType" SG_ 779 KBI_PLA_in_Anzeige 0;
BA_ "GenSigSwitchedByIgnition" SG_ 779 KBI_PLA_in_Anzeige 0;
BA_ "GenSigSendType" SG_ 779 KBI_SILA_gueltig 0;
BA_ "GenSigSwitchedByIgnition" SG_ 779 KBI_SILA_gueltig 0;
BA_ "GenSigSendType" SG_ 779 KBI_Systemstatus 0;
BA_ "GenSigSwitchedByIgnition" SG_ 779 KBI_Systemstatus 0;
BA_ "GenSigSendType" SG_ 779 KBI_Tankwarnung 0;
BA_ "GenSigSwitchedByIgnition" SG_ 779 KBI_Tankwarnung 0;
BA_ "GenSigSendType" SG_ 779 KBI_Tankwarnung_ungueltig 0;
BA_ "GenSigStartValue" SG_ 779 KBI_Tankwarnung_ungueltig 1;
BA_ "GenSigSwitchedByIgnition" SG_ 779 KBI_Tankwarnung_ungueltig 0;
BA_ "GenSigSendType" SG_ 779 KBI_Taster_Fahrwerk 0;
BA_ "GenSigSwitchedByIgnition" SG_ 779 KBI_Taster_Fahrwerk 0;
BA_ "GenSigSendType" SG_ 779 KBI_Taster_Lift 0;
BA_ "GenSigSwitchedByIgnition" SG_ 779 KBI_Taster_Lift 0;
BA_ "GenSigSendType" SG_ 779 KBI_V_Digital 0;
BA_ "GenSigSwitchedByIgnition" SG_ 779 KBI_V_Digital 0;
BA_ "GenSigSendType" SG_ 779 KBI_Vorglueh_System_Lampe 0;
BA_ "GenSigSwitchedByIgnition" SG_ 779 KBI_Vorglueh_System_Lampe 0;
BA_ "GenSigSendType" SG_ 779 Kombi_01_BZ 0;
BA_ "GenSigFuncType" SG_ 779 Kombi_01_BZ 1;
BA_ "GenSigSwitchedByIgnition" SG_ 779 Kombi_01_BZ 0;
BA_ "GenSigSendType" SG_ 1719 KBI_aktive_Laengsfunktion 3;
BA_ "GenSigSendType" SG_ 1719 KBI_Aussen_Temp_gef 0;
BA_ "GenSigStartValue" SG_ 1719 KBI_Aussen_Temp_gef 254;
BA_ "GenSigSwitchedByIgnition" SG_ 1719 KBI_Aussen_Temp_gef 0;
BA_ "Fehlerwert" SG_ 1719 KBI_Aussen_Temp_gef 255;
BA_ "GenSigSendType" SG_ 1719 KBI_FoD_PopUP_Quittiert 3;
BA_ "GenSigSendType" SG_ 1719 KBI_FStatus_Tank 0;
BA_ "GenSigSwitchedByIgnition" SG_ 1719 KBI_FStatus_Tank 0;
BA_ "GenSigSendType" SG_ 1719 KBI_GRA_im_ACC 3;
BA_ "GenSigSwitchedByIgnition" SG_ 1719 KBI_GRA_im_ACC 0;
BA_ "GenSigSendType" SG_ 1719 KBI_Inhalt_Tank 0;
BA_ "GenSigStartValue" SG_ 1719 KBI_Inhalt_Tank 126;
BA_ "GenSigSwitchedByIgnition" SG_ 1719 KBI_Inhalt_Tank 0;
BA_ "Fehlerwert" SG_ 1719 KBI_Inhalt_Tank 127;
BA_ "GenSigSendType" SG_ 1719 KBI_Kilometerstand 0;
BA_ "GenSigStartValue" SG_ 1719 KBI_Kilometerstand 1048574;
BA_ "GenSigSwitchedByIgnition" SG_ 1719 KBI_Kilometerstand 0;
BA_ "Fehlerwert" SG_ 1719 KBI_Kilometerstand 1048575;
BA_ "GenSigSendType" SG_ 1719 KBI_LVDS_Lock 3;
BA_ "GenSigSwitchedByIgnition" SG_ 1719 KBI_LVDS_Lock 0;
BA_ "GenSigSendType" SG_ 1719 KBI_Oelwechsel_durchgefuehrt 0;
BA_ "GenSigSwitchedByIgnition" SG_ 1719 KBI_Oelwechsel_durchgefuehrt 0;
BA_ "GenSigSendType" SG_ 1719 KBI_QBit_Aussen_Temp_gef 0;
BA_ "GenSigStartValue" SG_ 1719 KBI_QBit_Aussen_Temp_gef 1;
BA_ "GenSigSwitchedByIgnition" SG_ 1719 KBI_QBit_Aussen_Temp_gef 0;
BA_ "GenSigSendType" SG_ 1719 KBI_RDK_Kalibrier_Anf 3;
BA_ "GenSigSwitchedByIgnition" SG_ 1719 KBI_RDK_Kalibrier_Anf 0;
BA_ "GenSigSendType" SG_ 1719 KBI_Reserve_Warnung_Sek 3;
BA_ "GenSigSwitchedByIgnition" SG_ 1719 KBI_Reserve_Warnung_Sek 0;
BA_ "GenSigSendType" SG_ 1719 KBI_Standzeit_02 0;
BA_ "GenSigStartValue" SG_ 1719 KBI_Standzeit_02 131070;
BA_ "GenSigSwitchedByIgnition" SG_ 1719 KBI_Standzeit_02 0;
BA_ "Fehlerwert" SG_ 1719 KBI_Standzeit_02 131071;
BA_ "GenSigSendType" SG_ 1719 KBI_TA_gewaehlt_Fahrer 0;
BA_ "GenSigSendType" SG_ 2527679639 KBI_Jokerkey 3;
BA_ "GenSigSwitchedByIgnition" SG_ 2527679639 KBI_Jokerkey 0;
BA_ "GenSigSendType" SG_ 2527679639 KBI_RS_Druck_uebernehmen 3;
BA_ "GenSigSwitchedByIgnition" SG_ 2527679639 KBI_RS_Druck_uebernehmen 0;
BA_ "GenSigSendType" SG_ 2527679639 KBI_RS_Druckauswahl_Aktiv 3;
BA_ "GenSigSwitchedByIgnition" SG_ 2527679639 KBI_RS_Druckauswahl_Aktiv 0;
BA_ "GenSigSendType" SG_ 2527679639 KBI_RS_Mode_fortsetzen 3;
BA_ "GenSigSwitchedByIgnition" SG_ 2527679639 KBI_RS_Mode_fortsetzen 0;
BA_ "GenSigSendType" SG_ 2527679639 KBI_Rundstreckenmodus 3;
BA_ "GenSigSwitchedByIgnition" SG_ 2527679639 KBI_Rundstreckenmodus 0;
BA_ "GenSigSendType" SG_ 2527679639 KBI_Weg_Zaehler 3;
BA_ "GenSigSwitchedByIgnition" SG_ 2527679639 KBI_Weg_Zaehler 0;
BA_ "GenSigSendType" SG_ 2527679639 KBI_Weg_Zaehler_F 3;
BA_ "GenSigSwitchedByIgnition" SG_ 2527679639 KBI_Weg_Zaehler_F 0;
BA_ "Fehlerwert" SG_ 2527679639 KBI_Weg_Zaehler_F 1;
BA_ "GenSigSendType" SG_ 1614 KBI_HUD_Data_01 3;
BA_ "GenSigSwitchedByIgnition" SG_ 1614 KBI_HUD_Data_01 0;
BA_ "GenSigSendType" SG_ 1614 KBI_HUD_Data_02 3;
BA_ "GenSigSwitchedByIgnition" SG_ 1614 KBI_HUD_Data_02 0;
BA_ "GenSigSendType" SG_ 1614 KBI_HUD_Data_03 3;
BA_ "GenSigSwitchedByIgnition" SG_ 1614 KBI_HUD_Data_03 0;
BA_ "GenSigSendType" SG_ 1614 KBI_HUD_Data_04 3;
BA_ "GenSigSwitchedByIgnition" SG_ 1614 KBI_HUD_Data_04 0;
BA_ "GenSigSendType" SG_ 1614 KBI_HUD_Data_05 3;
BA_ "GenSigSwitchedByIgnition" SG_ 1614 KBI_HUD_Data_05 0;
BA_ "GenSigSendType" SG_ 1614 KBI_HUD_Data_06 3;
BA_ "GenSigSwitchedByIgnition" SG_ 1614 KBI_HUD_Data_06 0;
BA_ "GenSigSendType" SG_ 1614 KBI_HUD_Data_07 3;
BA_ "GenSigSwitchedByIgnition" SG_ 1614 KBI_HUD_Data_07 0;
BA_ "GenSigSendType" SG_ 1614 KBI_HUD_Data_08 3;
BA_ "GenSigSwitchedByIgnition" SG_ 1614 KBI_HUD_Data_08 0;
BA_ "GenSigSendType" SG_ 2549874983 KS_Nightvision_Req_Data 3;
BA_ "GenSigFuncType" SG_ 2549874983 KS_Nightvision_Req_Data 9;
BA_ "GenSigSwitchedByIgnition" SG_ 2549874983 KS_Nightvision_Req_Data 0;
BA_ "GenSigSendType" SG_ 2550006055 KS_Nightvision_Resp_Data 3;
BA_ "GenSigFuncType" SG_ 2550006055 KS_Nightvision_Resp_Data 9;
BA_ "GenSigSendType" SG_ 2549875082 KS_SWA_2_Req_Data 3;
BA_ "GenSigFuncType" SG_ 2549875082 KS_SWA_2_Req_Data 9;
BA_ "GenSigSwitchedByIgnition" SG_ 2549875082 KS_SWA_2_Req_Data 0;
BA_ "GenSigSendType" SG_ 2550006154 KS_SWA_2_Resp_Data 3;
BA_ "GenSigFuncType" SG_ 2550006154 KS_SWA_2_Resp_Data 9;
BA_ "GenSigSwitchedByIgnition" SG_ 2550006154 KS_SWA_2_Resp_Data 0;
BA_ "GenSigSendType" SG_ 2549875022 KS_SWA_Req_Data 3;
BA_ "GenSigFuncType" SG_ 2549875022 KS_SWA_Req_Data 9;
BA_ "GenSigSwitchedByIgnition" SG_ 2549875022 KS_SWA_Req_Data 0;
BA_ "GenSigSendType" SG_ 2550006094 KS_SWA_Resp_Data 3;
BA_ "GenSigFuncType" SG_ 2550006094 KS_SWA_Resp_Data 9;
BA_ "GenSigSwitchedByIgnition" SG_ 2550006094 KS_SWA_Resp_Data 0;
BA_ "GenSigSendType" SG_ 160 EPS_04_BZ 0;
BA_ "GenSigFuncType" SG_ 160 EPS_04_BZ 1;
BA_ "GenSigSwitchedByIgnition" SG_ 160 EPS_04_BZ 0;
BA_ "GenSigSendType" SG_ 160 EPS_04_CRC 0;
BA_ "GenSigFuncType" SG_ 160 EPS_04_CRC 2;
BA_ "GenSigSwitchedByIgnition" SG_ 160 EPS_04_CRC 0;
BA_ "GenSigSendType" SG_ 160 EPS_AWA_Status 0;
BA_ "GenSigStartValue" SG_ 160 EPS_AWA_Status 14;
BA_ "GenSigSwitchedByIgnition" SG_ 160 EPS_AWA_Status 0;
BA_ "GenSigSendType" SG_ 160 EPS_FAS_Regelgroesse 0;
BA_ "GenSigStartValue" SG_ 160 EPS_FAS_Regelgroesse 62;
BA_ "GenSigSwitchedByIgnition" SG_ 160 EPS_FAS_Regelgroesse 0;
BA_ "Fehlerwert" SG_ 160 EPS_FAS_Regelgroesse 63;
BA_ "GenSigSendType" SG_ 160 EPS_FAS_VZ_Regelgroesse 0;
BA_ "GenSigSwitchedByIgnition" SG_ 160 EPS_FAS_VZ_Regelgroesse 0;
BA_ "GenSigSendType" SG_ 160 EPS_Lenkmoment_AbsReduz 0;
BA_ "GenSigStartValue" SG_ 160 EPS_Lenkmoment_AbsReduz 14;
BA_ "GenSigSwitchedByIgnition" SG_ 160 EPS_Lenkmoment_AbsReduz 0;
BA_ "Fehlerwert" SG_ 160 EPS_Lenkmoment_AbsReduz 15;
BA_ "GenSigSendType" SG_ 160 EPS_Motormoment 0;
BA_ "GenSigStartValue" SG_ 160 EPS_Motormoment 254;
BA_ "GenSigSwitchedByIgnition" SG_ 160 EPS_Motormoment 0;
BA_ "Fehlerwert" SG_ 160 EPS_Motormoment 255;
BA_ "GenSigSendType" SG_ 160 EPS_QBit_Zahnstangen_Pos 0;
BA_ "GenSigSwitchedByIgnition" SG_ 160 EPS_QBit_Zahnstangen_Pos 0;
BA_ "GenSigSendType" SG_ 160 EPS_STA_Status 0;
BA_ "GenSigStartValue" SG_ 160 EPS_STA_Status 14;
BA_ "GenSigSwitchedByIgnition" SG_ 160 EPS_STA_Status 0;
BA_ "GenSigSendType" SG_ 160 EPS_Versorgungsspannung 0;
BA_ "GenSigStartValue" SG_ 160 EPS_Versorgungsspannung 254;
BA_ "GenSigSwitchedByIgnition" SG_ 160 EPS_Versorgungsspannung 0;
BA_ "Fehlerwert" SG_ 160 EPS_Versorgungsspannung 255;
BA_ "GenSigSendType" SG_ 160 EPS_Versorgungsstatus 0;
BA_ "GenSigSwitchedByIgnition" SG_ 160 EPS_Versorgungsstatus 0;
BA_ "GenSigSendType" SG_ 160 EPS_VZ_Zahnstangenposition 0;
BA_ "GenSigSwitchedByIgnition" SG_ 160 EPS_VZ_Zahnstangenposition 0;
BA_ "GenSigSendType" SG_ 160 EPS_Zahnstangen_Pos 0;
BA_ "GenSigStartValue" SG_ 160 EPS_Zahnstangen_Pos 4094;
BA_ "GenSigSwitchedByIgnition" SG_ 160 EPS_Zahnstangen_Pos 0;
BA_ "Fehlerwert" SG_ 160 EPS_Zahnstangen_Pos 4095;
BA_ "GenSigSendType" SG_ 981 BCM1_Abblendlicht_Anf 0;
BA_ "GenSigSwitchedByIgnition" SG_ 981 BCM1_Abblendlicht_Anf 0;
BA_ "GenSigSendType" SG_ 981 BCM1_Adaptive_Lichtvert_Anf 0;
BA_ "GenSigSwitchedByIgnition" SG_ 981 BCM1_Adaptive_Lichtvert_Anf 0;
BA_ "GenSigSendType" SG_ 981 BCM1_Allwetterlicht_Anf 0;
BA_ "GenSigSwitchedByIgnition" SG_ 981 BCM1_Allwetterlicht_Anf 0;
BA_ "GenSigSendType" SG_ 981 BCM1_Animationssperrung 3;
BA_ "GenSigStartValue" SG_ 981 BCM1_Animationssperrung 1;
BA_ "GenSigSwitchedByIgnition" SG_ 981 BCM1_Animationssperrung 0;
BA_ "GenSigSendType" SG_ 981 BCM1_Autobahnlicht_Anf 0;
BA_ "GenSigSwitchedByIgnition" SG_ 981 BCM1_Autobahnlicht_Anf 0;
BA_ "GenSigSendType" SG_ 981 BCM1_CH_aktiv 0;
BA_ "NWM-WakeupAllowed" SG_ 981 BCM1_CH_aktiv 1;
BA_ "GenSigSwitchedByIgnition" SG_ 981 BCM1_CH_aktiv 0;
BA_ "GenSigSendType" SG_ 981 BCM1_CH_LH_aktiv 0;
BA_ "GenSigSwitchedByIgnition" SG_ 981 BCM1_CH_LH_aktiv 0;
BA_ "GenSigSendType" SG_ 981 BCM1_Fernlicht_Anf 0;
BA_ "GenSigSwitchedByIgnition" SG_ 981 BCM1_Fernlicht_Anf 0;
BA_ "GenSigSendType" SG_ 981 BCM1_FOD_Sperrung_Animationen_HL 3;
BA_ "GenSigStartValue" SG_ 981 BCM1_FOD_Sperrung_Animationen_HL 2;
BA_ "GenSigSendType" SG_ 981 BCM1_FoD_Sperrung_WiBli 3;
BA_ "GenSigStartValue" SG_ 981 BCM1_FoD_Sperrung_WiBli 2;
BA_ "GenSigSendType" SG_ 981 BCM1_Gleitende_Leuchtw_Anf 3;
BA_ "GenSigSwitchedByIgnition" SG_ 981 BCM1_Gleitende_Leuchtw_Anf 0;
BA_ "GenSigSendType" SG_ 981 BCM1_GLW_Fernlicht_Anf 3;
BA_ "GenSigSwitchedByIgnition" SG_ 981 BCM1_GLW_Fernlicht_Anf 0;
BA_ "GenSigSendType" SG_ 981 BCM1_Kurvenlicht_links_Anf 0;
BA_ "GenSigSwitchedByIgnition" SG_ 981 BCM1_Kurvenlicht_links_Anf 0;
BA_ "GenSigSendType" SG_ 981 BCM1_Kurvenlicht_rechts_Anf 0;
BA_ "GenSigSwitchedByIgnition" SG_ 981 BCM1_Kurvenlicht_rechts_Anf 0;
BA_ "GenSigSendType" SG_ 981 BCM1_LH_aktiv 0;
BA_ "NWM-WakeupAllowed" SG_ 981 BCM1_LH_aktiv 1;
BA_ "GenSigSwitchedByIgnition" SG_ 981 BCM1_LH_aktiv 0;
BA_ "GenSigSendType" SG_ 981 BCM1_Nebellicht_Anf 0;
BA_ "GenSigSwitchedByIgnition" SG_ 981 BCM1_Nebellicht_Anf 0;
BA_ "GenSigSendType" SG_ 981 BCM1_Nebelschluss_Ahg_Anf 0;
BA_ "GenSigSwitchedByIgnition" SG_ 981 BCM1_Nebelschluss_Ahg_Anf 0;
BA_ "GenSigSendType" SG_ 981 BCM1_Nebelschluss_Fzg_Anf 0;
BA_ "GenSigSwitchedByIgnition" SG_ 981 BCM1_Nebelschluss_Fzg_Anf 0;
BA_ "GenSigSendType" SG_ 981 BCM1_Parklicht_li_Anf 0;
BA_ "GenSigSwitchedByIgnition" SG_ 981 BCM1_Parklicht_li_Anf 0;
BA_ "GenSigSendType" SG_ 981 BCM1_Parklicht_re_Anf 0;
BA_ "GenSigSwitchedByIgnition" SG_ 981 BCM1_Parklicht_re_Anf 0;
BA_ "GenSigSendType" SG_ 981 BCM1_Regenlicht_Anf 0;
BA_ "GenSigSwitchedByIgnition" SG_ 981 BCM1_Regenlicht_Anf 0;
BA_ "GenSigSendType" SG_ 981 BCM1_Schlusslicht_Anf 0;
BA_ "GenSigSwitchedByIgnition" SG_ 981 BCM1_Schlusslicht_Anf 0;
BA_ "GenSigSendType" SG_ 981 BCM1_Schlusslicht_Signatur 0;
BA_ "GenSigSwitchedByIgnition" SG_ 981 BCM1_Schlusslicht_Signatur 0;
BA_ "GenSigSendType" SG_ 981 BCM1_Signaturlicht_Anf 0;
BA_ "GenSigSwitchedByIgnition" SG_ 981 BCM1_Signaturlicht_Anf 0;
BA_ "GenSigSendType" SG_ 981 BCM1_Standlicht_Anf 0;
BA_ "GenSigSwitchedByIgnition" SG_ 981 BCM1_Standlicht_Anf 0;
BA_ "GenSigSendType" SG_ 981 BCM1_Tagfahrlicht_Anf 0;
BA_ "GenSigSwitchedByIgnition" SG_ 981 BCM1_Tagfahrlicht_Anf 0;
BA_ "GenSigSendType" SG_ 981 BCM1_Touristen_Licht_Anf 0;
BA_ "GenSigSwitchedByIgnition" SG_ 981 BCM1_Touristen_Licht_Anf 0;
BA_ "GenSigSendType" SG_ 981 BCM1_Umfeldleuchten_Anf 0;
BA_ "GenSigSwitchedByIgnition" SG_ 981 BCM1_Umfeldleuchten_Anf 0;
BA_ "GenSigSendType" SG_ 981 BCM_Rueckfahrlicht_Anf 0;
BA_ "GenSigSwitchedByIgnition" SG_ 981 BCM_Rueckfahrlicht_Anf 0;
BA_ "GenSigSendType" SG_ 981 Licht_Anf_01_BZ 0;
BA_ "GenSigFuncType" SG_ 981 Licht_Anf_01_BZ 1;
BA_ "GenSigSwitchedByIgnition" SG_ 981 Licht_Anf_01_BZ 0;
BA_ "GenSigSendType" SG_ 981 Licht_Anf_01_CRC 0;
BA_ "GenSigFuncType" SG_ 981 Licht_Anf_01_CRC 2;
BA_ "GenSigSwitchedByIgnition" SG_ 981 Licht_Anf_01_CRC 0;
BA_ "GenSigSendType" SG_ 1624 BCM1_Licht_Dunkelheit_aktiv 3;
BA_ "GenSigSwitchedByIgnition" SG_ 1624 BCM1_Licht_Dunkelheit_aktiv 0;
BA_ "GenSigSendType" SG_ 1624 BCM1_Linksverkehr 0;
BA_ "GenSigSwitchedByIgnition" SG_ 1624 BCM1_Linksverkehr 0;
BA_ "GenSigSendType" SG_ 1624 Licht_Vorne_01_BZ 0;
BA_ "GenSigFuncType" SG_ 1624 Licht_Vorne_01_BZ 1;
BA_ "GenSigSendType" SG_ 1624 Licht_Vorne_01_CRC 0;
BA_ "GenSigFuncType" SG_ 1624 Licht_Vorne_01_CRC 2;
BA_ "GenSigSendType" SG_ 1624 LV_Abbiegelicht_li_def 0;
BA_ "GenSigSwitchedByIgnition" SG_ 1624 LV_Abbiegelicht_li_def 0;
BA_ "GenSigSendType" SG_ 1624 LV_Abbiegelicht_re_def 0;
BA_ "GenSigSwitchedByIgnition" SG_ 1624 LV_Abbiegelicht_re_def 0;
BA_ "GenSigSendType" SG_ 1624 LV_Abblend_Fernlicht_li_def 0;
BA_ "GenSigSwitchedByIgnition" SG_ 1624 LV_Abblend_Fernlicht_li_def 0;
BA_ "GenSigSendType" SG_ 1624 LV_Abblend_Fernlicht_re_def 0;
BA_ "GenSigSwitchedByIgnition" SG_ 1624 LV_Abblend_Fernlicht_re_def 0;
BA_ "GenSigSendType" SG_ 1624 LV_Abblendlicht_Anzeige 3;
BA_ "GenSigSwitchedByIgnition" SG_ 1624 LV_Abblendlicht_Anzeige 0;
BA_ "GenSigSendType" SG_ 1624 LV_Abblendlicht_li_def 0;
BA_ "GenSigSwitchedByIgnition" SG_ 1624 LV_Abblendlicht_li_def 0;
BA_ "GenSigSendType" SG_ 1624 LV_Abblendlicht_re_def 0;
BA_ "GenSigSwitchedByIgnition" SG_ 1624 LV_Abblendlicht_re_def 0;
BA_ "GenSigSendType" SG_ 1624 LV_Abblendlicht_TFL_li_def 0;
BA_ "GenSigSwitchedByIgnition" SG_ 1624 LV_Abblendlicht_TFL_li_def 0;
BA_ "GenSigSendType" SG_ 1624 LV_Abblendlicht_TFL_re_def 0;
BA_ "GenSigSwitchedByIgnition" SG_ 1624 LV_Abblendlicht_TFL_re_def 0;
BA_ "GenSigSendType" SG_ 1624 LV_AFL_aktiv_Anzeige 3;
BA_ "GenSigSwitchedByIgnition" SG_ 1624 LV_AFL_aktiv_Anzeige 0;
BA_ "GenSigSendType" SG_ 1624 LV_AFL_defekt 3;
BA_ "GenSigSwitchedByIgnition" SG_ 1624 LV_AFL_defekt 0;
BA_ "GenSigSendType" SG_ 1624 LV_Aussenlicht_def 3;
BA_ "GenSigSwitchedByIgnition" SG_ 1624 LV_Aussenlicht_def 0;
BA_ "GenSigSendType" SG_ 1624 LV_Blinker_li_def 3;
BA_ "GenSigSwitchedByIgnition" SG_ 1624 LV_Blinker_li_def 0;
BA_ "GenSigSendType" SG_ 1624 LV_Blinker_re_def 3;
BA_ "GenSigSwitchedByIgnition" SG_ 1624 LV_Blinker_re_def 0;
BA_ "GenSigSendType" SG_ 1624 LV_Blinker_VL_aktiv 3;
BA_ "GenSigSwitchedByIgnition" SG_ 1624 LV_Blinker_VL_aktiv 0;
BA_ "GenSigSendType" SG_ 1624 LV_Blinker_VR_aktiv 3;
BA_ "GenSigSwitchedByIgnition" SG_ 1624 LV_Blinker_VR_aktiv 0;
BA_ "GenSigSendType" SG_ 1624 LV_Blk_li_Seite_def 0;
BA_ "GenSigSwitchedByIgnition" SG_ 1624 LV_Blk_li_Seite_def 0;
BA_ "GenSigSendType" SG_ 1624 LV_Blk_re_Seite_def 0;
BA_ "GenSigSwitchedByIgnition" SG_ 1624 LV_Blk_re_Seite_def 0;
BA_ "GenSigSendType" SG_ 1624 LV_Fernlicht_Anzeige 3;
BA_ "GenSigSwitchedByIgnition" SG_ 1624 LV_Fernlicht_Anzeige 0;
BA_ "GenSigSendType" SG_ 1624 LV_Fernlicht_li_def 0;
BA_ "GenSigSwitchedByIgnition" SG_ 1624 LV_Fernlicht_li_def 0;
BA_ "GenSigSendType" SG_ 1624 LV_Fernlicht_re_def 0;
BA_ "GenSigSwitchedByIgnition" SG_ 1624 LV_Fernlicht_re_def 0;
BA_ "GenSigSendType" SG_ 1624 LV_FLA_aktiv_Anzeige 3;
BA_ "GenSigSwitchedByIgnition" SG_ 1624 LV_FLA_aktiv_Anzeige 0;
BA_ "GenSigSendType" SG_ 1624 LV_FLA_defekt 0;
BA_ "GenSigSwitchedByIgnition" SG_ 1624 LV_FLA_defekt 0;
BA_ "GenSigSendType" SG_ 1624 LV_FLA_Sensor_blockiert 0;
BA_ "GenSigSwitchedByIgnition" SG_ 1624 LV_FLA_Sensor_blockiert 0;
BA_ "GenSigSendType" SG_ 1624 LV_LED_Scheinwerfer_li_def 0;
BA_ "GenSigSwitchedByIgnition" SG_ 1624 LV_LED_Scheinwerfer_li_def 0;
BA_ "GenSigSendType" SG_ 1624 LV_LED_Scheinwerfer_re_def 0;
BA_ "GenSigSwitchedByIgnition" SG_ 1624 LV_LED_Scheinwerfer_re_def 0;
BA_ "GenSigSendType" SG_ 1624 LV_MXB_Status_Anzeige 3;
BA_ "GenSigSwitchedByIgnition" SG_ 1624 LV_MXB_Status_Anzeige 0;
BA_ "GenSigSendType" SG_ 1624 LV_Nebellicht_Anzeige 3;
BA_ "GenSigSwitchedByIgnition" SG_ 1624 LV_Nebellicht_Anzeige 0;
BA_ "GenSigSendType" SG_ 1624 LV_Nebellicht_li_def 0;
BA_ "GenSigSwitchedByIgnition" SG_ 1624 LV_Nebellicht_li_def 0;
BA_ "GenSigSendType" SG_ 1624 LV_Nebellicht_re_def 0;
BA_ "GenSigSwitchedByIgnition" SG_ 1624 LV_Nebellicht_re_def 0;
BA_ "GenSigSendType" SG_ 1624 LV_Nebellicht_TFL_li_def 0;
BA_ "GenSigSwitchedByIgnition" SG_ 1624 LV_Nebellicht_TFL_li_def 0;
BA_ "GenSigSendType" SG_ 1624 LV_Nebellicht_TFL_re_def 0;
BA_ "GenSigSwitchedByIgnition" SG_ 1624 LV_Nebellicht_TFL_re_def 0;
BA_ "GenSigSendType" SG_ 1624 LV_Nebelschlusslicht_Anzeige 3;
BA_ "GenSigSwitchedByIgnition" SG_ 1624 LV_Nebelschlusslicht_Anzeige 0;
BA_ "GenSigSendType" SG_ 1624 LV_Standlicht_Anzeige 3;
BA_ "GenSigSwitchedByIgnition" SG_ 1624 LV_Standlicht_Anzeige 0;
BA_ "GenSigSendType" SG_ 1624 LV_Standlicht_li_def 0;
BA_ "GenSigSwitchedByIgnition" SG_ 1624 LV_Standlicht_li_def 0;
BA_ "GenSigSendType" SG_ 1624 LV_Standlicht_re_def 0;
BA_ "GenSigSwitchedByIgnition" SG_ 1624 LV_Standlicht_re_def 0;
BA_ "GenSigSendType" SG_ 1624 LV_Standlicht_TFL_li_def 0;
BA_ "GenSigSwitchedByIgnition" SG_ 1624 LV_Standlicht_TFL_li_def 0;
BA_ "GenSigSendType" SG_ 1624 LV_Standlicht_TFL_re_def 0;
BA_ "GenSigSwitchedByIgnition" SG_ 1624 LV_Standlicht_TFL_re_def 0;
BA_ "GenSigSendType" SG_ 1624 LV_Tagfahrlicht_Anzeige 3;
BA_ "GenSigSwitchedByIgnition" SG_ 1624 LV_Tagfahrlicht_Anzeige 0;
BA_ "GenSigSendType" SG_ 1624 LV_Tagfahrlicht_li_def 0;
BA_ "GenSigSwitchedByIgnition" SG_ 1624 LV_Tagfahrlicht_li_def 0;
BA_ "GenSigSendType" SG_ 1624 LV_Tagfahrlicht_re_def 0;
BA_ "GenSigSwitchedByIgnition" SG_ 1624 LV_Tagfahrlicht_re_def 0;
BA_ "GenSigSendType" SG_ 134 LWI_01_BZ 0;
BA_ "GenSigFuncType" SG_ 134 LWI_01_BZ 1;
BA_ "GenSigSendType" SG_ 134 LWI_01_CRC 0;
BA_ "GenSigFuncType" SG_ 134 LWI_01_CRC 2;
BA_ "GenSigSwitchedByIgnition" SG_ 134 LWI_01_CRC 0;
BA_ "GenSigSendType" SG_ 134 LWI_Lenkradw_Geschw 0;
BA_ "GenSigStartValue" SG_ 134 LWI_Lenkradw_Geschw 510;
BA_ "Fehlerwert" SG_ 134 LWI_Lenkradw_Geschw 511;
BA_ "GenSigSendType" SG_ 134 LWI_Lenkradwinkel 0;
BA_ "GenSigStartValue" SG_ 134 LWI_Lenkradwinkel 8190;
BA_ "Fehlerwert" SG_ 134 LWI_Lenkradwinkel 8191;
BA_ "GenSigSendType" SG_ 134 LWI_MFL_Abschaltung 0;
BA_ "GenSigSwitchedByIgnition" SG_ 134 LWI_MFL_Abschaltung 0;
BA_ "GenSigSendType" SG_ 134 LWI_QBit_Lenkradwinkel 0;
BA_ "GenSigStartValue" SG_ 134 LWI_QBit_Lenkradwinkel 1;
BA_ "GenSigSendType" SG_ 134 LWI_QBit_Sub_Daten 0;
BA_ "GenSigSendType" SG_ 134 LWI_Sensorstatus 0;
BA_ "GenSigSendType" SG_ 134 LWI_Sub_Daten 0;
BA_ "GenSigSendType" SG_ 134 LWI_VZ_Lenkradw_Geschw 0;
BA_ "GenSigSendType" SG_ 134 LWI_VZ_Lenkradwinkel 0;
BA_REL_ "GenSigTimeoutTime" BU_SG_REL_ AEM SG_ 1719 KBI_Aussen_Temp_gef 5000;
BA_REL_ "GenSigTimeoutTime" BU_SG_REL_ FBK SG_ 134 LWI_QBit_Lenkradwinkel 500;
BA_REL_ "GenSigTimeoutTime" BU_SG_REL_ FBK SG_ 134 LWI_Lenkradwinkel 500;
BA_REL_ "GenSigTimeoutTime" BU_SG_REL_ FBK SG_ 134 LWI_VZ_Lenkradwinkel 500;
BA_REL_ "GenSigTimeoutTime" BU_SG_REL_ FLA SG_ 1624 LV_Abblendlicht_Anzeige 5000;
BA_REL_ "GenSigTimeoutTime" BU_SG_REL_ FLA SG_ 1624 LV_Fernlicht_Anzeige 5000;
BA_REL_ "GenSigTimeoutTime" BU_SG_REL_ FLA SG_ 1624 LV_Nebellicht_Anzeige 5000;
BA_REL_ "GenSigTimeoutTime" BU_SG_REL_ Gateway SG_ 2549088302 AEM_Nachlauftyp 5000;
BA_REL_ "GenSigTimeoutTime" BU_SG_REL_ Gateway SG_ 2549088302 AEM_SNI 5000;
BA_REL_ "GenSigTimeoutTime" BU_SG_REL_ Gateway SG_ 2549088302 AEM_Lokalaktiv 5000;
BA_REL_ "GenSigTimeoutTime" BU_SG_REL_ Gateway SG_ 2549088302 AEM_KD_Fehler 2500;
BA_REL_ "GenSigTimeoutTime" BU_SG_REL_ Gateway SG_ 2549088356 AGA_Nachlauftyp 5000;
BA_REL_ "GenSigTimeoutTime" BU_SG_REL_ Gateway SG_ 2549088356 AGA_SNI 5000;
BA_REL_ "GenSigTimeoutTime" BU_SG_REL_ Gateway SG_ 2549088356 AGA_KD_Fehler 2500;
BA_REL_ "GenSigTimeoutTime" BU_SG_REL_ Gateway SG_ 2549088304 FLA_Nachlauftyp 5000;
BA_REL_ "GenSigTimeoutTime" BU_SG_REL_ Gateway SG_ 2549088304 FLA_SNI 5000;
BA_REL_ "GenSigTimeoutTime" BU_SG_REL_ Gateway SG_ 2549088304 FLA_KD_Fehler 2500;
BA_REL_ "GenSigTimeoutTime" BU_SG_REL_ Gateway SG_ 2549088295 Nightvision_Nachlauftyp 5000;
BA_REL_ "GenSigTimeoutTime" BU_SG_REL_ Gateway SG_ 2549088295 Nightvision_SNI 5000;
BA_REL_ "GenSigTimeoutTime" BU_SG_REL_ Gateway SG_ 2549088295 Nightvision_KD_Fehler 2500;
BA_REL_ "GenSigTimeoutTime" BU_SG_REL_ Gateway SG_ 2549088267 RDK_Nachlauftyp 5000;
BA_REL_ "GenSigTimeoutTime" BU_SG_REL_ Gateway SG_ 2549088267 RDK_SNI 5000;
BA_REL_ "GenSigTimeoutTime" BU_SG_REL_ Gateway SG_ 2549088267 KN_RDK_BusKnockOutTimer 5000;
BA_REL_ "GenSigTimeoutTime" BU_SG_REL_ Gateway SG_ 2549088267 NM_RDK_Lokalaktiv 5000;
BA_REL_ "GenSigTimeoutTime" BU_SG_REL_ Gateway SG_ 2549088267 RDK_KD_Fehler 2500;
BA_REL_ "GenSigTimeoutTime" BU_SG_REL_ Gateway SG_ 2549088361 Rearview_Nachlauftyp 5000;
BA_REL_ "GenSigTimeoutTime" BU_SG_REL_ Gateway SG_ 2549088361 Rearview_SNI 5000;
BA_REL_ "GenSigTimeoutTime" BU_SG_REL_ Gateway SG_ 2549088361 KN_Rearview_BusKnockOutTimer 5000;
BA_REL_ "GenSigTimeoutTime" BU_SG_REL_ Gateway SG_ 2549088361 Rearview_Lokalaktiv 5000;
BA_REL_ "GenSigTimeoutTime" BU_SG_REL_ Gateway SG_ 2549088361 RV_KD_Fehler 2500;
BA_REL_ "GenSigTimeoutTime" BU_SG_REL_ Gateway SG_ 2549088284 SAK_Nachlauftyp 5000;
BA_REL_ "GenSigTimeoutTime" BU_SG_REL_ Gateway SG_ 2549088284 SAK_SNI 5000;
BA_REL_ "GenSigTimeoutTime" BU_SG_REL_ Gateway SG_ 2549088284 SAK_KD_Fehler 2500;
BA_REL_ "GenSigTimeoutTime" BU_SG_REL_ Gateway SG_ 2549088298 SCR_Nachlauftyp 5000;
BA_REL_ "GenSigTimeoutTime" BU_SG_REL_ Gateway SG_ 2549088298 SCR_SNI 5000;
BA_REL_ "GenSigTimeoutTime" BU_SG_REL_ Gateway SG_ 2549088298 KN_SCR_BusKnockOutTimer 5000;
BA_REL_ "GenSigTimeoutTime" BU_SG_REL_ Gateway SG_ 2549088298 NMH_SCR_Lokalaktiv 5000;
BA_REL_ "GenSigTimeoutTime" BU_SG_REL_ Gateway SG_ 2549088298 SCR_KD_Fehler 2500;
BA_REL_ "GenSigTimeoutTime" BU_SG_REL_ Gateway SG_ 2549088362 STH_Nachlauftyp 5000;
BA_REL_ "GenSigTimeoutTime" BU_SG_REL_ Gateway SG_ 2549088362 STH_SNI 5000;
BA_REL_ "GenSigTimeoutTime" BU_SG_REL_ Gateway SG_ 2549088362 KN_STH_BusKnockOutTimer 5000;
BA_REL_ "GenSigTimeoutTime" BU_SG_REL_ Gateway SG_ 2549088362 NMH_STH_Lokalaktiv 5000;
BA_REL_ "GenSigTimeoutTime" BU_SG_REL_ Gateway SG_ 2549088362 NMH_STH_Subsystemaktiv 5000;
BA_REL_ "GenSigTimeoutTime" BU_SG_REL_ Gateway SG_ 2549088362 STH_KD_Fehler 2500;
BA_REL_ "GenSigTimeoutTime" BU_SG_REL_ Gateway SG_ 2549088394 SWA_2_Nachlauftyp 5000;
BA_REL_ "GenSigTimeoutTime" BU_SG_REL_ Gateway SG_ 2549088394 SWA_2_SNI 5000;
BA_REL_ "GenSigTimeoutTime" BU_SG_REL_ Gateway SG_ 2549088394 KN_SWA_Slave_BusKnockOutTimer 5000;
BA_REL_ "GenSigTimeoutTime" BU_SG_REL_ Gateway SG_ 2549088394 SWA_2_Lokalaktiv 5000;
BA_REL_ "GenSigTimeoutTime" BU_SG_REL_ Gateway SG_ 2549088394 SWA_2_KD_Fehler 2500;
BA_REL_ "GenSigTimeoutTime" BU_SG_REL_ Gateway SG_ 2549088334 SWA_Nachlauftyp 5000;
BA_REL_ "GenSigTimeoutTime" BU_SG_REL_ Gateway SG_ 2549088334 SWA_SNI 5000;
BA_REL_ "GenSigTimeoutTime" BU_SG_REL_ Gateway SG_ 2549088334 KN_SWA_BusKnockOutTimer 5000;
BA_REL_ "GenSigTimeoutTime" BU_SG_REL_ Gateway SG_ 2549088334 SWA_Lokalaktiv 5000;
BA_REL_ "GenSigTimeoutTime" BU_SG_REL_ Gateway SG_ 2549088334 SWA_KD_Fehler 2500;
BA_REL_ "GenSigTimeoutTime" BU_SG_REL_ Gateway_PAG SG_ 2549088302 AEM_Nachlauftyp 5000;
BA_REL_ "GenSigTimeoutTime" BU_SG_REL_ Gateway_PAG SG_ 2549088302 AEM_SNI 5000;
BA_REL_ "GenSigTimeoutTime" BU_SG_REL_ Gateway_PAG SG_ 2549088302 AEM_Lokalaktiv 5000;
BA_REL_ "GenSigTimeoutTime" BU_SG_REL_ Gateway_PAG SG_ 2549088302 AEM_KD_Fehler 2500;
BA_REL_ "GenSigTimeoutTime" BU_SG_REL_ Gateway_PAG SG_ 2549088356 AGA_Nachlauftyp 5000;
BA_REL_ "GenSigTimeoutTime" BU_SG_REL_ Gateway_PAG SG_ 2549088356 AGA_SNI 5000;
BA_REL_ "GenSigTimeoutTime" BU_SG_REL_ Gateway_PAG SG_ 2549088356 AGA_KD_Fehler 2500;
BA_REL_ "GenSigTimeoutTime" BU_SG_REL_ Gateway_PAG SG_ 2549088304 FLA_Nachlauftyp 5000;
BA_REL_ "GenSigTimeoutTime" BU_SG_REL_ Gateway_PAG SG_ 2549088304 FLA_SNI 5000;
BA_REL_ "GenSigTimeoutTime" BU_SG_REL_ Gateway_PAG SG_ 2549088304 FLA_KD_Fehler 2500;
BA_REL_ "GenSigTimeoutTime" BU_SG_REL_ Gateway_PAG SG_ 2549088295 Nightvision_Nachlauftyp 5000;
BA_REL_ "GenSigTimeoutTime" BU_SG_REL_ Gateway_PAG SG_ 2549088295 Nightvision_SNI 5000;
BA_REL_ "GenSigTimeoutTime" BU_SG_REL_ Gateway_PAG SG_ 2549088295 Nightvision_KD_Fehler 2500;
BA_REL_ "GenSigTimeoutTime" BU_SG_REL_ Gateway_PAG SG_ 2549088267 RDK_Nachlauftyp 5000;
BA_REL_ "GenSigTimeoutTime" BU_SG_REL_ Gateway_PAG SG_ 2549088267 RDK_SNI 5000;
BA_REL_ "GenSigTimeoutTime" BU_SG_REL_ Gateway_PAG SG_ 2549088267 KN_RDK_BusKnockOutTimer 5000;
BA_REL_ "GenSigTimeoutTime" BU_SG_REL_ Gateway_PAG SG_ 2549088267 NM_RDK_Lokalaktiv 5000;
BA_REL_ "GenSigTimeoutTime" BU_SG_REL_ Gateway_PAG SG_ 2549088267 RDK_KD_Fehler 2500;
BA_REL_ "GenSigTimeoutTime" BU_SG_REL_ Gateway_PAG SG_ 2549088361 Rearview_Nachlauftyp 5000;
BA_REL_ "GenSigTimeoutTime" BU_SG_REL_ Gateway_PAG SG_ 2549088361 Rearview_SNI 5000;
BA_REL_ "GenSigTimeoutTime" BU_SG_REL_ Gateway_PAG SG_ 2549088361 KN_Rearview_BusKnockOutTimer 5000;
BA_REL_ "GenSigTimeoutTime" BU_SG_REL_ Gateway_PAG SG_ 2549088361 Rearview_Lokalaktiv 5000;
BA_REL_ "GenSigTimeoutTime" BU_SG_REL_ Gateway_PAG SG_ 2549088361 RV_KD_Fehler 2500;
BA_REL_ "GenSigTimeoutTime" BU_SG_REL_ Gateway_PAG SG_ 2549088284 SAK_Nachlauftyp 5000;
BA_REL_ "GenSigTimeoutTime" BU_SG_REL_ Gateway_PAG SG_ 2549088284 SAK_SNI 5000;
BA_REL_ "GenSigTimeoutTime" BU_SG_REL_ Gateway_PAG SG_ 2549088284 SAK_KD_Fehler 2500;
BA_REL_ "GenSigTimeoutTime" BU_SG_REL_ Gateway_PAG SG_ 2549088298 SCR_Nachlauftyp 5000;
BA_REL_ "GenSigTimeoutTime" BU_SG_REL_ Gateway_PAG SG_ 2549088298 SCR_SNI 5000;
BA_REL_ "GenSigTimeoutTime" BU_SG_REL_ Gateway_PAG SG_ 2549088298 KN_SCR_BusKnockOutTimer 5000;
BA_REL_ "GenSigTimeoutTime" BU_SG_REL_ Gateway_PAG SG_ 2549088298 NMH_SCR_Lokalaktiv 5000;
BA_REL_ "GenSigTimeoutTime" BU_SG_REL_ Gateway_PAG SG_ 2549088298 SCR_KD_Fehler 2500;
BA_REL_ "GenSigTimeoutTime" BU_SG_REL_ Gateway_PAG SG_ 2549088362 STH_Nachlauftyp 5000;
BA_REL_ "GenSigTimeoutTime" BU_SG_REL_ Gateway_PAG SG_ 2549088362 STH_SNI 5000;
BA_REL_ "GenSigTimeoutTime" BU_SG_REL_ Gateway_PAG SG_ 2549088362 KN_STH_BusKnockOutTimer 5000;
BA_REL_ "GenSigTimeoutTime" BU_SG_REL_ Gateway_PAG SG_ 2549088362 NMH_STH_Lokalaktiv 5000;
BA_REL_ "GenSigTimeoutTime" BU_SG_REL_ Gateway_PAG SG_ 2549088362 NMH_STH_Subsystemaktiv 5000;
BA_REL_ "GenSigTimeoutTime" BU_SG_REL_ Gateway_PAG SG_ 2549088362 STH_KD_Fehler 2500;
BA_REL_ "GenSigTimeoutTime" BU_SG_REL_ Gateway_PAG SG_ 2549088394 SWA_2_Nachlauftyp 5000;
BA_REL_ "GenSigTimeoutTime" BU_SG_REL_ Gateway_PAG SG_ 2549088394 SWA_2_SNI 5000;
BA_REL_ "GenSigTimeoutTime" BU_SG_REL_ Gateway_PAG SG_ 2549088394 KN_SWA_Slave_BusKnockOutTimer 5000;
BA_REL_ "GenSigTimeoutTime" BU_SG_REL_ Gateway_PAG SG_ 2549088394 SWA_2_Lokalaktiv 5000;
BA_REL_ "GenSigTimeoutTime" BU_SG_REL_ Gateway_PAG SG_ 2549088394 SWA_2_KD_Fehler 2500;
BA_REL_ "GenSigTimeoutTime" BU_SG_REL_ Gateway_PAG SG_ 2549088334 SWA_Nachlauftyp 5000;
BA_REL_ "GenSigTimeoutTime" BU_SG_REL_ Gateway_PAG SG_ 2549088334 SWA_SNI 5000;
BA_REL_ "GenSigTimeoutTime" BU_SG_REL_ Gateway_PAG SG_ 2549088334 KN_SWA_BusKnockOutTimer 5000;
BA_REL_ "GenSigTimeoutTime" BU_SG_REL_ Gateway_PAG SG_ 2549088334 SWA_Lokalaktiv 5000;
BA_REL_ "GenSigTimeoutTime" BU_SG_REL_ Gateway_PAG SG_ 2549088334 SWA_KD_Fehler 2500;
BA_REL_ "GenSigTimeoutTime" BU_SG_REL_ NightVision SG_ 779 KBI_NV_in_Anzeige 500;
BA_REL_ "GenSigTimeoutTime" BU_SG_REL_ NightVision SG_ 779 KBI_Anzeigefehler_NV 500;
BA_REL_ "GenSigTimeoutTime" BU_SG_REL_ NightVision SG_ 1719 KBI_QBit_Aussen_Temp_gef 5000;
BA_REL_ "GenSigTimeoutTime" BU_SG_REL_ NightVision SG_ 1719 KBI_Aussen_Temp_gef 5000;
BA_REL_ "GenSigTimeoutTime" BU_SG_REL_ NightVision SG_ 1614 KBI_HUD_Data_01 5000;
BA_REL_ "GenSigTimeoutTime" BU_SG_REL_ NightVision SG_ 1614 KBI_HUD_Data_02 5000;
BA_REL_ "GenSigTimeoutTime" BU_SG_REL_ NightVision SG_ 1614 KBI_HUD_Data_03 5000;
BA_REL_ "GenSigTimeoutTime" BU_SG_REL_ NightVision SG_ 1614 KBI_HUD_Data_04 5000;
BA_REL_ "GenSigTimeoutTime" BU_SG_REL_ NightVision SG_ 1614 KBI_HUD_Data_05 5000;
BA_REL_ "GenSigTimeoutTime" BU_SG_REL_ NightVision SG_ 1614 KBI_HUD_Data_06 5000;
BA_REL_ "GenSigTimeoutTime" BU_SG_REL_ NightVision SG_ 1614 KBI_HUD_Data_07 5000;
BA_REL_ "GenSigTimeoutTime" BU_SG_REL_ NightVision SG_ 1614 KBI_HUD_Data_08 5000;
BA_REL_ "GenSigTimeoutTime" BU_SG_REL_ NightVision SG_ 1624 LV_Abblendlicht_Anzeige 5000;
BA_REL_ "GenSigTimeoutTime" BU_SG_REL_ NightVision SG_ 1624 LV_Abblendlicht_li_def 5000;
BA_REL_ "GenSigTimeoutTime" BU_SG_REL_ NightVision SG_ 1624 LV_Abblendlicht_re_def 5000;
BA_REL_ "GenSigTimeoutTime" BU_SG_REL_ NightVision SG_ 1624 BCM1_Licht_Dunkelheit_aktiv 5000;
BA_REL_ "GenSigTimeoutTime" BU_SG_REL_ RDK SG_ 779 KBI_MFA_v_Einheit_01 500;
BA_REL_ "GenSigTimeoutTime" BU_SG_REL_ RDK SG_ 779 KBI_V_Digital 500;
BA_REL_ "GenSigTimeoutTime" BU_SG_REL_ RDK SG_ 1719 KBI_RDK_Kalibrier_Anf 5000;
BA_REL_ "GenSigTimeoutTime" BU_SG_REL_ RDK SG_ 1719 KBI_QBit_Aussen_Temp_gef 5000;
BA_REL_ "GenSigTimeoutTime" BU_SG_REL_ RDK SG_ 1719 KBI_Aussen_Temp_gef 5000;
BA_REL_ "GenSigTimeoutTime" BU_SG_REL_ RDK SG_ 2527679639 KBI_RS_Druck_uebernehmen 5000;
BA_REL_ "GenSigTimeoutTime" BU_SG_REL_ RDK SG_ 2527679639 KBI_RS_Druckauswahl_Aktiv 5000;
BA_REL_ "GenSigTimeoutTime" BU_SG_REL_ RDK SG_ 2527679639 KBI_RS_Mode_fortsetzen 5000;
BA_REL_ "GenSigTimeoutTime" BU_SG_REL_ RDK SG_ 2527679639 KBI_Rundstreckenmodus 5000;
BA_REL_ "GenSigTimeoutTime" BU_SG_REL_ SAK2 SG_ 1719 KBI_Aussen_Temp_gef 5000;
BA_REL_ "GenSigTimeoutTime" BU_SG_REL_ SCR SG_ 1719 KBI_Aussen_Temp_gef 5000;
BA_REL_ "GenSigTimeoutTime" BU_SG_REL_ STH_MLBevo SG_ 1646 KL_STL_aktiv 5000;
BA_REL_ "GenSigTimeoutTime" BU_SG_REL_ STH_MLBevo SG_ 1646 KL_STH_aktiv 5000;
BA_REL_ "GenSigTimeoutTime" BU_SG_REL_ STH_MLBevo SG_ 1646 KL_STH_Ansteuerung 5000;
BA_REL_ "GenSigTimeoutTime" BU_SG_REL_ STH_MLBevo SG_ 1646 KL_STH_Betriebsdauer 5000;
BA_REL_ "GenSigTimeoutTime" BU_SG_REL_ STH_MLBevo SG_ 1646 KL_Restwaerme_aktiv 5000;
BA_REL_ "GenSigTimeoutTime" BU_SG_REL_ STH_MLBevo SG_ 1649 KL_ZZ_Minute 5000;
BA_REL_ "GenSigTimeoutTime" BU_SG_REL_ STH_MLBevo SG_ 1649 KL_ZZ_Status_Timer 5000;
BA_REL_ "GenSigTimeoutTime" BU_SG_REL_ STH_MLBevo SG_ 1649 KL_ZZ_Monat 5000;
BA_REL_ "GenSigTimeoutTime" BU_SG_REL_ STH_MLBevo SG_ 1649 KL_ZZ_Stunde 5000;
BA_REL_ "GenSigTimeoutTime" BU_SG_REL_ STH_MLBevo SG_ 1649 KL_ZZ_Betriebsmodus 5000;
BA_REL_ "GenSigTimeoutTime" BU_SG_REL_ STH_MLBevo SG_ 1649 KL_ZZ_Tag 5000;
BA_REL_ "GenSigTimeoutTime" BU_SG_REL_ STH_MLBevo SG_ 949 KL_Thermomanagement 1000;
BA_REL_ "GenSigTimeoutTime" BU_SG_REL_ STH_MLBevo SG_ 1640 KL_Zuheizer_Freigabe 2000;
BA_REL_ "GenSigTimeoutTime" BU_SG_REL_ STH_MLBevo SG_ 1505 BCM1_Aussen_Temp_ungef 2000;
BA_REL_ "GenSigTimeoutTime" BU_SG_REL_ STH_MLBevo SG_ 779 KBI_Tankwarnung 500;
BA_REL_ "GenSigTimeoutTime" BU_SG_REL_ STH_MLBevo SG_ 1719 KBI_Standzeit_02 5000;
BA_REL_ "GenSigTimeoutTime" BU_SG_REL_ STH_MLBevo SG_ 1719 KBI_Inhalt_Tank 5000;
BA_REL_ "GenSigTimeoutTime" BU_SG_REL_ STH_MLBevo SG_ 1719 KBI_FStatus_Tank 5000;
BA_REL_ "GenSigTimeoutTime" BU_SG_REL_ STH_MLBevo SG_ 1719 KBI_QBit_Aussen_Temp_gef 5000;
BA_REL_ "GenSigTimeoutTime" BU_SG_REL_ STH_MLBevo SG_ 1719 KBI_Aussen_Temp_gef 5000;
BA_REL_ "GenSigTimeoutTime" BU_SG_REL_ TopView SG_ 1505 BCM1_Aussen_Temp_ungef 2000;
BA_REL_ "GenSigTimeoutTime" BU_SG_REL_ TopView SG_ 779 KBI_ESP_Lampe 500;
BA_REL_ "GenSigTimeoutTime" BU_SG_REL_ TopView SG_ 160 EPS_Lenkmoment_AbsReduz 500;
BA_REL_ "GenSigTimeoutTime" BU_SG_REL_ TopView SG_ 160 EPS_Zahnstangen_Pos 500;
BA_REL_ "GenSigTimeoutTime" BU_SG_REL_ TopView SG_ 160 EPS_VZ_Zahnstangenposition 500;
BA_REL_ "GenSigTimeoutTime" BU_SG_REL_ TopView SG_ 160 EPS_QBit_Zahnstangen_Pos 500;
BA_REL_ "GenSigTimeoutTime" BU_SG_REL_ TopView SG_ 981 BCM_Rueckfahrlicht_Anf 1000;
VAL_ 1646 KL_STL_aktiv 0 "Standlueftung_nicht_aktiv" 1 "Standlueftung_aktiv" ;
VAL_ 1646 KL_STH_aktiv 0 "Standheizung_nicht_aktiv" 1 "Standheizung_aktiv" ;
VAL_ 1646 KL_Solarluefter_aktiv 0 "Solarluefter_nicht_aktiv" 1 "Solarluefter_aktiv__auto" ;
VAL_ 1646 KL_Umluft_Taste 0 "Taste_nicht_gedrueckt" 1 "Taste_gedrueckt" ;
VAL_ 1646 KL_Geblaese_Fond_Status 0 "Geblaese_aus" 1 "Geblaesestufe_10" 2 "Geblaesestufe_20" 3 "Geblaesestufe_30" 4 "Geblaesestufe_40" 5 "Geblaesestufe_50" 6 "Geblaesestufe_60" 7 "Geblaesestufe_70" 8 "Geblaesestufe_80" 9 "Geblaesestufe_90" 10 "Geblaesestufe_100" 14 "Init" 15 "Fehler" ;
VAL_ 1646 KL_STH_Ansteuerung 0 "Aus" 1 "Ein" 2 "Ein_mit_Motorvorwaermung" 3 "Heizleistung_reduziert" ;
VAL_ 1646 KL_Magnetventil 0 "Aus" 1 "Ein" ;
VAL_ 1646 KL_WaPu 0 "Wasserpumpe_aus" 1 "Wasserpumpe_aktiv" ;
VAL_ 1646 KL_Geblaese_Status 0 "Geblaese_aus" 1 "Geblaesestufe_10" 2 "Geblaesestufe_20" 3 "Geblaesestufe_30" 4 "Geblaesestufe_40" 5 "Geblaesestufe_50" 6 "Geblaesestufe_60" 7 "Geblaesestufe_70" 8 "Geblaesestufe_80" 9 "Geblaesestufe_90" 10 "Geblaesestufe_100" 14 "Init" 15 "Fehler" ;
VAL_ 1646 KL_Restwaerme_aktiv 0 "inaktiv" 1 "aktiv" ;
VAL_ 1646 KL_Kompressorkupplung 0 "oeffnen" 1 "schliessen" ;
VAL_ 1646 KL_BCmE_Livetip_Freigabe 0 "Anzeige_Livetip_nicht_zulaessig" 1 "Anzeige_Livetip_zulaessig" ;
VAL_ 1646 KL_HYB_ASV_hinten_schliessen_Anf 0 "keine_Anforderung" 1 "Ventil_schliessen" ;
VAL_ 1646 KL_HYB_ASV_vorne_schliessen_Anf 0 "keine_Anforderung" 1 "Ventil_schliessen" ;
VAL_ 1646 KL_ErwVK_Zusatzrelais 0 "nicht_angefordert" 1 "angefordert" ;
VAL_ 1646 KL_Status_Beduftung 0 "inaktiv" 1 "aktiv" ;
VAL_ 1646 KL_Status_Ionisator_Front 0 "inaktiv" 1 "aktiv" ;
VAL_ 1646 KL_STH_Timer_Status 0 "TimerInaktiv" 1 "TimerAktiv" ;
VAL_ 1646 KL_ErwVK_Anf 0 "nicht_angefordert" 1 "angefordert" ;
VAL_ 1646 KL_Innen_Temp 253 "nicht_verbaut" 254 "nicht_verfuegbar" 255 "Fehler" ;
VAL_ 1646 KL_I_Geblaese_Fond 255 "Fehler" ;
VAL_ 1646 KL_Anf_AussenspiegelHzg 0 "nicht_angefordert" 1 "angefordert" ;
VAL_ 1646 KL_Heizkreisventilstellung 0 "Init" 1 "Ventilstellung_gem_Anforderung" 2 "Ventilstellung_abweichend_Anf" 3 "Fehler" ;
VAL_ 1646 KL_FSH_Automatikbetrieb 0 "aus" 1 "angefordert_durch_Regelung" ;
VAL_ 1646 KL_SIH_LEH_Verteilung_VL 0 "gleichmaessige_Verteilung" 1 "Sitz_Prio_Hoch" 2 "Sitz_Prio_Mittel" 3 "Sitz_Prio_Niedrig" 4 "Lehne_Prio_Niedrig" 5 "Lehne_Prio_Mittel" 6 "Lehne_Prio_Hoch" ;
VAL_ 1646 KL_SIH_LEL_Verteilung_VL 0 "gleichmaessige_Verteilung" 1 "Sitz_Prio_Hoch" 2 "Sitz_Prio_Mittel" 3 "Sitz_Prio_Niedrig" 4 "Lehne_Prio_Niedrig" 5 "Lehne_Prio_Mittel" 6 "Lehne_Prio_Hoch" ;
VAL_ 1646 KL_SIH_LEH_Verteilung_VR 0 "gleichmaessige_Verteilung" 1 "Sitz_Prio_Hoch" 2 "Sitz_Prio_Mittel" 3 "Sitz_Prio_Niedrig" 4 "Lehne_Prio_Niedrig" 5 "Lehne_Prio_Mittel" 6 "Lehne_Prio_Hoch" ;
VAL_ 1646 KL_SIH_LEL_Verteilung_VR 0 "gleichmaessige_Verteilung" 1 "Sitz_Prio_Hoch" 2 "Sitz_Prio_Mittel" 3 "Sitz_Prio_Niedrig" 4 "Lehne_Prio_Niedrig" 5 "Lehne_Prio_Mittel" 6 "Lehne_Prio_Hoch" ;
VAL_ 1649 KL_ZZ_Status_Timer 0 "Timer_n_aktiv_bzw_loeschen" 1 "Timer_aktiv_bzw_aktivieren" ;
VAL_ 1649 KL_ZZ_Monat 0 "Init" ;
VAL_ 1649 KL_ZZ_Betriebsmodus 0 "Do_not_Care" 1 "ECO" 2 "Standard" 3 "Standard_plus" 4 "Comfort" ;
VAL_ 1649 KL_ZZ_Tag 0 "Init" ;
VAL_ 1649 KL_Betriebsmodus_FH 0 "undefined__init" 1 "Klemme15" 2 "Standheizung" 3 "Restwaerme" 4 "Nachlauf" 5 "Standlueften" 6 "Betriebsart_X" 7 "Betriebsart_Y" ;
VAL_ 1649 KL_Stopp_Wiederstart_Anz_01 0 "keine_Anzeige" 1 "Geblaese" ;
VAL_ 1649 KL_Stopp_Wiederstart_Anz_02 0 "keine_Anzeige" 1 "Differenz_Soll_Ausblas_zu_Ist_Ausblastemperatur" ;
VAL_ 1649 KL_Stopp_Wiederstart_Anz_03 0 "keine_Anzeige" 1 "Beschlagsgefahr" ;
VAL_ 1649 KL_Stopp_Wiederstart_Anz_04 0 "keine_Anzeige" 1 "Differenz_Soll_Innentemperatur_zu_Ist_Innenraumtemperatur" ;
VAL_ 1649 KL_Stopp_Wiederstart_Anz_05 0 "keine_Anzeige" 1 "Komfortfeuchte" ;
VAL_ 1649 KL_Stopp_Wiederstart_Anz_06 0 "keine_Anzeige" 1 "Aussentemperatur" ;
VAL_ 1649 KL_Stopp_Wiederstart_Anz_07 0 "keine_Anzeige" 1 "Defrost" ;
VAL_ 1649 KL_Stopp_Wiederstart_Anz_08 0 "keine_Anzeige" 1 "High_Low" ;
VAL_ 1649 KL_Stopp_Wiederstart_Anz_09 0 "keine_Anzeige" 1 "Frontscheibenheizung" ;
VAL_ 1649 KL_Stopp_Wiederstart_Anz_Std1 0 "keine_Anzeige" 1 "maxA/C" ;
VAL_ 1649 KL_Stopp_Wiederstart_Anz_Std2 0 "keine_Anzeige" 1 "Sitzlueftung" ;
VAL_ 949 KL_Drehz_Anh 0 "keine_Anhebung" 1 "Drehzahlanhebung_vom_Motor_angefordert" ;
VAL_ 949 KL_Vorwarn_Komp_ein 0 "Init" 1 "Vorwarnung_Kompressor_ein" ;
VAL_ 949 KL_AC_Schalter 0 "aus" 1 "ein" ;
VAL_ 949 KL_Komp_Moment_alt 1 "veraltet_bzw_Ermittlung_des_Moments_nicht_moeglich__zB_keine_Drehzahl_kein_Kaeltemitteldruck" ;
VAL_ 949 KL_Vorwarn_Zuheizer_ein 0 "keine_Vorwarnung" 1 "Vorwarnung_Zuheizer_ein" ;
VAL_ 949 KL_Zustand 0 "Aus" 1 "Ein" ;
VAL_ 949 KL_Kompressorkupplung_linear 253 "volle_Ansteuerung" 254 "Init__nicht_bedient" ;
VAL_ 949 KL_Charisma_FahrPr 0 "keine_Funktion" 1 "Programm_1" 2 "Programm_2" 3 "Programm_3" 4 "Programm_4" 5 "Programm_5" 6 "Programm_6" 7 "Programm_7" 8 "Programm_8" 9 "Programm_9" 10 "Programm_10" 11 "Programm_11" 12 "Programm_12" 13 "Programm_13" 14 "Programm_14" 15 "Programm_15" ;
VAL_ 949 KL_Charisma_Status 0 "Init" 1 "verfuegbar" 2 "nicht_verfuegbar" 3 "asynchron_durch_Fahrerwunsch" ;
VAL_ 949 KL_nachtr_Stopp_Anf 0 "nicht_angefordert" 1 "angefordert" ;
VAL_ 949 KL_T_Charge 0 "Taster_nicht_betaetigt" 1 "Taster_betaetigt" ;
VAL_ 949 KL_Last_Kompr 255 "Fehler" ;
VAL_ 949 KL_Spannungs_Anf 0 "keine_Anforderung" 1 "Anforderung_Stufe_1" 2 "Anforderung_Stufe_2" 3 "Anforderung_Stufe_3" ;
VAL_ 949 KL_Thermomanagement 0 "keine_Freigabe_TMM__max_Heizbedarf" 1 "kleine_Freigabe_TMM" 2 "mittlere_Freigabe_TMM" 3 "volle_Freigabe_TMM__kein_Heizbedarf" ;
VAL_ 949 KL_StartStopp_Info 0 "Motorlauf_nicht_notwendig_(Stoppfreigabe)" 1 "Motoranlauf_nicht_zwingend_notwendig_(Stoppverbot,keine_Startanforderung)" 2 "Motoranlauf_zwingend_notwendig_(Startanforderung)" 3 "Systemfehler" ;
VAL_ 949 KL_Freilauf_Info 0 "Freilauf_freigegeben" 1 "Uebergang_in_Freilauf_unzulaessig" 2 "Freilauf_nicht_freigegeben_Abbruch" 3 "Freilauf_Anforderung" ;
VAL_ 949 KL_Anf_KL 255 "Fehler" ;
VAL_ 949 KL_el_Zuheizer_Stufe 0 "Aus" 1 "Stufe_1" 2 "Stufe_2" 3 "Stufe_3" ;
VAL_ 949 KL_Ausstattung_Klima 0 "Heizung_elektrisch" 1 "Klimamanuell_elektrisch" 2 "Climatic__1_Zone" 3 "Climatronic__1_Zone" 4 "Climatronic__2_Zonen" 5 "Climatronic__3_Zonen" 6 "Climatronic__4_Zonen" 7 "reserviert" ;
VAL_ 949 KL_Variante_Standheizung 0 "Wasserstandheizung_60_min_Laufzeit" 1 "Luftstandheizung_120_min_Laufzeit" 2 "Wasserstandheizung_120_min_Laufzeit" 3 "Wasser_und_Luftstandheizung_120_min_Laufzeit" ;
VAL_ 1640 KL_LRH_Taster 0 "nicht_betaetigt" 1 "betaetigt" ;
VAL_ 1640 KL_LRH_Stufe 0 "Stufe_niedrig" 1 "Stufe_mittel" 2 "Stufe_hoch" 3 "AUS" ;
VAL_ 1640 HSH_Taster 0 "nicht_betaetigt" 1 "short_push" 2 "long_push" 3 "tbd" ;
VAL_ 1640 FSH_Taster 0 "nicht_betaetigt" 1 "betaetigt" ;
VAL_ 1640 KL_Zuheizer_Freigabe 0 "keine_Freigabe_Zuheizer" 1 "Zuheizerfreigabe" ;
VAL_ 1640 KL_Beschlagsgefahr 0 "keine_Beschlagsgefahr" 1 "Beschlagsgefahr" ;
VAL_ 1640 KRH_Soll_li 0 "aus" 1 "Stufe_1" 2 "Stufe_2" 3 "Stufe_3" ;
VAL_ 1640 KRH_Soll_re 0 "aus" 1 "Stufe_1" 2 "Stufe_2" 3 "Stufe_3" ;
VAL_ 1640 KL_Geblspng_Soll 0 "0V_Motorspannung" 252 "0V_sofort_Abschalten" 253 "0V_senken_mit_Rampe" 254 "reserviert" 255 "Fehler" ;
VAL_ 1640 KL_Geblspng_Fond_Soll 0 "0V_Motorspannung" 252 "0V_sofort_Abschalten" 253 "0V_senken_mit_Rampe" 254 "reserviert" 255 "Fehler" ;
VAL_ 1640 KL_I_Geblaese 255 "Fehler" ;
VAL_ 1640 KL_Kompressorstrom_soll 1022 "Init" 1023 "Fehler" ;
VAL_ 1640 KL_Umluftklappe_Status 0 "Frischluft" 1 "Teilumluft_10" 2 "Teilumluft_20" 3 "Teilumluft_30" 4 "Teilumluft_40" 5 "Teilumluft_50" 6 "Teilumluft_60" 7 "Teilumluft_70" 8 "Teilumluft_80" 9 "Teilumluft_90" 10 "Umluft" 14 "Init" 15 "Fehler" ;
VAL_ 1640 KL_PTC_Verbauinfo 0 "kein_PTC" 1 "600W_geschaltet" 2 "1000W_geschaltet" 3 "1400W_LIN" ;
VAL_ 1505 BCM1_Aussen_Temp_ungef 253 "nicht_verbaut" 254 "Initwert" 255 "Fehler" ;
VAL_ 1505 BCM_Heizungsabsperrventil_Status 0 "HAV_offen" 1 "HAV_geschlossen" 2 "Init_oder_nicht_verbaut" 3 "Fehler" ;
VAL_ 1505 BCM_Heizungspumpe_Status 0 "Pumpe_aus" 1 "Pumpe_aktiv_und_Stauts_iO" 2 "Init_oder_nicht_verbaut" 3 "Fehler" ;
VAL_ 1505 BCM_Kompressorkupplung_Status 0 "Kupplung_offen" 1 "Kupplung_geschlossen" 2 "Init_oder_nicht_verbaut" 3 "Fehler" ;
VAL_ 1505 BCM1_PTC_stufig_Status 0 "Aus" 1 "Stufe_1_aktiv" 2 "Stufe_2_aktiv" 3 "Stufe_3_aktiv" 6 "Init_oder_nicht_verbaut" 7 "Fehler" ;
VAL_ 1505 BCM1_FStatus_Aussentemp_ungef 0 "iO" 1 "niO" ;
VAL_ 1505 BCM1_Kompressorstrom_ist 254 "Init, bzw. nicht verfuegbar" 255 "Fehler" ;
VAL_ 1505 BCM1_OBD_FStatus_ATemp 0 "kein Fehler / Init / nicht verbaut" 1 "KS- (Kurzschluss nach minus)" 2 "KS+ (Kurzschluss nach plus)" 3 "OC (Leitungsunterbrechung)" 4 "OOR+ (Signal zu gross)" 5 "OOR- (Signal zu klein)" 6 "RC+ (Signal unplausibel zu gross)" 7 "RC- (Signal unplausibel zu klein)" 8 "KS+/OC (Kurzschluss nach plus/Unterbrechung)" 9 "KS-/OC  (Kurzschluss nach minus/Unterbrechung)" 10 "KS-/KS+  (Kurzschluss nach minus/plus)" 11 "KS-/KS+/OC (Kurzschluss nach minus/plus/Unterbrechung)" 12 "frei" 13 "frei" 14 "frei" 15 "frei" ;
VAL_ 2549088302 AEM_KompSchutz 0 "inaktiv" 1 "aktiv" ;
VAL_ 2549088302 AEM_Abschaltstufe 0 "keine_Einschraenkung" 1 "Funktionseinschraenkung" ;
VAL_ 2549088302 AEM_Transport_Mode 0 "keine_Einschraenkung" 1 "Funktionseinschraenkung" ;
VAL_ 2549088302 AEM_Nachlauftyp 0 "Komm_bei_KL15_EIN" 1 "Komm_nach_KL15_AUS" 2 "Komm_bei_KL15_AUS" 4 "Sonderfall" ;
VAL_ 2549088302 AEM_SNI 46 "AEM" ;
VAL_ 2549088302 NM_AEM_Wakeup 0 "Peripherie_Wakeup__Ursache_nicht_bekannt" 1 "Bus_Wakeup" 2 "KL15_HW" ;
VAL_ 2549088302 AEM_Lokalaktiv 0 "war_nicht_lokal_aktiv" 1 "war_lokal_aktiv" ;
VAL_ 2549088302 AEM_Subsystemaktiv 0 "Subsystem_war_nicht_lokalaktiv" 1 "war_lokalaktiv" ;
VAL_ 2549088302 AEM_KD_Fehler 0 "Kein_KD_Fehler" 1 "KD_Fehler" ;
VAL_ 2549088356 AGA_KompSchutz 0 "inaktiv" 1 "aktiv" ;
VAL_ 2549088356 AGA_Abschaltstufe 0 "keine_Einschraenkung" 1 "Funktionseinschraenkung" ;
VAL_ 2549088356 AGA_Transport_Mode 0 "keine_Einschraenkung" 1 "Funktionseinschraenkung" ;
VAL_ 2549088356 AGA_Nachlauftyp 0 "Komm_bei_KL15_EIN" 1 "Komm_nach_KL15_AUS" 2 "Komm_bei_KL15_AUS" ;
VAL_ 2549088356 AGA_SNI 100 "AGA" ;
VAL_ 2549088356 NM_AGA_Wakeup 0 "Peripherie_Wakeup__Ursache_nicht_bekannt" 1 "Bus_Wakeup" 2 "KL15_HW" ;
VAL_ 2549088356 AGA_Lokalaktiv 0 "war_nicht_lokal_aktiv" 1 "war_lokal_aktiv" ;
VAL_ 2549088356 AGA_Subsystemaktiv 0 "Subsystem_war_nicht_lokalaktiv" 1 "war_lokalaktiv" ;
VAL_ 2549088356 AGA_KD_Fehler 0 "kein_KD_Fehler" 1 "KD_Fehler" ;
VAL_ 2549088304 FLA_KompSchutz 0 "inaktiv" 1 "aktiv" ;
VAL_ 2549088304 FLA_Abschaltstufe 0 "keine_Einschraenkung" 1 "Funktionseinschraenkung" ;
VAL_ 2549088304 FLA_Transport_Mode 0 "keine_Einschraenkung" 1 "Funktionseinschraenkung" ;
VAL_ 2549088304 FLA_Nachlauftyp 0 "Komm_bei_KL15_EIN" 1 "Komm_nach_KL15_AUS" 2 "Komm_bei_KL15_AUS" ;
VAL_ 2549088304 FLA_SNI 48 "FLA" ;
VAL_ 2549088304 NM_FLA_Wakeup 0 "Peripherie_Wakeup__Ursache_nicht_bekannt" 1 "Bus_Wakeup" 2 "KL15_HW" ;
VAL_ 2549088304 FLA_Lokalaktiv 0 "war_nicht_lokal_aktiv" 1 "war_lokal_aktiv" ;
VAL_ 2549088304 FLA_Subsystemaktiv 0 "Subsystem_war_nicht_lokalaktiv" 1 "war_lokalaktiv" ;
VAL_ 2549088304 FLA_KD_Fehler 0 "kein_KD_Fehler" 1 "KD_Fehler" ;
VAL_ 2549088272 Gateway_KompSchutz 0 "inaktiv" 1 "aktiv" ;
VAL_ 2549088272 Gateway_Abschaltstufe 0 "keine_Einschraenkung" 1 "Funktionseinschraenkung" ;
VAL_ 2549088272 Gateway_Transport_Mode 0 "keine_Einschraenkung" 1 "Funktionseinschraenkung" ;
VAL_ 2549088272 Gateway_Nachlauftyp 0 "Komm_bei_KL15_EIN" 1 "Komm_nach_KL15_AUS" 2 "Komm_bei_KL15_AUS" ;
VAL_ 2549088272 Gateway_SNI 16 "Gateway" ;
VAL_ 2549088272 NM_Gateway_Wakeup 0 "Peripherie_Wakeup__Ursache_nicht_bekannt" 1 "Bus_Wakeup" 2 "KL15_HW" 3 "ACAN_Wakeup" 4 "FCAN_Wakeup" 5 "KCAN_Wakeup" 6 "ICAN_Wakeup" 7 "DiagCAN_Wakeup" 8 "ECAN_Wakeup" 9 "Energie_LIN_Wakeup" 10 "Bedien_LIN_Wakeup" 11 "HybridCAN_Wakeup" 12 "Flexray_Wakeup" 13 "MFL_WakeUp" 14 "Ethernet" 15 "DCAN_Wakeup" 16 "K2CAN_Wakeup" 17 "CCAN" 18 "AFSCAN_Wakeup" 19 "LIN1" 20 "LIN2" 21 "LIN3" 22 "LIN4" 23 "LIN5" 24 "LIN6" 25 "FASCAN" 26 "FAS2CAN" 27 "MDKCAN" 32 "FlexRay_Branch1_WakeUp" 33 "FlexRay_Branch2_WakeUp" 34 "FlexRay_Branch3_WakeUp" 35 "FlexRay_Branch4_WakeUp" 36 "FlexRay_Branch5_WakeUp" 37 "FlexRay_Branch6_WakeUp" 38 "FlexRay_Branch7_WakeUp" 39 "FlexRay_Branch8_WakeUp" 40 "FlexRay_Branch9_WakeUp" 41 "FlexRay_Branch10_WakeUp" 42 "FlexRay_Branch11_WakeUp" 43 "FlexRay_Branch12_WakeUp" 44 "FlexRay_Branch13_WakeUp" 45 "FlexRay_Branch14_WakeUp" 46 "FlexRay_Branch15_WakeUp" 47 "FlexRay_Branch16_WakeUp" 128 "Energiemanagement" 129 "Funktionswakeup_OBDC" 130 "Hochvoltenergiemanagement" 131 "CWU_empfangen" 132 "Fuer_Bus_relevanten_FC_empfangen" 133 "OnlineDienst_empfangen" 134 "HV_Aktivieren" 135 "HV_Deaktivieren" 136 "VTS_Suche_DriverCard" 137 "VTS_Hupen_Blinken" 138 "Remote_Vehicle_Status" 139 "Plug_and_Charge" 140 "VTS_Wakeup_Infotainment" 141 "EMHLR" 142 "NFcGW_fordert_OTA_FC_an" 143 "Komponentenschutz" 144 "UserStateServer" 145 "Dimmung" 146 "Kessy" 147 "StandardAussenlicht" 148 "ParkKoordinator" 149 "HVLMDynamicChargingPOI" 150 "HVLMChargingManagementServer" 151 "HVLMExtendedChargingMonitoring" 152 "Zentralverriegelung" 153 "FunctionOnDemand" 154 "IAA" 155 "StandKlimatisierung" 156 "RealTimeMonitor" 157 "Klemmensteuerung" 158 "Fremdladung_erkannt" ;
VAL_ 2549088272 NM_Gateway_Lokalaktiv 0 "war_nicht_lokal_aktiv" 1 "war_lokal_aktiv" ;
VAL_ 2549088272 NM_Gateway_Subsystemaktiv 0 "Subsystem_war_nicht_lokalaktiv" 1 "war_lokalaktiv" ;
VAL_ 2549088272 GW_KD_Fehler 0 "kein_KD_Fehler" 1 "KD_Fehler" ;
VAL_ 2549088295 Nightvision_KompSchutz 0 "inaktiv" 1 "aktiv" ;
VAL_ 2549088295 Nightvision_Abschaltstufe 0 "keine_Einschraenkung" 1 "Funktionseinschraenkung" ;
VAL_ 2549088295 Nightvision_Transport_Mode 0 "keine_Einschraenkung" 1 "Funktionseinschraenkung" ;
VAL_ 2549088295 Nightvision_Nachlauftyp 0 "Komm_bei_KL15_EIN" 1 "Komm_nach_KL15_AUS" 2 "Komm_bei_KL15_AUS" ;
VAL_ 2549088295 Nightvision_SNI 39 "Nightvision" ;
VAL_ 2549088295 NM_Nightvision_Wakeup 0 "Peripherie_Wakeup__Ursache_nicht_bekannt" 1 "Bus_Wakeup" 2 "KL15_HW" ;
VAL_ 2549088295 Nightvision_Lokalaktiv 0 "war_nicht_lokal_aktiv" 1 "war_lokal_aktiv" ;
VAL_ 2549088295 Nightvision_Subsystemaktiv 0 "Subsystem_war_nicht_lokalaktiv" 1 "war_lokalaktiv" ;
VAL_ 2549088295 Nightvision_KD_Fehler 0 "kein_KD_Fehler" 1 "KD_Fehler" ;
VAL_ 2549088267 RDK_KompSchutz 0 "inaktiv" 1 "aktiv" ;
VAL_ 2549088267 RDK_Abschaltstufe 0 "keine_Einschraenkung" 1 "Funktionseinschraenkung" ;
VAL_ 2549088267 RDK_Transport_Mode 0 "keine_Einschraenkung" 1 "Funktionseinschraenkung" ;
VAL_ 2549088267 RDK_Nachlauftyp 0 "Komm_bei_KL15_EIN" 1 "Komm_nach_KL15_AUS" 2 "Komm_bei_KL15_AUS" ;
VAL_ 2549088267 RDK_SNI 11 "RDK" ;
VAL_ 2549088267 KN_RDK_BusKnockOutTimer 255 "BusKnockOut_deaktiviert" ;
VAL_ 2549088267 NM_RDK_Wakeup 0 "Peripherie_Wakeup_Ursache_nicht_bekannt" 1 "Bus_Wakeup" 2 "KL15_HW" ;
VAL_ 2549088267 NM_RDK_Lokalaktiv 0 "war_nicht_lokal_aktiv" 1 "war_lokal_aktiv" ;
VAL_ 2549088267 NM_RDK_Subsystemaktiv 0 "Subsystem_war_nicht_lokalaktiv" 1 "war_lokalaktiv" ;
VAL_ 2549088267 RDK_KD_Fehler 0 "Kein KD_Fehler" 1 "KD_Fehler" ;
VAL_ 2549088361 Rearview_KompSchutz 0 "inaktiv" 1 "aktiv" ;
VAL_ 2549088361 Rearview_Abschaltstufe 0 "keine_Einschraenkung" 1 "Funktionseinschraenkung" ;
VAL_ 2549088361 Rearview_Transport_Mode 0 "keine_Einschraenkung" 1 "Funktionseinschraenkung" ;
VAL_ 2549088361 Rearview_Nachlauftyp 0 "Komm_bei_KL15_EIN" 1 "Komm_nach_KL15_AUS" 2 "Komm_bei_KL15_AUS" ;
VAL_ 2549088361 Rearview_SNI 105 "Rearview" ;
VAL_ 2549088361 KN_Rearview_BusKnockOutTimer 255 "BusKnockOut_deaktiviert" ;
VAL_ 2549088361 NM_Rearview_Wakeup 0 "Peripherie_Wakeup_Ursache_nicht_bekannt" 1 "Bus_Wakeup" 2 "KL15_HW" ;
VAL_ 2549088361 Rearview_Lokalaktiv 0 "war_nicht_lokal_aktiv" 1 "war_lokal_aktiv" ;
VAL_ 2549088361 Rearview_Subsystemaktiv 0 "Subsystem_war_nicht_lokalaktiv" 1 "war_lokalaktiv" ;
VAL_ 2549088361 RV_KD_Fehler 0 "kein_KD_Fehler" 1 "KD_Fehler" ;
VAL_ 2549088284 SAK_KompSchutz 0 "inaktiv" 1 "aktiv" ;
VAL_ 2549088284 SAK_Abschaltstufe 0 "keine_Einschraenkung" 1 "Funktionseinschraenkung" ;
VAL_ 2549088284 SAK_Transport_Mode 0 "keine_Einschraenkung" 1 "Funktionseinschraenkung" ;
VAL_ 2549088284 SAK_Nachlauftyp 0 "Komm_bei_KL15_EIN" 1 "Komm_nach_KL15_AUS" 2 "Komm_bei_KL15_AUS" ;
VAL_ 2549088284 SAK_SNI 28 "SAK" ;
VAL_ 2549088284 NM_SAK_Wakeup 0 "Peripherie_Wakeup__Ursache_nicht_bekannt" 1 "Bus_Wakeup" 2 "KL15_HW" ;
VAL_ 2549088284 SAK_Lokalaktiv 0 "war_nicht_lokal_aktiv" 1 "war_lokal_aktiv" ;
VAL_ 2549088284 SAK_Subsystemaktiv 0 "Subsystem_war_nicht_lokalaktiv" 1 "war_lokalaktiv" ;
VAL_ 2549088284 SAK_KD_Fehler 0 "kein_KD_Fehler" 1 "KD_Fehler" ;
VAL_ 2549088298 SCR_KompSchutz 0 "inaktiv" 1 "aktiv" ;
VAL_ 2549088298 SCR_Abschaltstufe 0 "keine_Einschraenkung" 1 "Funktionseinschraenkung" ;
VAL_ 2549088298 SCR_Transport_Mode 0 "keine_Einschraenkung" 1 "Funktionseinschraenkung" ;
VAL_ 2549088298 SCR_Nachlauftyp 0 "Komm_bei_KL15_EIN" 1 "Komm_nach_KL15_AUS" 2 "Komm_bei_KL15_AUS" ;
VAL_ 2549088298 SCR_SNI 42 "SCR" ;
VAL_ 2549088298 KN_SCR_ECUKnockOutTimer 63 "ECUKnockOut_deaktiviert" ;
VAL_ 2549088298 KN_SCR_BusKnockOut 0 "Funktion_nicht_ausgeloest" 1 "Veto_aktiv" 2 "Funktion_ausgeloest" 3 "Funktion_deaktiviert" ;
VAL_ 2549088298 KN_SCR_BusKnockOutTimer 255 "BusKnockOut_deaktiviert" ;
VAL_ 2549088298 NM_SCR_Wakeup 0 "Peripherie_Wakeup_Ursache_nicht_bekannt" 1 "Bus_Wakeup" 2 "KL15_HW" ;
VAL_ 2549088298 KN_SCR_ECUKnockOut 0 "Funktion_nicht_ausgeloest" 1 "Veto_war_aktiv" 2 "Funktion_ausgeloest" 3 "Funktion_deaktiviert" ;
VAL_ 2549088298 NMH_SCR_Lokalaktiv 0 "war_nicht_lokal_aktiv" 1 "war_lokal_aktiv" ;
VAL_ 2549088298 NMH_SCR_Subsystemaktiv 0 "Subsystem_war_nicht_lokalaktiv" 1 "war_lokalaktiv" ;
VAL_ 2549088298 SCR_KD_Fehler 0 "Kein_KD_Fehler" 1 "KD_Fehler" ;
VAL_ 2549088362 STH_KompSchutz 0 "inaktiv" 1 "aktiv" ;
VAL_ 2549088362 STH_Abschaltstufe 0 "keine_Einschraenkung" 1 "Funktionseinschraenkung" ;
VAL_ 2549088362 STH_Transport_Mode 0 "keine_Einschraenkung" 1 "Funktionseinschraenkung" ;
VAL_ 2549088362 STH_Nachlauftyp 0 "Komm_bei_KL15_EIN" 1 "Komm_nach_KL15_AUS" 2 "Komm_bei_KL15_AUS" ;
VAL_ 2549088362 STH_SNI 106 "STH" ;
VAL_ 2549088362 KN_STH_BusKnockOutTimer 255 "BusKnockOut_deaktiviert" ;
VAL_ 2549088362 NM_STH_Wakeup 0 "Peripherie_Wakeup_Ursache_nicht_bekannt" 1 "Bus_Wakeup" 2 "KL15_HW" 3 "STH_EIN_AUS_Funk" 4 "Datentransfer_Funk" 128 "Anf_Schwalltopf_fuellen" 129 "Anf_Geblaese" 130 "Anf_WaPu_Starten" 131 "Abschalten_Fehlerfall" 132 "STH_STL_Einschalt_Ausschaltwunsc" ;
VAL_ 2549088362 NMH_STH_Lokalaktiv 0 "war_nicht_lokal_aktiv" 1 "war_lokal_aktiv" ;
VAL_ 2549088362 NMH_STH_Subsystemaktiv 0 "Subsystem_war_nicht_lokalaktiv" 1 "war_lokalaktiv" ;
VAL_ 2549088362 STH_KD_Fehler 0 "Kein KD_Fehler" 1 "KD_Fehler" ;
VAL_ 2549088334 SWA_KompSchutz 0 "inaktiv" 1 "aktiv" ;
VAL_ 2549088334 SWA_Abschaltstufe 0 "keine_Einschraenkung" 1 "Funktionseinschraenkung" ;
VAL_ 2549088334 SWA_Transport_Mode 0 "keine_Einschraenkung" 1 "Funktionseinschraenkung" ;
VAL_ 2549088334 SWA_Nachlauftyp 0 "Komm_bei_KL15_EIN" 1 "Komm_nach_KL15_AUS" 2 "Komm_bei_KL15_AUS" ;
VAL_ 2549088334 SWA_SNI 78 "SWA" ;
VAL_ 2549088334 KN_SWA_BusKnockOutTimer 255 "BusKnockOut_deaktiviert" ;
VAL_ 2549088334 NM_SWA_Wakeup 0 "Peripherie_Wakeup__Ursache_nicht_bekannt" 1 "Bus_Wakeup" 2 "KL15_HW" ;
VAL_ 2549088334 SWA_Lokalaktiv 0 "war_nicht_lokal_aktiv" 1 "war_lokal_aktiv" ;
VAL_ 2549088334 SWA_Subsystemaktiv 0 "Subsystem_war_nicht_lokalaktiv" 1 "war_lokalaktiv" ;
VAL_ 2549088334 SWA_KD_Fehler 0 "kein_KD_Fehler" 1 "KD_Fehler" ;
VAL_ 2549088394 SWA_2_KompSchutz 0 "inaktiv" 1 "aktiv" ;
VAL_ 2549088394 SWA_2_Abschaltstufe 0 "keine_Einschraenkung" 1 "Funktionseinschraenkung" ;
VAL_ 2549088394 SWA_2_Transport_Mode 0 "keine_Einschraenkung" 1 "Funktionseinschraenkung" ;
VAL_ 2549088394 SWA_2_Nachlauftyp 0 "Komm_bei_KL15_EIN" 1 "Komm_nach_KL15_AUS" 2 "Komm_bei_KL15_AUS" ;
VAL_ 2549088394 SWA_2_SNI 138 "SWA_2" ;
VAL_ 2549088394 KN_SWA_Slave_BusKnockOutTimer 255 "BusKnockOut_deaktiviert" ;
VAL_ 2549088394 NM_SWA_2_Wakeup 0 "Peripherie_Wakeup__Ursache_nicht_bekannt" 1 "Bus_Wakeup" 2 "KL15_HW" ;
VAL_ 2549088394 SWA_2_Lokalaktiv 0 "war_nicht_lokal_aktiv" 1 "war_lokal_aktiv" ;
VAL_ 2549088394 SWA_2_Subsystemaktiv 0 "Subsystem_war_nicht_lokalaktiv" 1 "war_lokalaktiv" ;
VAL_ 2549088394 SWA_2_KD_Fehler 0 "kein_KD_Fehler" 1 "KD_Fehler" ;
VAL_ 779 KBI_ABS_Lampe 0 "ABS Lampe aus" 1 "ABS Lampe ein" ;
VAL_ 779 KBI_ESP_Lampe 0 "ESP Lampe aus" 1 "ESP Lampe ein" ;
VAL_ 779 KBI_BKL_Lampe 0 "BKL aus" 1 "BKL ein" ;
VAL_ 779 KBI_Airbag_Lampe 0 "Airbag Lampe aus" 1 "Airbag Lampe ein" ;
VAL_ 779 KBI_SILA_gueltig 0 "ungueltig" 1 "gueltig" ;
VAL_ 779 KBI_Vorglueh_System_Lampe 0 "Lampe aus" 1 "Lampe ein" ;
VAL_ 779 KBI_NV_in_Anzeige 0 "NV_nicht_in_Anzeige" 1 "NV_in_Anzeige" ;
VAL_ 779 KBI_Anzeigestatus_ACC 0 "keine_ACC_Anzeige" 1 "ACC_Anzeige_aktiv" ;
VAL_ 779 KBI_Anzeigestatus_GRA 0 "nicht_vorhanden" 1 "Anzeigemoeglichkeit_vorhanden" 2 "reserviert" 3 "Fehler" ;
VAL_ 779 KBI_Tankwarnung 0 "Lampe aus" 1 "Lampe ein" ;
VAL_ 779 KBI_MFA_v_Einheit_01 0 "kmh" 1 "mph" ;
VAL_ 779 KBI_im_Stellgliedtest 0 "kein Stellgliedtest" 1 "Kombi im Stellgliedtest" ;
VAL_ 779 KBI_Anzeigefehler_LDW 0 "nicht vorhanden bzw. unterstützt" 1 "Anzeige iO" 2 "Anzeigefehler" 3 "nicht definiert" ;
VAL_ 779 KBI_Tankwarnung_ungueltig 0 "KBI_Tankwarnung_gueltig" 1 "KBI_Tankwarnung_ungueltig" ;
VAL_ 779 KBI_Handbremse 0 "nicht_angezogen" 1 "angezogen" ;
VAL_ 779 KBI_PLA_in_Anzeige 0 "PLA_nicht_in_Anzeige" 1 "PLA_in_Anzeige" ;
VAL_ 779 KBI_Anzeigefehler_NV 0 "kein_Anzeigefehler" 1 "Anzeigefehler" ;
VAL_ 779 KBI_Anzeigestatus_LIM 0 "nicht_vorhanden" 1 "Anzeigemoeglichkeit_vorhanden" 2 "reserviert" 3 "Fehler" ;
VAL_ 779 KBI_ARA_in_Anzeige 0 "ARA nicht in Anzeige" 1 "ARA in Anzeige" ;
VAL_ 779 KBI_Taster_Lift 0 "nicht_betaetigt" 1 "betaetigt" ;
VAL_ 779 KBI_Taster_Fahrwerk 0 "nicht_betaetigt" 1 "betaetigt" ;
VAL_ 779 KBI_GRA_Hauptschalter 0 "Init" 1 "Hauptschalter_aus" 2 "Hauptschalter_ein" 3 "Fehler" ;
VAL_ 779 KBI_Bestaetigung_ESP_Off 0 "ESP_off_nicht_quittiert" 1 "ESP_off_quittiert" 2 "Abbruch" ;
VAL_ 779 KBI_Einheit_Tacho 0 "km/h" 1 "mph" ;
VAL_ 779 KBI_Konsistenz_ACC 0 "ACC Botschaft konsistent" 1 "ACC Botschaft inkonsistent" ;
VAL_ 779 KBI_Fehler_Anzeige_ACC 0 " iO" 1 "Anzeigefehler ACC" ;
VAL_ 779 KBI_Anzeigefehler_SWA 0 "nicht vorhanden bzw. unterstützt" 1 "Anzeige iO" 2 "Anzeigefehler" 3 "nicht definiert" ;
VAL_ 779 KBI_Systemstatus 0 "KBI_IO" 1 "KBI_System_Failure" ;
VAL_ 1719 KBI_Kilometerstand 1048574 "Init" 1048575 "Fehler" ;
VAL_ 1719 KBI_Standzeit_02 131069 "nicht_verfuegbar" 131070 "Init" 131071 "Fehler" ;
VAL_ 1719 KBI_LVDS_Lock 0 "Init_LVDS_nicht_gelockt" 1 "LVDS_gelockt" ;
VAL_ 1719 KBI_Reserve_Warnung_Sek 0 "Keine_Warnung" 1 "Sekundaere_Reservewarnung" ;
VAL_ 1719 KBI_RDK_Kalibrier_Anf 0 "keine_Kalibrieranforderung" 1 "Kalibrieranforderung" ;
VAL_ 1719 KBI_Inhalt_Tank 126 "Init" 127 "Fehler" ;
VAL_ 1719 KBI_FStatus_Tank 0 "Tankfüllstand i.O." 1 "Tankfüllstand n.i.O" ;
VAL_ 1719 KBI_aktive_Laengsfunktion 0 "Init" 1 "Speedlimiter" 2 "GRA_oder_ACC" 3 "PACCh" 4 "HDC" 5 "p_GRA" 6 "p_Lim" 7 "Umschaltung_GRA_Limiter" ;
VAL_ 1719 KBI_TA_gewaehlt_Fahrer 0 "TA_nicht_gewaehlt_Kombi" 1 "TA_gewaehlt_Kombi" ;
VAL_ 1719 KBI_FoD_PopUP_Quittiert 0 "nicht_quittiert" 1 "Meldung_quittiert" ;
VAL_ 1719 KBI_GRA_im_ACC 0 "GRA_im_ACC_nicht_ausgewaehlt" 1 "GRA_im_ACC_ausgewaehlt" ;
VAL_ 1719 KBI_Oelwechsel_durchgefuehrt 0 "Oelwechsel_nicht_durchgefuehrt" 1 "Oelwechsel_durchgefuehrt" ;
VAL_ 1719 KBI_QBit_Aussen_Temp_gef 0 "gueltiger_Wert" 1 "Ersatz_Init_oder_Fehlerwert" ;
VAL_ 1719 KBI_Aussen_Temp_gef 253 "nicht verbaut" 254 "Init" 255 "Fehler" ;
VAL_ 2527679639 KBI_Weg_Zaehler_F 0 "kein Fehler" 1 "Fehler" ;
VAL_ 2527679639 KBI_Jokerkey 0 "nicht_betaetigt" 1 "betaetigt" ;
VAL_ 2527679639 KBI_RS_Druck_uebernehmen 0 " Druck für Rundstreckenmodue nicht uebernehmen" 1 " Druck für Rundstreckenmodus uebernehmen" ;
VAL_ 2527679639 KBI_RS_Druckauswahl_Aktiv 0 "inaktiv" 1 "aktiv" ;
VAL_ 2527679639 KBI_RS_Mode_fortsetzen 0 "Rundstreckenmodus_nicht_fortsetzen" 1 "Rundstreckenmodus_fortsetzen" ;
VAL_ 2527679639 KBI_Rundstreckenmodus 0 "nicht_angefordert" 1 "angefordert" ;
VAL_ 1614 KBI_HUD_Data_01 0 "Init" ;
VAL_ 1614 KBI_HUD_Data_02 0 "Init" ;
VAL_ 1614 KBI_HUD_Data_03 0 "Init" ;
VAL_ 1614 KBI_HUD_Data_04 0 "Init" ;
VAL_ 1614 KBI_HUD_Data_05 0 "Init" ;
VAL_ 1614 KBI_HUD_Data_06 0 "Init" ;
VAL_ 1614 KBI_HUD_Data_07 0 "Init" ;
VAL_ 1614 KBI_HUD_Data_08 0 "Init" ;
VAL_ 160 EPS_Lenkmoment_AbsReduz 13 "MAX" 14 "Init" 15 "Fehler" ;
VAL_ 160 EPS_FAS_Regelgroesse 62 "Init" 63 "Fehler" ;
VAL_ 160 EPS_FAS_VZ_Regelgroesse 0 "positiv" 1 "negativ" ;
VAL_ 160 EPS_Motormoment 0 "Not_in_use" 254 "Init" 255 "Fehler" ;
VAL_ 160 EPS_Zahnstangen_Pos 4094 "Init" 4095 "Fehler" ;
VAL_ 160 EPS_VZ_Zahnstangenposition 0 "pos_VZ" 1 "neg_VZ" ;
VAL_ 160 EPS_QBit_Zahnstangen_Pos 0 "gueltiger_Wert" 1 "Ersatz_Init_oder_Fehlerwert" ;
VAL_ 160 EPS_Versorgungsstatus 0 "kein_Fehler" 1 "Unterspannung" 2 "Ueberspannung" 3 "Stoerung" ;
VAL_ 160 EPS_Versorgungsspannung 254 "Init" 255 "Fehler" ;
VAL_ 160 EPS_AWA_Status 0 "AWA_deaktiviert" 1 "AWA_Anf_nicht_ausfuehrbar" 2 "Kom_AWA_gestoert" 3 "EPS_bzgl_AWA_funktionsbereit" 4 "AWA_Anf_abgew" 5 "AWA_Momeingriff_1_aktiv" 6 "reserviert" 7 "AWA_Momeingriff_2_aktiv" 8 "AWA_abgewiesen_aufgrund_Momentenpriorisierung" 9 "Anf_abgewiesen_Bedienueblich" 14 "Init" ;
VAL_ 160 EPS_STA_Status 0 "STA_bzw_STP_deaktiviert" 1 "Anf_nicht_ausfuehrbar" 2 "Kommunikationsfehler" 3 "EPS_bzgl_STA_bzw_STP_funktionsbereit" 4 "Anf_abgewiesen_Fehler" 5 "gesperrt" 6 "STA_bzw_STP_Winkeleingriff_aktiv" 7 "gesperrt" 8 "Anf_abgewiesen_Prio" 9 "Anf_abgewiesen_Bedienueblich" 10 "Winkeleingriff_abgebrochen" 11 "Rueckfallmodus_Winkeleingriff" 12 "Notlauf_Winkelregelung_aktiv" 13 "STA_STP_Winkeleingriff_aktiv_2" 14 "Init" 15 "Schnittstellendeaktiverung_UEF" ;
VAL_ 981 BCM1_Kurvenlicht_links_Anf 0 "linkes_Kurvenlicht/Abbiegelicht_durch_BCM1_nicht_angesteuert" 1 "linkes_Kurven/Abbiegelicht_durch_BCM1_angesteuert" ;
VAL_ 981 BCM1_Kurvenlicht_rechts_Anf 0 "rechtes_Kurvenlicht/Abbiegelicht_durch_BCM1_nicht_angesteuert" 1 "rechtes_Kurvenlicht/Abbiegelicht_durch_BCM1_angesteuert" ;
VAL_ 981 BCM1_Standlicht_Anf 0 "Licht_nicht_angefordert" 1 "Licht ist einzuschalten" ;
VAL_ 981 BCM1_Abblendlicht_Anf 0 "Licht_nicht_angefordert" 1 "Licht ist einzuschalten" ;
VAL_ 981 BCM1_Fernlicht_Anf 0 "Licht_nicht_angefordert" 1 "Licht ist einzuschalten" ;
VAL_ 981 BCM1_Nebellicht_Anf 0 "Licht_nicht_angefordert" 1 "Licht ist einzuschalten" ;
VAL_ 981 BCM1_Parklicht_li_Anf 0 "Licht_nicht_angefordert" 1 "Licht ist einzuschalten" ;
VAL_ 981 BCM1_Parklicht_re_Anf 0 "Licht_nicht_angefordert" 1 "Licht ist einzuschalten" ;
VAL_ 981 BCM1_Nebelschluss_Ahg_Anf 0 "Licht_nicht_angefordert" 1 "Licht ist einzuschalten" ;
VAL_ 981 BCM1_Nebelschluss_Fzg_Anf 0 "Licht_nicht_angefordert" 1 "Licht_ist_einzuschalten" ;
VAL_ 981 BCM1_Schlusslicht_Anf 0 "Licht_nicht_angefordert" 1 "Licht ist einzuschalten" ;
VAL_ 981 BCM_Rueckfahrlicht_Anf 0 "Licht_nicht_angefordert" 1 "Licht_angefordert" ;
VAL_ 981 BCM1_Signaturlicht_Anf 0 "Licht_nicht_angefordert" 1 "Licht_ist_einzuschalten" ;
VAL_ 981 BCM1_Umfeldleuchten_Anf 0 "Licht_nicht_angefordert" 1 "Licht_ist_einzuschalten" ;
VAL_ 981 BCM1_Tagfahrlicht_Anf 0 "Licht_nicht_angefordert" 1 "Licht ist einzuschalten" ;
VAL_ 981 BCM1_Regenlicht_Anf 0 "Licht_nicht_angefordert" 1 "Licht ist einzuschalten" ;
VAL_ 981 BCM1_Autobahnlicht_Anf 0 "Licht_nicht_angefordert" 1 "Licht ist einzuschalten" ;
VAL_ 981 BCM1_Touristen_Licht_Anf 0 "Licht_nicht_angefordert" 1 "Anforderung von Touristenlicht" ;
VAL_ 981 BCM1_CH_aktiv 0 "Inaktiv" 1 "Aktiv" ;
VAL_ 981 BCM1_LH_aktiv 0 "Inaktiv" 1 "Aktiv" ;
VAL_ 981 BCM1_Gleitende_Leuchtw_Anf 0 "Aus" 1 "Ein" ;
VAL_ 981 BCM1_GLW_Fernlicht_Anf 0 "Aus" 1 "Ein" ;
VAL_ 981 BCM1_Adaptive_Lichtvert_Anf 0 "Aus" 1 "Ein" ;
VAL_ 981 BCM1_FoD_Sperrung_WiBli 0 "Freigabe_WiBli" 1 "Sperrung_WiBli" 2 "Init" ;
VAL_ 981 BCM1_FOD_Sperrung_Animationen_HL 0 "Freigabe_Animationen" 1 "Sperrung_Animationen" 2 "Init" ;
VAL_ 981 BCM1_Animationssperrung 0 "keine_Sperrung" 1 "Sperrung" ;
VAL_ 981 BCM1_CH_LH_aktiv 0 "Comming_Home_Bzw._Leaving_Home_nicht_aktiv" 1 "Comming Home bzw. Leaving Home aktiv" ;
VAL_ 981 BCM1_Allwetterlicht_Anf 0 "Licht_nicht_angefordert" 1 "Licht_ist_einzuschalten" ;
VAL_ 981 BCM1_Schlusslicht_Signatur 0 "keine_Signatur" 1 "Signatur_1" 2 "Signatur_2" 3 "Signatur_3" 4 "Signatur_4" 5 "Signatur_5" 6 "Signatur_6" 7 "Signatur_7" 8 "Signatur_8" 9 "Signatur_9" 10 "Signatur_10" 11 "Signatur_11" 12 "Signatur_12" 13 "Signatur_13" 14 "Signatur_14" 15 "Signatur_15" ;
VAL_ 1624 LV_Standlicht_Anzeige 0 "nicht aktiv" 1 "aktiv" ;
VAL_ 1624 LV_Abblendlicht_Anzeige 0 "inaktiv" 1 "aktiv" ;
VAL_ 1624 LV_Fernlicht_Anzeige 0 "nicht aktiv" 1 "aktiv" ;
VAL_ 1624 LV_Nebellicht_Anzeige 0 "nicht aktiv" 1 "aktiv" ;
VAL_ 1624 LV_Nebelschlusslicht_Anzeige 0 "nicht aktiv" 1 "aktiv" ;
VAL_ 1624 LV_Tagfahrlicht_Anzeige 0 "nicht aktiv" 1 "aktiv" ;
VAL_ 1624 LV_AFL_aktiv_Anzeige 0 "nicht aktiv" 1 "aktiv" ;
VAL_ 1624 LV_AFL_defekt 0 "OK" 1 "defekt" ;
VAL_ 1624 LV_Blinker_li_def 0 "OK" 1 "defekt" ;
VAL_ 1624 LV_Standlicht_li_def 0 "OK" 1 "defekt" ;
VAL_ 1624 LV_Abblendlicht_li_def 0 "OK" 1 "defekt" ;
VAL_ 1624 LV_Fernlicht_li_def 0 "OK" 1 "defekt" ;
VAL_ 1624 LV_Nebellicht_li_def 0 "OK" 1 "defekt" ;
VAL_ 1624 LV_Blk_li_Seite_def 0 "OK" 1 "defekt" ;
VAL_ 1624 LV_Tagfahrlicht_li_def 0 "OK" 1 "defekt" ;
VAL_ 1624 LV_FLA_aktiv_Anzeige 0 "aus" 1 "ein" ;
VAL_ 1624 LV_FLA_defekt 0 "i.O." 1 "FLA defekt" ;
VAL_ 1624 LV_FLA_Sensor_blockiert 0 "i.O." 1 "FLA-Sensor blockiert" ;
VAL_ 1624 LV_Blinker_re_def 0 "OK" 1 "defekt" ;
VAL_ 1624 LV_Standlicht_re_def 0 "OK" 1 "defekt" ;
VAL_ 1624 LV_Abblendlicht_re_def 0 "OK" 1 "defekt" ;
VAL_ 1624 LV_Fernlicht_re_def 0 "OK" 1 "defekt" ;
VAL_ 1624 LV_Nebellicht_re_def 0 "OK" 1 "defekt" ;
VAL_ 1624 LV_Blk_re_Seite_def 0 "OK" 1 "defekt" ;
VAL_ 1624 LV_Tagfahrlicht_re_def 0 "OK" 1 "defekt" ;
VAL_ 1624 LV_Aussenlicht_def 0 "OK" 1 "defekt" ;
VAL_ 1624 LV_Abblendlicht_TFL_li_def 0 "OK" 1 "defekt" ;
VAL_ 1624 LV_Nebellicht_TFL_li_def 0 "OK" 1 "defekt" ;
VAL_ 1624 LV_Standlicht_TFL_li_def 0 "OK" 1 "defekt" ;
VAL_ 1624 LV_Abblend_Fernlicht_li_def 0 "OK" 1 "defekt" ;
VAL_ 1624 LV_Abblendlicht_TFL_re_def 0 "OK" 1 "defekt" ;
VAL_ 1624 LV_Nebellicht_TFL_re_def 0 "OK" 1 "defekt" ;
VAL_ 1624 LV_Standlicht_TFL_re_def 0 "OK" 1 "defekt" ;
VAL_ 1624 LV_Abblend_Fernlicht_re_def 0 "OK" 1 "defekt" ;
VAL_ 1624 LV_Abbiegelicht_li_def 0 "OK" 1 "defekt" ;
VAL_ 1624 LV_Abbiegelicht_re_def 0 "OK" 1 "defekt" ;
VAL_ 1624 BCM1_Linksverkehr 0 "Rechtsverkehr" 1 "Linksverkehr" ;
VAL_ 1624 BCM1_Licht_Dunkelheit_aktiv 0 "inaktiv" 1 "aktiv" ;
VAL_ 1624 LV_LED_Scheinwerfer_li_def 0 "OK" 1 "defekt" ;
VAL_ 1624 LV_LED_Scheinwerfer_re_def 0 "OK" 1 "defekt" ;
VAL_ 1624 LV_Blinker_VL_aktiv 0 "inaktiv" 1 "aktiv" ;
VAL_ 1624 LV_Blinker_VR_aktiv 0 "inaktiv" 1 "aktiv" ;
VAL_ 1624 LV_MXB_Status_Anzeige 0 "MXB_aus" 1 "MXB_regelt" 2 "MXB_volles_Fernlicht" 3 "MXB_und_Laser_aktiv" ;
VAL_ 134 LWI_Sensorstatus 0 "iO" 1 "nicht kalibriert" ;
VAL_ 134 LWI_QBit_Sub_Daten 0 "LWS-Subinfo real (Lenkradwinkelinformation ADS-tauglich) " 1 "LWS-Subinfo simuliert (Lenkradwinkelinformation nicht ADS-tauglich )" ;
VAL_ 134 LWI_MFL_Abschaltung 0 "inaktiv" 1 "aktiv" ;
VAL_ 134 LWI_QBit_Lenkradwinkel 0 "gültiger Wert" 1 "ausserhalb der Spezifikation" ;
VAL_ 134 LWI_Lenkradwinkel 8190 "Init" 8191 "Fehler" ;
VAL_ 134 LWI_VZ_Lenkradwinkel 0 "positiv_links_von_der_Nullstellung" 1 "negativ" ;
VAL_ 134 LWI_VZ_Lenkradw_Geschw 0 "positiv_links_von_der_Nullstellung" 1 "negativ" ;
VAL_ 134 LWI_Lenkradw_Geschw 510 "Init" 511 "Fehler" ;
